VERSION ""

NS_ :

BS_:

BU_: CCU NIDU ITS EOP BMC BCB EVCC DCDC DCDC2 Tester DCU CCURT2 ZCUF ZCUL ZCUR ZCUT IPS RBM IBCS IDC CCU3 CCU4 AVAS FLLCM FRLCM RLLCMA RRLCMA RLLCMB RRLCMB PADS MFS PCU SRS EPS ECS AMP WHUD IMR FIMR ADC VIU RADARRR RADARRL RADARFR RADARFL RPC IFC PAS RADARFRT RADARR INU SBM WCM ETC TBOX DSM FLPDM FRPDM RLPDM RRPDM HVSMR TFOAR TROAR PLGM CCURT1 VDC RFR Rema1

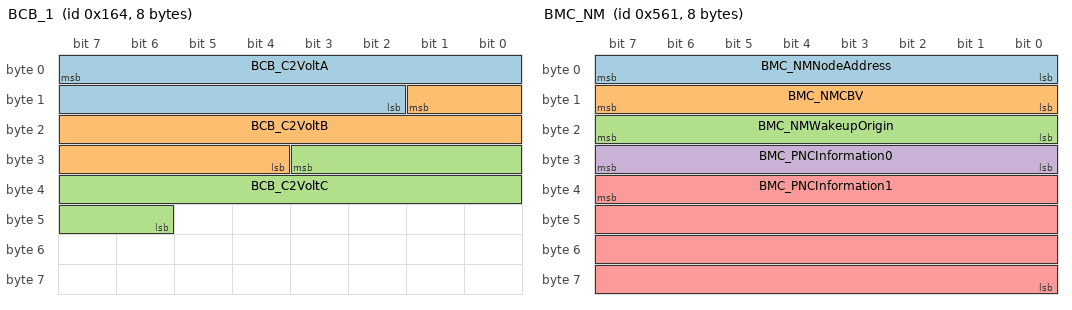
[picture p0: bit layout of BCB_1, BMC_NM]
BO_ 356 BCB_1: 8 BCB
 SG_ BCB_C2VoltA : 7|14@0+ (0.1,0) [0|1000] "V"  CCU,NIDU,BMC,DCU,CCURT1,VDC
 SG_ BCB_C2VoltB : 9|14@0+ (0.1,0) [0|1000] "V"  CCU,NIDU,BMC,DCU,CCURT1,VDC
 SG_ BCB_C2VoltC : 27|14@0+ (0.1,0) [0|1000] "V"  CCU,NIDU,BMC,DCU,CCURT1,VDC

BO_ 1025 BCB_2: 16 BCB
 SG_ BCB_2_CRC : 7|16@0+ (1,0) [0|65535] ""  CCU,NIDU,BMC,DCU,CCURT1,VDC
 SG_ BCB_2_Counter : 23|8@0+ (1,0) [0|255] ""  CCU,NIDU,BMC,DCU,CCURT1,VDC
 SG_ BCB_BoostRlyStK3 : 28|3@0+ (1,0) [0|7] ""  CCU,NIDU,BMC,DCU,CCURT1,VDC
 SG_ BCB_BoostRlyStK2 : 31|3@0+ (1,0) [0|7] ""  CCU,NIDU,BMC,DCU,CCURT1,VDC
 SG_ BCB_C2Temp1 : 25|9@0+ (1,-40) [-40|256] "degC"  NIDU,DCU
 SG_ BCB_C2Temp2 : 32|9@0+ (1,-40) [-40|256] "degC"  NIDU,DCU
 SG_ BCB_C2Temp3 : 55|9@0+ (1,-40) [-40|256] "degC"  NIDU,DCU
 SG_ BCB_Fault : 67|4@0+ (1,0) [0|15] ""  CCU,NIDU,BMC,DCU,CCURT1,VDC
 SG_ BCB_C2Temp4 : 62|9@0+ (1,-40) [-40|256] "degC"  NIDU,DCU

BO_ 408 BMC_1: 64 BMC
 SG_ BMC_1_CRC : 7|16@0+ (1,0) [0|65535] ""  CCU,NIDU,EVCC,DCDC,DCDC2,DCU,IPS,CCURT1,VDC
 SG_ BMC_1_Counter : 23|8@0+ (1,0) [0|255] ""  CCU,NIDU,EVCC,DCDC,DCDC2,DCU,IPS,CCURT1,VDC
 SG_ BMC_BattCurr : 24|16@0+ (0.1,-1000) [-1000|1000] "A"  CCU,NIDU,DCU,CCURT2,IDC,CCURT1,VDC
 SG_ BMC_DCUBattSt : 56|1@0+ (1,0) [0|1] ""  CCU,NIDU,DCDC,DCDC2,DCU,CCURT2,IPS,CCURT1,VDC
 SG_ BMC_BattVolt : 54|10@0+ (1,0) [0|1000] "V"  CCU,NIDU,EVCC,DCU,CCURT2,IDC,CCURT1,VDC
 SG_ BMC_BoostChgModeReq : 68|2@0+ (1,0) [0|3] ""  CCU,NIDU,DCU,CCURT2,CCURT1,VDC
 SG_ BMC_PwrDwnReq : 71|1@0+ (1,0) [0|1] ""  CCU,NIDU,DCDC,DCDC2,DCU,IPS,CCURT1,VDC
 SG_ BMC_BoostRlyK3St : 76|3@0+ (1,0) [0|7] ""  CCU,NIDU,DCU,CCURT2,CCURT1,VDC
 SG_ BMC_BoostRlyK2St : 97|3@0+ (1,0) [0|7] ""  CCU,NIDU,DCU,CCURT2,CCURT1,VDC
 SG_ BMC_DCVolt : 110|10@0+ (1,0) [0|1000] "V"  CCU,NIDU,DCU,CCURT2,CCURT1,VDC
 SG_ BMC_DriveBoostRlyK3Sts : 298|2@0+ (1,0) [0|3] ""  CCU,NIDU,DCU,CCURT1,VDC
 SG_ BMC_BoostRlyK3Sts : 301|3@0+ (1,0) [0|7] ""  CCU,NIDU,DCU,CCURT1,VDC
 SG_ BMC_C2VoltA : 391|10@0+ (1,0) [0|1000] "V"  CCU,NIDU,DCU,CCURT1,VDC
 SG_ BMC_C2VoltB : 397|10@0+ (1,0) [0|1000] "V"  CCU,NIDU,DCU,CCURT1,VDC
 SG_ BMC_DriveBoostRlyK2Sts : 409|2@0+ (1,0) [0|3] ""  CCU,NIDU,DCU,CCURT1,VDC
 SG_ BMC_C2VoltC : 403|10@0+ (1,0) [0|1000] "V"  CCU,NIDU,DCU,CCURT1,VDC
 SG_ BMC_BoostRlyK2Sts : 434|3@0+ (1,0) [0|7] ""  CCU,NIDU,DCU,CCURT1,VDC

BO_ 888 BMC_2: 64 BMC
 SG_ BMC_SepaHeatSt : 133|2@0+ (1,0) [0|3] ""  CCU,NIDU,IPS,CCURT1,VDC

BO_ 1095 BMC_20: 64 BMC
 SG_ BMC_RlyK3Req : 497|2@0+ (1,0) [0|3] ""  CCU,NIDU,BCB,DCU,CCURT1,VDC
 SG_ BMC_MainloopDischgReq : 505|2@0+ (1,0) [0|3] ""  CCU,NIDU,DCU,CCURT1,VDC
 SG_ BMC_C2DisChgSt : 507|2@0+ (1,0) [0|3] ""  CCU,NIDU,DCU,CCURT1,VDC
 SG_ BMC_BoostChgSt : 509|2@0+ (1,0) [0|3] ""  CCU,NIDU,DCU,CCURT1,VDC
 SG_ BMC_RlyK2Req : 511|2@0+ (1,0) [0|3] ""  CCU,NIDU,BCB,DCU,CCURT1,VDC

BO_ 1098 BMC_23: 64 BMC
 SG_ BMC_C2Temp1 : 471|9@0+ (1,-40) [-40|256] "degC"  CCU,NIDU,DCU,CCURT1,VDC
 SG_ BMC_C2Temp2 : 478|9@0+ (1,-40) [-40|256] "degC"  CCU,NIDU,DCU,CCURT1,VDC
 SG_ BMC_C2Temp3 : 485|9@0+ (1,-40) [-40|256] "degC"  CCU,NIDU,DCU,CCURT1,VDC
 SG_ BMC_BCBFault : 499|4@0+ (1,0) [0|15] ""  CCU,NIDU,DCU,CCURT1,VDC
 SG_ BMC_C2Temp4 : 492|9@0+ (1,-40) [-40|256] "degC"  CCU,NIDU,DCU,CCURT1,VDC

BO_ 812 BMC_BMS_3: 64 BMC
 SG_ BMS_DCCurrRx : 31|16@0+ (0.1,-1000) [-1000|1000] "A"  CCU,NIDU,BMC,DCU,CCURT2,CCURT1,VDC
 SG_ BMS_DCVoltRx : 47|16@0+ (0.1,0) [0|1000] "V"  CCU,NIDU,BMC,DCU,CCURT2,CCURT1,VDC
 SG_ BMS_AcChgVoltMax : 79|16@0+ (0.1,0) [0|6553.5] "V"  CCU,NIDU,BMC,DCU,CCURT1,VDC
 SG_ BMS_BoostChgModeReq : 149|2@0+ (1,0) [0|3] ""  CCU,NIDU,BMC,DCU,CCURT1,VDC
 SG_ BMS_CoolantTargTemp : 159|8@0+ (0.5,-40) [-40|87] "degC"  CCU,NIDU,BMC,DCU,CCURT2,CCURT1,VDC

BO_ 1377 BMC_NM: 8 BMC
 SG_ BMC_NMNodeAddress : 7|8@0+ (1,0) [0|255] ""  CCU,NIDU,ITS,EVCC,DCDC,DCDC2,DCU,IPS,CCURT1
 SG_ BMC_NMCBV : 15|8@0+ (1,0) [0|0] ""  CCU,NIDU,ITS,EVCC,DCDC,DCDC2,DCU,IPS,CCURT1
 SG_ BMC_NMWakeupOrigin : 23|8@0+ (1,0) [0|255] ""  CCU,NIDU,ITS,EVCC,DCDC,DCDC2,DCU,IPS,CCURT1
 SG_ BMC_PNCInformation0 : 31|8@0+ (1,0) [0|255] ""  CCU,NIDU,ITS,EVCC,DCDC,DCDC2,DCU,IPS,CCURT1
 SG_ BMC_PNCInformation1 : 39|32@0+ (1,0) [0|0] ""  CCU,NIDU,ITS,EVCC,DCDC,DCDC2,DCU,IPS,CCURT1

BO_ 616 CCU_1: 64 CCU
 SG_ CCU_1_CRC : 7|16@0+ (1,0) [0|65535] ""  NIDU,DCU,CCURT2,ZCUF,ZCUL,ZCUR,ZCUT,IPS,RBM,IBCS,IDC
 SG_ CCU_1_Counter : 23|8@0+ (1,0) [0|255] ""  NIDU,DCU,CCURT2,ZCUF,ZCUL,ZCUR,ZCUT,IPS,RBM,IBCS,IDC
 SG_ UMM_UsageModeSt : 26|3@0+ (1,0) [0|7] ""  NIDU,ITS,EOP,BMC,BCB,DCDC,DCDC2,DCU,CCURT2,ZCUF,ZCUL,ZCUR,ZCUT,IPS,RBM,IBCS,IDC,CCU3,CCU4,AVAS,FLLCM,FRLCM,RLLCMA,RRLCMA,RLLCMB,RRLCMB,PADS,MFS,PCU,SRS,EPS,ECS,AMP,WHUD,IMR,FIMR,ADC,VIU,RADARRR,RADARRL,RADARFR,RADARFL,RPC,IFC,PAS,RADARFRT,RADARR,INU,SBM,WCM,ETC,TBOX,DSM,FLPDM,FRPDM,RLPDM,RRPDM,HVSMR,TFOAR,TROAR,PLGM
 SG_ VMM_LastVehModeSt : 155|4@0+ (1,0) [0|15] ""  NIDU,ITS,EOP,BMC,DCDC,DCU,ZCUF,ZCUL,ZCUR,ZCUT,IPS,RBM,IBCS,IDC,AVAS,FLLCM,FRLCM,RLLCMA,RRLCMA,RLLCMB,RRLCMB,PADS,MFS,PCU,SRS,EPS,AMP,WHUD,ADC,VIU,RADARRR,RADARRL,RADARFR,RADARFL,RPC,IFC,RADARFRT,RADARR,INU,SBM,WCM,ETC,TBOX,DSM,FLPDM,FRPDM,RLPDM,RRPDM,HVSMR,TFOAR,TROAR
 SG_ VMM_VehModeSt : 159|4@0+ (1,0) [0|15] ""  NIDU,ITS,EOP,BMC,BCB,DCDC,DCDC2,DCU,CCURT2,ZCUF,ZCUL,ZCUR,ZCUT,IPS,RBM,IBCS,IDC,AVAS,FLLCM,FRLCM,RLLCMA,RRLCMA,RLLCMB,RRLCMB,PADS,MFS,PCU,SRS,EPS,ECS,AMP,WHUD,IMR,FIMR,ADC,VIU,RADARRR,RADARRL,RADARFR,RADARFL,RPC,IFC,RADARFRT,RADARR,INU,SBM,WCM,ETC,TBOX,DSM,FLPDM,FRPDM,RLPDM,RRPDM,HVSMR,TFOAR,TROAR,PLGM
 SG_ VMM_OTAModeSt : 167|2@0+ (1,0) [0|3] ""  NIDU,ITS,EOP,BMC,BCB,DCDC,DCDC2,DCU,CCURT2,ZCUF,ZCUL,ZCUR,ZCUT,IPS,RBM,IBCS,IDC,AVAS,FLLCM,FRLCM,RLLCMA,RRLCMA,RLLCMB,RRLCMB,PADS,MFS,PCU,SRS,EPS,ECS,AMP,WHUD,ADC,VIU,RADARRR,RADARRL,RADARFR,RADARFL,RPC,IFC,RADARFRT,RADARR,INU,SBM,WCM,ETC,TBOX,DSM,FLPDM,FRPDM,RLPDM,RRPDM,HVSMR,TFOAR,TROAR
 SG_ Time_Year : 343|8@0+ (1,2000) [2000|2255] "y"  NIDU,ITS,EOP,BMC,DCU,CCURT2,ZCUF,ZCUL,ZCUR,ZCUT,IPS,RBM,IBCS,FLLCM,FRLCM,RLLCMA,RRLCMA,RLLCMB,RRLCMB,MFS,PCU,SRS,EPS,ECS,AMP,IMR,FIMR,ADC,VIU,RPC,IFC,PAS,INU,DSM,FLPDM,FRPDM,RLPDM,RRPDM,HVSMR,TFOAR,TROAR,CCURT1
 SG_ Time_Month : 351|4@0+ (1,0) [0|12] "m"  NIDU,ITS,EOP,BMC,DCU,CCURT2,ZCUF,ZCUL,ZCUR,ZCUT,IPS,RBM,IBCS,FLLCM,FRLCM,RLLCMA,RRLCMA,RLLCMB,RRLCMB,MFS,PCU,SRS,EPS,ECS,AMP,IMR,FIMR,ADC,VIU,RPC,IFC,PAS,INU,DSM,FLPDM,FRPDM,RLPDM,RRPDM,HVSMR,TFOAR,TROAR,CCURT1
 SG_ Time_Hour : 358|5@0+ (1,0) [0|23] "h"  NIDU,ITS,EOP,BMC,DCU,CCURT2,ZCUF,ZCUL,ZCUR,ZCUT,IPS,RBM,IBCS,FLLCM,FRLCM,RLLCMA,RRLCMA,RLLCMB,RRLCMB,MFS,PCU,SRS,EPS,ECS,AMP,IMR,FIMR,ADC,VIU,RPC,IFC,PAS,INU,DSM,FLPDM,FRPDM,RLPDM,RRPDM,HVSMR,TFOAR,TROAR,CCURT1
 SG_ Time_Day : 347|5@0+ (1,0) [1|31] "d"  NIDU,ITS,EOP,BMC,DCU,CCURT2,ZCUF,ZCUL,ZCUR,ZCUT,IPS,RBM,IBCS,FLLCM,FRLCM,RLLCMA,RRLCMA,RLLCMB,RRLCMB,MFS,PCU,SRS,EPS,ECS,AMP,IMR,FIMR,ADC,VIU,RPC,IFC,PAS,INU,DSM,FLPDM,FRPDM,RLPDM,RRPDM,HVSMR,TFOAR,TROAR,CCURT1
 SG_ Time_Min : 353|6@0+ (1,0) [0|59] "min"  NIDU,ITS,EOP,BMC,DCU,CCURT2,ZCUF,ZCUL,ZCUR,ZCUT,IPS,RBM,IBCS,FLLCM,FRLCM,RLLCMA,RRLCMA,RLLCMB,RRLCMB,MFS,PCU,SRS,EPS,ECS,AMP,IMR,FIMR,ADC,VIU,RPC,IFC,PAS,INU,DSM,FLPDM,FRPDM,RLPDM,RRPDM,HVSMR,TFOAR,TROAR,CCURT1
 SG_ Time_Sec : 363|6@0+ (1,0) [0|59] "s"  NIDU,ITS,EOP,BMC,DCU,CCURT2,ZCUF,ZCUL,ZCUR,ZCUT,IPS,RBM,IBCS,FLLCM,FRLCM,RLLCMA,RRLCMA,RLLCMB,RRLCMB,MFS,PCU,SRS,EPS,ECS,AMP,IMR,FIMR,ADC,VIU,RPC,IFC,PAS,INU,DSM,FLPDM,FRPDM,RLPDM,RRPDM,HVSMR,TFOAR,TROAR,CCURT1

BO_ 816 CCU_2: 64 CCU
 SG_ HVAC_PTCPwrConsmp : 65|10@0+ (10,0) [0|10200] "W"  NIDU,CCURT2,ZCUR,IPS,IDC,CCURT1
 SG_ HVAC_CorrectedExterTemp : 135|8@0+ (0.5,-40) [-40|87.5] "degC"  NIDU,ITS,BMC,DCU,CCURT2,ZCUL,ZCUR,ZCUT,IBCS,IDC,ECS,ADC,VIU,PAS,TBOX,DSM,FLPDM,FRPDM,RLPDM,RRPDM,TFOAR,TROAR,CCURT1
 SG_ HVAC_PTCHeatingReq : 142|7@0+ (1,0) [0|100] "%"  NIDU,DCU,ZCUF,ZCUL,CCURT1
 SG_ HVAC_CorrectedExterTempVD : 143|1@0+ (1,0) [0|1] ""  NIDU,ITS,BMC,DCU,CCURT2,ZCUL,ZCUR,ZCUT,IBCS,IDC,ADC,VIU,PAS,DSM,FLPDM,FRPDM,RLPDM,RRPDM,TFOAR,TROAR,CCURT1
 SG_ HVAC_PTCSt : 168|1@0+ (1,0) [0|1] ""  NIDU,DCU,CCURT2,CCURT1
 SG_ HVAC_ECPPwrConsump : 367|11@0+ (10,0) [0|20320] "W"  NIDU,DCU,CCURT2,IPS,IDC,CCURT1
 SG_ HVAC_PTCOnReq : 427|2@0+ (1,0) [0|3] ""  NIDU,DCU,ZCUF,ZCUL,IPS

BO_ 615 CCU_BCS_1_C: 64 CCU
 SG_ BCS_1_CRC : 7|16@0+ (1,0) [0|65535] ""  NIDU,DCU,ZCUF,ZCUL,ZCUR,ZCUT,IDC,ADC,VIU,IFC,INU
 SG_ BCS_1_Counter : 23|8@0+ (1,0) [0|255] ""  NIDU,DCU,ZCUF,ZCUL,ZCUR,ZCUT,IDC,ADC,VIU,IFC,INU
 SG_ BCS_FLWheelSpdVD : 34|1@0+ (1,0) [0|1] ""  NIDU,DCU,ZCUF,ZCUL,ZCUR,ZCUT,ADC,VIU,IFC,INU
 SG_ BCS_FLWheelSpd : 31|13@0+ (0.05625,0) [0|240] "km/h"  NIDU,DCU,ZCUF,ZCUL,ZCUR,ZCUT,IDC,ADC,VIU,IFC,INU
 SG_ BCS_FRWheelSpdVD : 50|1@0+ (1,0) [0|1] ""  NIDU,DCU,ZCUF,ZCUL,ZCUR,ZCUT,ADC,VIU,IFC,INU
 SG_ BCS_FRWheelSpd : 47|13@0+ (0.05625,0) [0|240] "km/h"  NIDU,DCU,ZCUF,ZCUL,ZCUR,ZCUT,IDC,ADC,VIU,IFC,INU
 SG_ BCS_RLWheelSpdVD : 66|1@0+ (1,0) [0|1] ""  NIDU,DCU,ZCUF,ZCUL,ZCUR,ZCUT,ADC,VIU,IFC,INU
 SG_ BCS_RLWheelSpd : 63|13@0+ (0.05625,0) [0|240] "km/h"  NIDU,DCU,ZCUF,ZCUL,ZCUR,ZCUT,IDC,ADC,VIU,IFC,INU
 SG_ BCS_RRWheelSpdVD : 82|1@0+ (1,0) [0|1] ""  NIDU,DCU,ZCUF,ZCUL,ZCUR,ZCUT,ADC,VIU,IFC,INU
 SG_ BCS_RRWheelSpd : 79|13@0+ (0.05625,0) [0|240] "km/h"  NIDU,DCU,ZCUF,ZCUL,ZCUR,ZCUT,IDC,ADC,VIU,IFC,INU
 SG_ BCS_HDCCtrlSt : 93|2@0+ (1,0) [0|3] ""  NIDU,DCU,IDC,ADC,VIU,IFC
 SG_ BCS_HHCCtrlSt : 95|1@0+ (1,0) [0|1] ""  NIDU,DCU,IFC
 SG_ BCS_AVHSt : 152|1@0+ (1,0) [0|1] ""  NIDU,DCU,ZCUF,ZCUL,ZCUR,ZCUT,IDC,ADC,VIU,IFC,SBM
 SG_ IPB_InputRodStroke : 363|10@0+ (0.05,-5) [-5|46.15] "mm"  NIDU,DCU,IDC,AMP,ADC,VIU,IFC
 SG_ IPB_PlungerPressureSt : 376|1@0+ (1,0) [0|1] ""  NIDU,DCU,ZCUF,ZCUL,ZCUR,ZCUT,RBM,ADC,VIU,IFC
 SG_ IPB_InputRodStrokeSt : 379|1@0+ (1,0) [0|1] ""  NIDU,DCU,IDC,AMP,ADC,VIU,IFC
 SG_ IPB_PlungerPressure : 391|12@0+ (0.3,-5) [-5|301.9] "bar"  NIDU,DCU,ZCUF,ZCUL,ZCUR,ZCUT,RBM,ADC,VIU,IFC

BO_ 352 CCU_BCS_2_C: 64 CCU
 SG_ BCS_2_CRC : 7|16@0+ (1,0) [0|65535] ""  NIDU,DCU,ZCUF,ZCUL,ZCUR,ZCUT,IDC,FLLCM,FRLCM,RLLCMA,RRLCMA,RLLCMB,RRLCMB,ADC,VIU,IFC,INU,FLPDM,FRPDM,RLPDM,RRPDM,TFOAR,TROAR
 SG_ BCS_2_Counter : 23|8@0+ (1,0) [0|255] ""  NIDU,DCU,ZCUF,ZCUL,ZCUR,ZCUT,IDC,ADC,VIU,IFC,INU
 SG_ BCS_EBDActiveSt : 32|1@0+ (1,0) [0|1] ""  NIDU,DCU,ZCUF,ZCUL,ZCUR,ZCUT,ADC,VIU,IFC
 SG_ BCS_VehSpd : 31|13@0+ (0.05625,0) [0|240] "km/h"  NIDU,ITS,DCU,ZCUF,ZCUL,ZCUR,ZCUT,IDC,FLLCM,FRLCM,RLLCMA,RRLCMA,RLLCMB,RRLCMB,MFS,PCU,AMP,IMR,FIMR,ADC,VIU,IFC,PAS,INU,FLPDM,FRPDM,RLPDM,RRPDM,TFOAR,TROAR,PLGM
 SG_ BCS_VDCFaultSt : 41|1@0+ (1,0) [0|1] ""  NIDU,DCU,ZCUF,ZCUL,ZCUR,ZCUT,IDC,ADC,VIU,IFC
 SG_ BCS_VDCActiveSt : 42|1@0+ (1,0) [0|1] ""  NIDU,DCU,ZCUF,ZCUL,ZCUR,ZCUT,IDC,ADC,VIU,IFC
 SG_ BCS_TCSFaultSt : 43|1@0+ (1,0) [0|1] ""  NIDU,DCU,ZCUF,ZCUL,ZCUR,ZCUT,IDC,ADC,VIU,IFC
 SG_ BCS_TCSActiveSt : 44|1@0+ (1,0) [0|1] ""  NIDU,DCU,ZCUF,ZCUL,ZCUR,ZCUT,IDC,ADC,VIU,IFC
 SG_ BCS_ABSFaultSt : 45|1@0+ (1,0) [0|1] ""  NIDU,DCU,ZCUF,ZCUL,ZCUR,ZCUT,IDC,ADC,VIU,IFC
 SG_ BCS_ABSActiveSt : 46|1@0+ (1,0) [0|1] ""  NIDU,DCU,ZCUF,ZCUL,ZCUR,ZCUT,ADC,VIU,IFC,TBOX
 SG_ BCS_EBDFaultSt : 47|1@0+ (1,0) [0|1] ""  NIDU,DCU,ZCUF,ZCUL,ZCUR,ZCUT,IDC,ADC,VIU,IFC
 SG_ BCS_EngTorqDecActiveSt : 71|1@0+ (1,0) [0|1] ""  NIDU,DCU,ZCUF,ZCUL,ZCUR,ZCUT,ADC,VIU,IFC
 SG_ BCS_RegenModuleActive : 79|1@0+ (1,0) [0|1] ""  NIDU,DCU,VIU
 SG_ BCS_DMCTarSpdFA : 135|16@0+ (1,-32767) [-32767|32768] "rpm"  NIDU,DCU
 SG_ BCS_DMCCtrModeFA : 151|3@0+ (1,0) [0|7] "NA"  NIDU,DCU
 SG_ BCS_DMCVariant : 148|6@0+ (1,0) [0|63] "NA"  NIDU,DCU
 SG_ BCS_DMCTarSpdRA : 167|16@0+ (1,-32767) [-32767|32768] "rpm"  NIDU,DCU
 SG_ BCS_DMCCtrModeRA : 183|3@0+ (1,0) [0|7] "NA"  NIDU,DCU
 SG_ BCS_EngTorqDecActiveStRA : 233|1@0+ (1,0) [0|1] ""  NIDU,DCU,ADC,VIU,IFC

BO_ 363 CCU_EPS_1_C: 64 CCU
 SG_ EPS_SteeringAngle : 55|16@0+ (0.1,-780) [-780|779.9] "deg"  NIDU,DCU,ZCUR,SBM
 SG_ EPS_SteeringAngleVD : 71|1@0+ (1,0) [0|1] ""  NIDU,DCU,ZCUR,SBM

BO_ 351 CCU_IDC_2: 64 CCU
 SG_ ACU_ACChgCurCfg : 151|5@0+ (1,0) [0|31] ""  NIDU,IPS

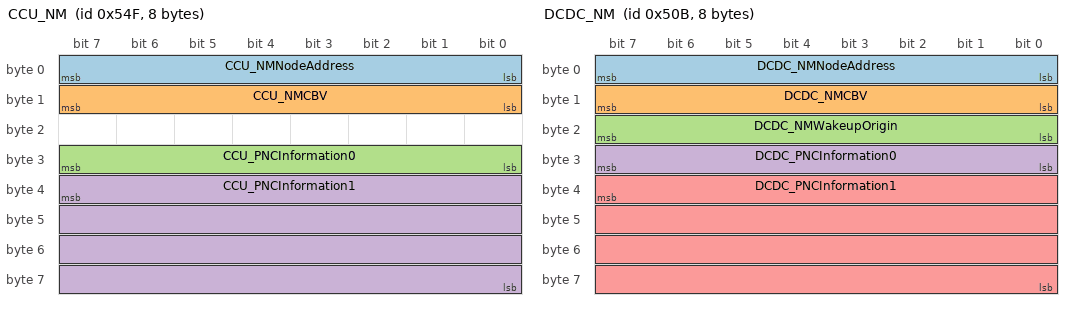
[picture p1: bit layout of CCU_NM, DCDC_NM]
BO_ 1359 CCU_NM: 8 CCU
 SG_ CCU_NMNodeAddress : 7|8@0+ (1,0) [0|255] ""  NIDU,ITS,BMC,EVCC,DCDC,DCDC2,DCU,ZCUL,ZCUR,IPS,RBM,IBCS,IDC,MFS,PCU,ECS,AMP,ADC,VIU,IFC,TBOX,FLPDM,FRPDM,RLPDM,RRPDM,PLGM,CCURT1
 SG_ CCU_NMCBV : 15|8@0+ (1,0) [0|0] ""  NIDU,ITS,BMC,EVCC,DCDC,DCDC2,DCU,ZCUL,ZCUR,IPS,RBM,IBCS,IDC,MFS,PCU,ECS,ADC,VIU,IFC,TBOX,FLPDM,FRPDM,RLPDM,RRPDM,PLGM,CCURT1
 SG_ CCU_PNCInformation0 : 31|8@0+ (1,0) [0|255] ""  NIDU,ITS,BMC,EVCC,DCDC,DCDC2,DCU,ZCUL,ZCUR,IPS,RBM,IBCS,IDC,MFS,PCU,ECS,ADC,VIU,IFC,TBOX,FLPDM,FRPDM,RLPDM,RRPDM,PLGM,CCURT1
 SG_ CCU_PNCInformation1 : 39|32@0+ (1,0) [0|0] ""  NIDU,ITS,BMC,EVCC,DCU,ZCUL,ZCUR,IPS,RBM,IBCS,IDC,MFS,PCU,ECS,ADC,VIU,IFC,TBOX,FLPDM,FRPDM,RLPDM,RRPDM,PLGM,CCURT1

BO_ 290 CCU_PowerOn: 64 CCU
 SG_ IPDS_RearEOPPowerSup : 131|2@0+ (1,0) [0|3] ""  NIDU,DCU,ZCUR,ZCUT
 SG_ IPDS_KL15T1PowerSup : 169|2@0+ (1,0) [0|3] ""  NIDU,DCU,ZCUR,ZCUT,CCURT1,VDC
 SG_ IPDS_BCBPowerSup : 271|2@0+ (1,0) [0|3] ""  NIDU,BMC,BCB,DCU,ZCUR,ZCUT
 SG_ IPDS_FrontEOPPowerSup : 283|2@0+ (1,0) [0|3] ""  NIDU,DCU,ZCUF,ZCUL

BO_ 909 CCU_ZCU_1: 64 CCU
 SG_ EPB_ActuatorSt_L : 275|4@0+ (1,0) [0|15] ""  NIDU,DCU
 SG_ EPB_ActuatorSt_R : 279|4@0+ (1,0) [0|15] ""  NIDU,DCU
 SG_ EPB_SysSt : 287|3@0+ (1,0) [0|7] ""  NIDU,DCU

BO_ 902 CCU_ZCUT_5: 64 CCU
 SG_ IPDS_RearMotorPowerSt : 25|1@0+ (1,0) [0|1] ""  NIDU,EOP,BMC,DCU
 SG_ IPDS_RearEOPPowerSt : 39|1@0+ (1,0) [0|1] ""  NIDU,DCU
 SG_ IPDS_RearMotorPowerFaultSt : 95|3@0+ (1,0) [0|7] ""  NIDU,DCU
 SG_ IPDS_RearEOPPowerFaultSt : 103|3@0+ (1,0) [0|7] ""  NIDU,DCU
 SG_ IPDS_KL15T1PowerSt : 136|1@0+ (1,0) [0|1] ""  NIDU,DCU
 SG_ IPDS_BCBPowerFaultSt : 171|3@0+ (1,0) [0|7] ""  NIDU,BMC,BCB,DCU
 SG_ IPDS_BCBPowerSt : 172|1@0+ (1,0) [0|1] ""  NIDU,BMC,BCB,DCU

BO_ 1291 DCDC_NM: 8 DCDC
 SG_ DCDC_NMNodeAddress : 7|8@0+ (1,0) [0|255] ""  CCU,NIDU,ITS,BMC,EVCC,DCDC2,DCU,IPS,CCURT1
 SG_ DCDC_NMCBV : 15|8@0+ (1,0) [0|0] ""  CCU,NIDU,ITS,BMC,EVCC,DCDC2,DCU,IPS,CCURT1
 SG_ DCDC_NMWakeupOrigin : 23|8@0+ (1,0) [0|255] ""  CCU,NIDU,ITS,BMC,EVCC,DCDC2,DCU,IPS,CCURT1
 SG_ DCDC_PNCInformation0 : 31|8@0+ (1,0) [0|255] ""  CCU,NIDU,ITS,BMC,EVCC,DCDC2,DCU,IPS,CCURT1
 SG_ DCDC_PNCInformation1 : 39|32@0+ (1,0) [0|0] ""  CCU,NIDU,ITS,BMC,EVCC,DCDC2,DCU,IPS,CCURT1

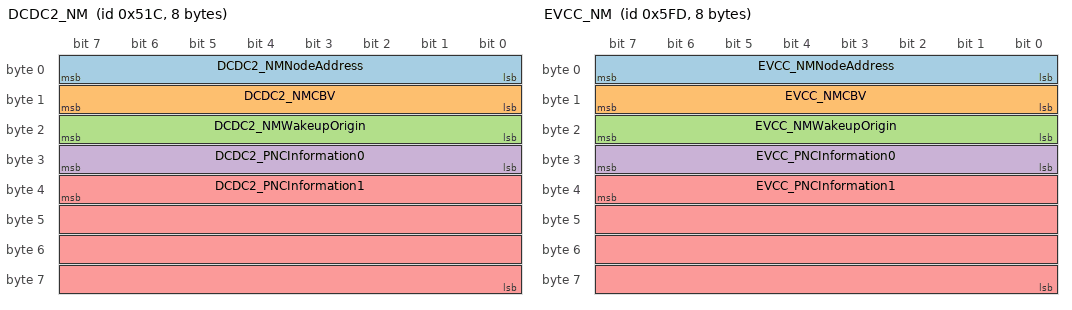
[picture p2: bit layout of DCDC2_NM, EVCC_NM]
BO_ 1308 DCDC2_NM: 8 DCDC2
 SG_ DCDC2_NMNodeAddress : 7|8@0+ (1,0) [0|255] ""  CCU,NIDU,ITS,BMC,EVCC,DCDC,DCU,IPS,CCURT1
 SG_ DCDC2_NMCBV : 15|8@0+ (1,0) [0|0] ""  CCU,NIDU,ITS,BMC,EVCC,DCDC,DCU,IPS,CCURT1
 SG_ DCDC2_NMWakeupOrigin : 23|8@0+ (1,0) [0|255] ""  CCU,NIDU,ITS,BMC,EVCC,DCDC,DCU,IPS,CCURT1
 SG_ DCDC2_PNCInformation0 : 31|8@0+ (1,0) [0|255] ""  CCU,NIDU,ITS,BMC,EVCC,DCDC,DCU,IPS,CCURT1
 SG_ DCDC2_PNCInformation1 : 39|32@0+ (1,0) [0|0] ""  CCU,NIDU,ITS,BMC,EVCC,DCDC,DCU,IPS,CCURT1

BO_ 368 DCU_1: 64 NIDU
 SG_ DCU_1_CRC : 7|16@0+ (1,0) [0|65535] ""  CCU,EOP,BMC,CCURT2,CCURT1,VDC
 SG_ DCU_1_Counter : 23|8@0+ (1,0) [0|255] ""  CCU,EOP,BMC,CCURT2,CCURT1,VDC
 SG_ DCU_RotSpdAct : 31|16@0+ (1,-32767) [-32767|32766] "rpm"  CCU,EOP,CCURT2,PCU,CCURT1,VDC
 SG_ DCU_IdcAct : 47|11@0+ (1,-1023) [-1023|1024] "A"  CCU,BMC,CCURT2,CCURT1,VDC
 SG_ DCU_CCUEOPPowerSup : 57|2@0+ (1,0) [0|3] ""  CCU,EOP,CCURT1,VDC
 SG_ DCU_ErrorLv3St : 58|1@0+ (1,0) [0|1] ""  CCU
 SG_ DCU_UdcAct : 52|10@0+ (1,0) [0|1023] "V"  CCU,BMC,BCB,CCURT2,CCURT1,VDC
 SG_ DCU_FusastSafePathReq : 66|3@0+ (1,0) [0|7] ""  CCU
 SG_ DCU_FusaQDisChargeReq : 67|1@0+ (1,0) [0|1] ""  CCU
 SG_ DCU_FusaModeSt : 71|4@0+ (1,0) [0|15] ""  CCU
 SG_ DCU_ModeSt : 79|4@0+ (1,0) [0|15] ""  CCU,BMC,CCURT2,CCURT1,VDC
 SG_ DCU_HvilSt : 81|2@0+ (1,0) [0|3] ""  CCU,TBOX,CCURT1,VDC
 SG_ DCU_TorqMax : 75|10@0+ (1,0) [0|1023] "Nm"  CCU,CCURT2,RBM,IBCS,CCURT1,VDC
 SG_ DCU_TorqMin : 95|10@0+ (1,-1023) [-1023|0] "Nm"  CCU,CCURT2,RBM,IBCS,CCURT1,VDC
 SG_ DCU_DMCInternalInputQF : 107|1@0+ (1,0) [0|1] ""  CCU
 SG_ DCU_SelfTorqMax : 101|10@0+ (1,0) [0|1023] "Nm"  CCU,CCURT2,CCURT1,VDC
 SG_ DCU_DstActive : 112|1@0+ (1,0) [0|1] ""  CCU,CCURT2,CCURT1,VDC
 SG_ DCU_SelfTorqMin : 106|10@0+ (1,-1023) [-1023|0] "Nm"  CCU,CCURT2,CCURT1,VDC
 SG_ DCU_DiagErrCode : 125|6@0+ (1,0) [0|63] ""  CCU,CCURT1,VDC
 SG_ DCU_GateDrvSt : 127|2@0+ (1,0) [0|3] ""  CCU
 SG_ DCU_DMCInternalInit : 135|1@0+ (1,0) [0|1] ""  CCU
 SG_ DCU_DMCOperationStToBCS : 139|3@0+ (1,0) [0|7] ""  CCU,CCURT2,RBM,IBCS
 SG_ DCU_DMCInternalTorqSet : 134|11@0+ (1,-1023) [-1023|1024] "Nm"  CCU
 SG_ DCU_FusastPWMEna : 152|1@0+ (1,0) [0|1] ""  CCU
 SG_ DCU_DMCoutputTorqToBCS : 136|16@0+ (1,-30000) [-30000|30000] "Nm"  CCU,CCURT2,RBM,IBCS
 SG_ DCU_DMCVersionInfoToBCS : 167|8@0+ (1,0) [0|255] ""  CCU,CCURT2,RBM,IBCS
 SG_ DCU_DMCVariantInfoToBCS : 175|6@0+ (1,0) [0|63] ""  CCU,CCURT2,RBM,IBCS
 SG_ DCU_TorqAct : 169|13@0+ (0.2,-819) [-819|819] "Nm"  CCU,CCURT2,IDC,CCURT1,VDC
 SG_ DCU_EOP_SpdSet : 188|12@0+ (1,0) [0|4000] "rpm"  CCU,EOP
 SG_ DCU_FusaErrCode : 192|6@0+ (1,0) [0|63] ""  CCU
 SG_ DCU_FusaTorqAct : 202|13@0+ (0.2,-819) [-819|819] "Nm"  CCU
 SG_ DCU_FusaRotSpdAct : 231|16@0+ (1,-32767) [-32767|32766] "rpm"  CCU
 SG_ DCU_Fault6 : 247|30@0+ (1,0) [0|1073741823] ""  CCU
 SG_ DCU_Fault3 : 265|30@0+ (1,0) [0|1073741823] ""  CCU
 SG_ DCU_Fault2 : 299|30@0+ (1,0) [0|1073741823] ""  CCU
 SG_ DCU_TrefFinal : 333|11@0+ (1,-1000) [-1000|1047] ""  CCU
 SG_ DCU_Iq : 338|15@0+ (0.1,-1500) [-1500|1776.7] ""  CCU
 SG_ DCU_Id : 355|15@0+ (0.1,-1500) [-1500|1776.7] ""  CCU
 SG_ DCU_iCurqRef : 372|15@0+ (0.1,-1500) [-1500|1776.7] ""  CCU
 SG_ DCU_iCurdRef : 389|15@0+ (0.1,-1500) [-1500|1776.7] ""  CCU
 SG_ DCU_1_FreshnessValue : 455|16@0+ (1,0) [0|255] ""  Tester
 SG_ DCU_1_MAC_Check : 471|48@0+ (1,0) [0|255] ""  Tester

BO_ 864 DCU_2: 64 NIDU
 SG_ DCU_2_CRC : 7|16@0+ (1,0) [0|65535] ""  CCU,CCURT1,VDC
 SG_ DCU_2_Counter : 23|8@0+ (1,0) [0|255] ""  CCU,CCURT1,VDC
 SG_ DCU_BoostChgPwrMax : 31|7@0+ (1,0) [0|120] "kW"  CCU,CCURT1,VDC
 SG_ DCU_AHF_ActPwr : 24|10@0+ (20,0) [0|20460] "W"  CCU,CCURT1,VDC
 SG_ DCU_BoostCurrMax : 55|8@0+ (1,0) [0|255] "A"  CCU,CCURT1,VDC
 SG_ DCU_OffsetCalInd : 64|1@0+ (1,0) [0|1] ""  CCU,CCURT1,VDC
 SG_ DCU_bReadyHV : 65|1@0+ (1,0) [0|1] ""  CCU
 SG_ DCU_bDiagReq : 66|1@0+ (1,0) [0|1] ""  CCU
 SG_ DCU_TypeSt : 70|4@0+ (1,0) [0|15] ""  CCU,CCURT1,VDC
 SG_ DCU_RemoteDiagCode : 56|2@0+ (1,0) [0|3] ""  CCU
 SG_ DCU_DisChgPwrMax : 79|7@0+ (1,0) [0|120] "kW"  CCU,CCURT1,VDC
 SG_ DCU_InvtTemp : 72|8@0+ (1,-40) [-40|215] "degC"  CCU,CCURT1,VDC
 SG_ DCU_SysTempOvrInd : 90|1@0+ (1,0) [0|1] ""  CCU,IDC
 SG_ DCU_VoltageT30 : 80|6@0+ (0.5,0) [0|31.5] "V"  CCU
 SG_ DCU_RotTemp : 89|9@0+ (1,-40) [-40|470] "degC"  CCU,CCURT1,VDC
 SG_ DCU_FaultLampInd : 106|1@0+ (1,0) [0|1] ""  CCU,CCURT2,IDC,CCURT1,VDC
 SG_ DCU_CooltReq : 96|6@0+ (0.25,0) [0|15.5] "L/min"  CCU,CCURT1,VDC
 SG_ DCU_StatTemp : 105|9@0+ (1,-40) [-40|470] "degC"  CCU,CCURT1,VDC
 SG_ DCU_ErrNoticeOperationFlag : 120|1@0+ (1,0) [0|1] ""  CCU,IDC
 SG_ DCU_TempCoolant : 112|8@0+ (1,-40) [-40|215] "degC"  CCU,CCURT2,CCURT1,VDC
 SG_ DCU_Err2NoticeFlag : 132|1@0+ (1,0) [0|1] ""  CCU,IDC
 SG_ DCU_ErrNotice : 135|3@0+ (1,0) [0|7] ""  CCU,IDC
 SG_ DCU_K2RlyAdhmode : 139|1@0+ (1,0) [0|1] ""  CCU,BMC,BCB,CCURT1,VDC
 SG_ DCU_BuckCurrMax : 131|8@0+ (1,0) [0|255] "A"  CCU,CCURT1,VDC
 SG_ DCU_Fault5 : 138|30@0+ (1,0) [0|1073741823] ""  CCU
 SG_ DCU_TEL_UdcAct : 181|14@0+ (0.1,0) [0|1000] "V"  CCU,TBOX
 SG_ DCU_TEL_MotorNumOrder : 194|3@0+ (1,0) [0|7] ""  CCU,TBOX
 SG_ DCU_TEL_ECUTempOvrErr : 195|1@0+ (1,0) [0|1] ""  CCU,TBOX
 SG_ DCU_TEL_MotTempOvrErr : 196|1@0+ (1,0) [0|1] ""  CCU,TBOX
 SG_ DCU_TEL_MotorNumTotal : 199|3@0+ (1,0) [0|7] ""  CCU,TBOX
 SG_ DCU_TEL_InvtTemp : 207|8@0+ (1,-40) [-40|215] "deg"  CCU,TBOX
 SG_ DCU_TEL_RotSpdAct : 215|16@0+ (1,-20000) [-20000|45535] "rpm"  CCU,TBOX
 SG_ DCU_TEL_TorqAct : 231|16@0+ (0.1,-2000) [-2000|4553.5] "Nm"  CCU,TBOX
 SG_ DCU_TEL_StatTemp : 247|8@0+ (1,-40) [-40|215] "deg"  CCU,TBOX
 SG_ DCU_TEL_CurrActAmend : 255|16@0+ (0.1,-1000) [-1000|1000] "A"  CCU,TBOX
 SG_ DCU_TEL_BattCurr : 271|16@0+ (0.1,-1000) [-1000|1000] "A"  CCU,TBOX
 SG_ DCU_TEL_ModeSt : 293|3@0+ (1,0) [0|7] ""  CCU,TBOX
 SG_ DCU_FusaFaultInfo7 : 303|30@0+ (1,0) [0|1073741823] ""  CCU,CCURT1,VDC
 SG_ DCU_FusaFaultInfo8 : 321|30@0+ (1,0) [0|1073741823] ""  CCU,CCURT1,VDC
 SG_ DCU_IgnitionSt : 439|1@0+ (1,0) [0|1] ""  CCU
 SG_ DCU_Fault4 : 455|30@0+ (1,0) [0|1073741823] ""  CCU
 SG_ DCU_Fault1 : 473|30@0+ (1,0) [0|1073741823] ""  CCU

BO_ 875 DCU_3: 64 NIDU
 SG_ DCU_3_CRC : 7|16@0+ (1,0) [0|65535] ""  CCU,CCURT1,VDC
 SG_ DCU_3_Counter : 23|8@0+ (1,0) [0|255] ""  CCU,CCURT1,VDC
 SG_ DCU_PTCDownShiftSt : 29|1@0+ (1,0) [0|1] ""  CCU,CCURT1,VDC
 SG_ DCU_PTCUpShiftSt : 30|1@0+ (1,0) [0|1] ""  CCU,CCURT1,VDC
 SG_ DCU_PTCHeatPower : 28|10@0+ (10,0) [0|10200] "W"  CCU,CCURT1,VDC
 SG_ DCU_PTCHeatCurrent : 34|11@0+ (0.1,-102.3) [-102.3|102.3] "A"  CCU,CCURT1,VDC
 SG_ DCU_PTCFault : 55|16@0+ (1,0) [0|65536] ""  CCU,CCURT1,VDC
 SG_ DCU_AHFDownShiftSt : 69|1@0+ (1,0) [0|1] ""  CCU,CCURT1,VDC
 SG_ DCU_AHFUpShiftSt : 70|1@0+ (1,0) [0|1] ""  CCU,CCURT1,VDC
 SG_ DCU_PTCInterTemp : 68|9@0+ (1,-40) [-40|471] "degC"  CCU,CCURT1,VDC
 SG_ DCU_PTCModeSt : 83|4@0+ (1,0) [0|15] ""  CCU,CCURT1,VDC
 SG_ DCU_PTCMOSTemp : 75|8@0+ (1,-40) [-40|215] "degC"  CCU,CCURT1,VDC
 SG_ DCU_FPWMMultiple : 91|4@0+ (1,0) [0|15] ""  CCU,CCURT1,VDC
 SG_ DCU_AHFModeSt : 95|4@0+ (1,0) [0|15] ""  CCU,CCURT1,VDC
 SG_ DCU_AHFPwrMax : 100|13@0+ (10,0) [0|81910] "W"  CCU,CCURT1,VDC
 SG_ DCU_AHFPwrMin : 116|13@0+ (10,0) [0|81910] "W"  CCU,CCURT1,VDC
 SG_ DCU_AHFCurrentReq : 130|11@0+ (1,0) [0|2047] "A"  CCU,CCURT1,VDC
 SG_ DCU_AHFCurrentAct : 146|11@0+ (1,0) [0|2047] "A"  CCU,CCURT1,VDC
 SG_ DCU_MotorTempEst : 167|8@0+ (1,-40) [-40|215] "degC"  CCU,CCURT1,VDC
 SG_ DCU_RotorPosn : 175|12@0+ (1,0) [0|4095] ""  CCU,CCURT1,VDC
 SG_ DCU_AHFPowerEst : 177|13@0+ (10,0) [0|81910] "W"  CCU,CCURT1,VDC
 SG_ DCU_AHFTorqueReq : 195|12@0+ (0.2,-409) [-409|409] "Nm"  CCU,CCURT1,VDC
 SG_ DCU_AHFTorqueAct : 211|12@0+ (0.2,-409) [-409|409] "Nm"  CCU,CCURT1,VDC

BO_ 2683306021 DCU_DEBUG_1: 64 NIDU
 SG_ DCU_EOP_OilTempAct : 7|8@0+ (1,-40) [-40|180] "degC"  Tester
 SG_ DCU_OffsetAngleCal : 15|16@0+ (1,0) [0|65535] ""  Tester
 SG_ DCU_Hwversion_Debug : 31|16@0+ (1,0) [0|65535] ""  Tester
 SG_ DCU_Swversion_Debug : 47|16@0+ (1,0) [0|65535] ""  Tester
 SG_ DCU_SwVerExt_Debug : 63|32@0+ (1,0) [0|4294967295] ""  Tester
 SG_ DCU_StoreDataSt : 93|2@0+ (1,0) [0|3] ""  Tester
 SG_ DCU_Ignition : 94|1@0+ (1,0) [0|1] ""  Tester
 SG_ DCU_Debug_1Bit_1 : 95|1@0+ (1,0) [0|1] ""  Tester
 SG_ DCU_OffsetAngle_Debug : 91|12@0+ (1,0) [0|4095] ""  Tester
 SG_ DCU_OffsetCalSt : 114|2@0+ (1,0) [0|3] ""  Tester
 SG_ DCU_SendDataSt : 115|1@0+ (1,0) [0|1] ""  Tester
 SG_ DCU_BootSV_Debug : 111|12@0+ (1,0) [0|4095] ""  Tester
 SG_ DCU_BSWVersion_Debug : 112|32@0+ (1,0) [0|4294967295] ""  Tester

BO_ 2683306010 DCU_DEBUG_2: 32 NIDU
 SG_ DCU_IgbtNtcTempMax : 7|8@0+ (1,-40) [-40|215] "degC"  Tester
 SG_ DCU_CtlBoardTemp_Debug : 15|8@0+ (1,-40) [-40|215] "degC"  Tester
 SG_ DCU_CapTemp_Debug : 23|8@0+ (1,-40) [-40|215] "degC"  Tester
 SG_ DCU_Debug_16Bit_2 : 31|16@0+ (1,0) [0|65535] ""  Tester
 SG_ DCU_Debug_16Bit_3 : 47|16@0+ (1,0) [0|65535] ""  Tester
 SG_ DCU_Debug_1Bit_3 : 66|1@0+ (1,0) [0|1] ""  Tester
 SG_ DCU_Debug_1Bit_2 : 67|1@0+ (1,0) [0|1] "-"  Tester
 SG_ DCU_PWMFreq_Debug : 63|12@0+ (10,0) [0|40950] "Hz"  Tester

BO_ 2683305995 DCU_DEBUG_3: 64 NIDU
 SG_ DCU_FusaFaultInfo8_Debug : 461|32@0+ (1,0) [0|4294967295] ""  Tester
 SG_ DCU_FusaFaultInfo7_Debug : 429|32@0+ (1,0) [0|4294967295] ""  Tester
 SG_ DCU_TempCoolant_1 : 421|8@0+ (1,-40) [-40|215] "degC"  Tester
 SG_ DCU_FusaTorqAct_Debug : 402|13@0+ (0.2,-819) [-819|819] ""  Tester
 SG_ DCU_FusaRotSpdAct_Debug : 386|16@0+ (1,-32767) [-32767|32766] ""  Tester
 SG_ DCU_FusaErrCode_Debug : 376|6@0+ (1,0) [0|63] ""  Tester
 SG_ DCU_FusastPWMEna_Debug : 377|1@0+ (1,0) [0|1] ""  Tester
 SG_ DCU_FusaQDisChargeReq_Debug : 378|1@0+ (1,0) [0|0] ""  Tester
 SG_ DCU_FusaModeSt_Debug : 382|4@0+ (1,0) [0|15] ""  Tester
 SG_ DCU_FusastSafePathReq_Debug : 369|3@0+ (1,0) [0|7] ""  Tester
 SG_ DCU_DataFaultHandle : 373|4@0+ (1,0) [0|15] ""  Tester
 SG_ DCU_stTorqLmtTsc : 240|22@0+ (1,0) [0|4194303] "-"  Tester
 SG_ DCU_TrqAntiJerk : 7|8@0+ (1,-127) [-127|128] "Nm"  Tester
 SG_ DCU_TrefFinal_Debug : 266|11@0+ (1,-1000) [-1000|1047] "Nm"  Tester
 SG_ DCU_Iq_Debug : 287|15@0+ (0.1,-1500) [-1500|1776.7] "A"  Tester
 SG_ DCU_Id_Debug : 288|15@0+ (0.1,-1500) [-1500|1776.7] "A"  Tester
 SG_ DCU_Debug_1Bit_4 : 239|1@0+ (1,0) [0|1] ""  Tester
 SG_ DCU_Debug_8Bit_4 : 15|8@0+ (1,0) [0|255] "-"  Tester
 SG_ DCU_Debug_16Bit_4 : 23|16@0+ (1,0) [0|65535] "-"  Tester
 SG_ DCU_Fault6_Debug : 39|32@0+ (1,0) [0|65535] ""  Tester
 SG_ DCU_Fault5_Debug : 71|32@0+ (1,0) [0|65535] "-"  Tester
 SG_ DCU_Fault4_Debug : 103|32@0+ (1,0) [0|65535] "-"  Tester
 SG_ DCU_Fault3_Debug : 135|32@0+ (1,0) [0|1048575] "-"  Tester
 SG_ DCU_Fault2_Debug : 167|32@0+ (1,0) [0|1048575] "-"  Tester
 SG_ DCU_Fault1_Debug : 199|32@0+ (1,0) [0|1048575] "-"  Tester
 SG_ DCU_TjMax : 231|8@0+ (1,-40) [-40|215] "degC"  Tester
 SG_ DCU_VoltUtilRatio : 238|7@0+ (0.01,0) [0|1.27] ""  Tester
 SG_ DCU_TorqueRatio : 247|7@0+ (0.01,0) [0|1.27] ""  Tester
 SG_ DCU_iCurqRef_Debug : 305|15@0+ (0.1,-1500) [-1500|1776.7] "A"  Tester
 SG_ DCU_iCurdRef_Debug : 322|15@0+ (0.1,-1500) [-1500|1776.7] "A"  Tester
 SG_ DCU_uVoltqRef : 339|15@0+ (0.1,-1500) [-1500|1776.7] "V"  Tester
 SG_ DCU_uVoltdRef : 356|15@0+ (0.1,-1500) [-1500|1776.7] "V"  Tester

BO_ 2683305992 DCU_DEBUG_4: 32 NIDU
 SG_ DCU_DMC_BCSDbgSig1 : 7|16@0+ (1,-30000) [-30000|30000] ""  Tester
 SG_ DCU_DMC_BCSDbgSig2 : 23|16@0+ (1,-30000) [-30000|30000] ""  Tester
 SG_ DCU_DMC_BCSDbgSig5 : 39|16@0+ (1,-32767) [-32767|32766] ""  Tester
 SG_ DCU_DMC_BCSDbgSig6 : 55|16@0+ (1,-32767) [-32767|32766] ""  Tester
 SG_ DCU_DMC_BCSDbgSig10 : 71|16@0+ (1,-30000) [-30000|30000] ""  Tester
 SG_ DCU_DMC_BCSDbgSig11 : 87|16@0+ (1,-30000) [-30000|30000] ""  Tester
 SG_ DCU_DMC_BCSDbgSig4 : 100|3@0+ (1,0) [0|7] ""  Tester
 SG_ DCU_DMC_BCSDbgSig3 : 103|3@0+ (1,0) [0|7] ""  Tester
 SG_ DCU_DMC_BCSDbgSig8 : 97|10@0+ (1,0) [0|1023] ""  Tester
 SG_ DCU_DMC_BCSDbgSig12 : 119|6@0+ (1,0) [0|63] ""  Tester
 SG_ DCU_DMC_BCSDbgSig9 : 113|10@0+ (1,-1023) [-1023|0] ""  Tester
 SG_ DCU_DMC_BCSDbgSig7 : 143|11@0+ (1,-1023) [-1023|1024] ""  Tester

BO_ 2683305998 DCU_DEBUG_5: 64 NIDU
 SG_ DCU_OSC_Signal1 : 7|8@0+ (1,0) [0|255] ""  Tester
 SG_ DCU_OSC_Signal2 : 15|8@0+ (1,0) [0|255] ""  Tester
 SG_ DCU_OSC_Signal3 : 23|8@0+ (1,0) [0|255] ""  Tester
 SG_ DCU_OSC_Signal4 : 31|8@0+ (1,0) [0|255] ""  Tester
 SG_ DCU_OSC_Signal5 : 39|8@0+ (1,0) [0|255] ""  Tester
 SG_ DCU_OSC_Signal6 : 47|8@0+ (1,0) [0|255] ""  Tester
 SG_ DCU_OSC_Signal7 : 55|8@0+ (1,0) [0|255] ""  Tester
 SG_ DCU_OSC_Signal8 : 63|8@0+ (1,0) [0|255] ""  Tester
 SG_ DCU_OSC_Signal9 : 71|8@0+ (1,0) [0|255] ""  Tester
 SG_ DCU_OSC_Signal10 : 79|8@0+ (1,0) [0|255] ""  Tester
 SG_ DCU_OSC_Signal11 : 87|8@0+ (1,0) [0|255] ""  Tester
 SG_ DCU_OSC_Signal12 : 95|8@0+ (1,0) [0|255] ""  Tester
 SG_ DCU_OSC_Signal13 : 103|8@0+ (1,0) [0|255] ""  Tester
 SG_ DCU_OSC_Signal14 : 111|8@0+ (1,0) [0|255] ""  Tester
 SG_ DCU_OSC_Signal15 : 119|8@0+ (1,0) [0|255] ""  Tester
 SG_ DCU_OSC_Signal16 : 127|8@0+ (1,0) [0|255] ""  Tester
 SG_ DCU_OSC_Signal17 : 135|8@0+ (1,0) [0|255] ""  Tester
 SG_ DCU_OSC_Signal18 : 143|8@0+ (1,0) [0|255] ""  Tester
 SG_ DCU_OSC_Signal19 : 151|8@0+ (1,0) [0|255] ""  Tester
 SG_ DCU_OSC_Signal20 : 159|8@0+ (1,0) [0|255] ""  Tester
 SG_ DCU_OSC_Signal21 : 167|8@0+ (1,0) [0|255] ""  Tester
 SG_ DCU_OSC_Signal22 : 175|8@0+ (1,0) [0|255] ""  Tester
 SG_ DCU_OSC_Signal23 : 183|8@0+ (1,0) [0|255] ""  Tester
 SG_ DCU_OSC_Signal24 : 191|8@0+ (1,0) [0|255] ""  Tester
 SG_ DCU_OSC_Signal25 : 199|8@0+ (1,0) [0|255] ""  Tester
 SG_ DCU_OSC_Signal26 : 207|8@0+ (1,0) [0|255] ""  Tester
 SG_ DCU_OSC_Signal27 : 215|8@0+ (1,0) [0|255] ""  Tester
 SG_ DCU_OSC_Signal28 : 223|8@0+ (1,0) [0|255] ""  Tester
 SG_ DCU_OSC_Signal29 : 231|8@0+ (1,0) [0|255] ""  Tester
 SG_ DCU_OSC_Signal30 : 239|8@0+ (1,0) [0|255] ""  Tester
 SG_ DCU_OSC_Signal31 : 247|8@0+ (1,0) [0|255] ""  Tester
 SG_ DCU_OSC_Signal32 : 255|8@0+ (1,0) [0|255] ""  Tester
 SG_ DCU_OSC_Signal33 : 263|8@0+ (1,0) [0|255] ""  Tester
 SG_ DCU_OSC_Signal34 : 271|8@0+ (1,0) [0|255] ""  Tester
 SG_ DCU_OSC_Signal35 : 279|8@0+ (1,0) [0|255] ""  Tester
 SG_ DCU_OSC_Signal36 : 287|8@0+ (1,0) [0|255] ""  Tester
 SG_ DCU_OSC_Signal37 : 295|8@0+ (1,0) [0|255] ""  Tester
 SG_ DCU_OSC_Signal38 : 303|8@0+ (1,0) [0|255] ""  Tester
 SG_ DCU_OSC_Signal39 : 311|8@0+ (1,0) [0|255] ""  Tester
 SG_ DCU_OSC_Signal40 : 319|8@0+ (1,0) [0|255] ""  Tester
 SG_ DCU_OSC_Signal41 : 327|8@0+ (1,0) [0|255] ""  Tester
 SG_ DCU_OSC_Signal42 : 335|8@0+ (1,0) [0|255] ""  Tester
 SG_ DCU_OSC_Signal43 : 343|8@0+ (1,0) [0|255] ""  Tester
 SG_ DCU_OSC_Signal44 : 351|8@0+ (1,0) [0|255] ""  Tester
 SG_ DCU_OSC_Signal45 : 359|8@0+ (1,0) [0|255] ""  Tester
 SG_ DCU_OSC_Signal46 : 367|8@0+ (1,0) [0|255] ""  Tester
 SG_ DCU_OSC_Signal47 : 375|8@0+ (1,0) [0|255] ""  Tester
 SG_ DCU_OSC_Signal48 : 383|8@0+ (1,0) [0|255] ""  Tester
 SG_ DCU_OSC_Signal49 : 391|8@0+ (1,0) [0|255] ""  Tester
 SG_ DCU_OSC_Signal50 : 399|8@0+ (1,0) [0|255] ""  Tester
 SG_ DCU_OSC_Signal51 : 407|8@0+ (1,0) [0|255] ""  Tester
 SG_ DCU_OSC_Signal52 : 415|8@0+ (1,0) [0|255] ""  Tester
 SG_ DCU_OSC_Signal53 : 423|8@0+ (1,0) [0|255] ""  Tester
 SG_ DCU_OSC_Signal54 : 431|8@0+ (1,0) [0|255] ""  Tester
 SG_ DCU_OSC_Signal55 : 439|8@0+ (1,0) [0|255] ""  Tester
 SG_ DCU_OSC_Signal56 : 447|8@0+ (1,0) [0|255] ""  Tester
 SG_ DCU_OSC_Signal57 : 455|8@0+ (1,0) [0|255] ""  Tester
 SG_ DCU_OSC_Signal58 : 463|8@0+ (1,0) [0|255] ""  Tester
 SG_ DCU_OSC_Signal59 : 471|8@0+ (1,0) [0|255] ""  Tester
 SG_ DCU_OSC_Signal60 : 479|8@0+ (1,0) [0|255] ""  Tester
 SG_ DCU_OSC_Signal61 : 487|8@0+ (1,0) [0|255] ""  Tester
 SG_ DCU_OSC_Signal62 : 495|8@0+ (1,0) [0|255] ""  Tester
 SG_ DCU_OSC_Signal63 : 503|8@0+ (1,0) [0|255] ""  Tester
 SG_ DCU_OSC_Signal64 : 511|8@0+ (1,0) [0|255] ""  Tester

BO_ 2683305999 DCU_DEBUG_6: 32 NIDU
 SG_ DCU_Debug_Id : 7|15@0+ (0.1,-1500) [-1500|1776.7] "A"  Tester
 SG_ DCU_Debug_Iq : 8|15@0+ (0.1,-1500) [-1500|1776.7] "A"  Tester
 SG_ DCU_Debug_TorqEstByTable : 25|15@0+ (0.1,-1500) [-1500|1776.7] "Nm"  Tester
 SG_ DCU_Debug_TorqEstByPower : 42|15@0+ (0.1,-1500) [-1500|1776.7] "Nm"  Tester
 SG_ DCU_Debug_IdcEst : 59|15@0+ (0.1,-1500) [-1500|1776.7] "A"  Tester

BO_ 1178 DCU_DigEvent: 64 NIDU
 SG_ DCU_DTCCode9 : 295|32@0+ (1,0) [0|4294967295] "" Vector__XXX
 SG_ DCU_DTCCode8 : 263|32@0+ (1,0) [0|4294967295] "" Vector__XXX
 SG_ DCU_DTCCode7 : 231|32@0+ (1,0) [0|4294967295] "" Vector__XXX
 SG_ DCU_DTCCode6 : 199|32@0+ (1,0) [0|4294967295] "" Vector__XXX
 SG_ DCU_DTCCode5 : 167|32@0+ (1,0) [0|4294967295] "" Vector__XXX
 SG_ DCU_DTCCode4 : 135|32@0+ (1,0) [0|4294967295] "" Vector__XXX
 SG_ DCU_DTCCode3 : 103|32@0+ (1,0) [0|4294967295] "" Vector__XXX
 SG_ DCU_DTCCode2 : 71|32@0+ (1,0) [0|4294967295] "" Vector__XXX
 SG_ DCU_DTCCode15 : 487|32@0+ (1,0) [0|4294967295] "" Vector__XXX
 SG_ DCU_DTCCode14 : 455|32@0+ (1,0) [0|4294967295] "" Vector__XXX
 SG_ DCU_DTCCode13 : 423|32@0+ (1,0) [0|4294967295] "" Vector__XXX
 SG_ DCU_DTCCode12 : 391|32@0+ (1,0) [0|4294967295] "" Vector__XXX
 SG_ DCU_DTCCode11 : 359|32@0+ (1,0) [0|4294967295] "" Vector__XXX
 SG_ DCU_DTCCode10 : 327|32@0+ (1,0) [0|4294967295] "" Vector__XXX
 SG_ DCU_DTCCode1 : 39|32@0+ (1,0) [0|4294967295] "" Vector__XXX
 SG_ DCU_DTCCode0 : 7|32@0+ (1,0) [0|4294967295] ""  CCU

BO_ 384 EOP_1: 64 EOP
 SG_ EOP_1_CRC : 7|16@0+ (1,0) [0|65535] ""  CCU,NIDU,DCU,CCURT1,VDC
 SG_ EOP_1_Counter : 23|8@0+ (1,0) [0|255] ""  CCU,NIDU,DCU,CCURT1,VDC
 SG_ EOP_SpdAct : 29|12@0+ (1,0) [0|4000] "rpm"  CCU,NIDU,DCU,CCURT1
 SG_ EOP_IphAct : 33|10@0+ (0.1,0) [0|50] "A"  CCU,NIDU,DCU,CCURT1
 SG_ EOP_IdcAct : 55|8@0+ (0.1,0) [0|25] "A"  CCU,NIDU,DCU,CCURT1
 SG_ EOP_UdcAct : 63|8@0+ (0.1,0) [0|25] "V"  CCU,NIDU,DCU,CCURT1
 SG_ EOP_ErrLevel : 68|3@0+ (1,0) [0|7] ""  CCU,NIDU,DCU,CCURT1
 SG_ EOP_Status : 71|3@0+ (1,0) [0|4] ""  CCU,NIDU,DCU,CCURT1
 SG_ EOP_duty : 79|7@0+ (1,0) [0|100] "%"  CCU,NIDU,DCU,CCURT1

BO_ 2683306160 Err_OSCManage: 8 Tester
 SG_ Err_Clear : 6|1@0+ (1,0) [0|1] ""  NIDU,DCU
 SG_ Err_Read : 7|1@0+ (1,0) [0|1] ""  NIDU,DCU

BO_ 599 EVCC_1: 64 EVCC
 SG_ EVCC_1_CRC : 7|16@0+ (1,0) [0|65535] ""  CCU,NIDU,IPS
 SG_ EVCC_1_Counter : 23|8@0+ (1,0) [0|255] ""  CCU,NIDU,IPS
 SG_ EVCC_OBC_CPVoltage : 87|8@0+ (0.1,0) [0|25.5] "V"  CCU,NIDU,IPS
 SG_ EVCC_OBC_CPDutycycle : 95|10@0+ (0.1,0) [0|102.3] ""  CCU,NIDU,IPS
 SG_ EVCC_S2_Drive : 113|1@0+ (1,0) [0|1] ""  CCU,NIDU,IPS
 SG_ EVCC_OBC_CpFreqSt : 114|1@0+ (1,0) [0|1] ""  CCU,NIDU,IPS
 SG_ EVCC_CCOUT_Drive : 115|1@0+ (1,0) [0|1] ""  CCU,NIDU,IPS
 SG_ EVCC_lostECAN : 116|1@0+ (1,0) [0|1] ""  CCU,NIDU,IPS

BO_ 1533 EVCC_NM: 8 EVCC
 SG_ EVCC_NMNodeAddress : 7|8@0+ (1,0) [0|255] ""  CCU,NIDU,ITS,BMC,DCDC,DCDC2,DCU,IPS,CCURT1
 SG_ EVCC_NMCBV : 15|8@0+ (1,0) [0|0] ""  CCU,NIDU,ITS,BMC,DCDC,DCDC2,DCU,IPS,CCURT1
 SG_ EVCC_NMWakeupOrigin : 23|8@0+ (1,0) [0|255] ""  CCU,NIDU,ITS,BMC,DCDC,DCDC2,DCU,IPS,CCURT1
 SG_ EVCC_PNCInformation0 : 31|8@0+ (1,0) [0|255] ""  CCU,NIDU,ITS,BMC,DCDC,DCDC2,DCU,IPS,CCURT1
 SG_ EVCC_PNCInformation1 : 39|32@0+ (1,0) [0|0] ""  CCU,NIDU,ITS,BMC,DCDC,DCDC2,DCU,IPS,CCURT1

BO_ 2015 Fun_Diag_Rx: 64 EVCC
 SG_ Fun_Diag_Request : 7|512@0+ (1,0) [0|0] ""  NIDU,ITS,EOP,BMC,EVCC,DCDC,DCDC2,Tester,DCU,ZCUF,ZCUL,ZCUR,ZCUT,IPS,RBM,IBCS,IDC,CCU3,CCU4,AVAS,FLLCM,FRLCM,RLLCMA,RRLCMA,RLLCMB,RRLCMB,PADS,MFS,PCU,SRS,EPS,AMP,WHUD,IMR,FIMR,ADC,VIU,RADARRR,RADARRL,RADARFR,RADARFL,RPC,IFC,PAS,RADARFRT,RADARR,SBM,WCM,ETC,TBOX,DSM,FLPDM,FRPDM,RLPDM,RRPDM,TFOAR,TROAR,VDC,RFR

BO_ 704 IPS_1: 64 NIDU
 SG_ IPS_1_CRC : 7|16@0+ (1,0) [0|65535] ""  CCU,BMC,EVCC,CCURT1,VDC
 SG_ IPS_1_Counter : 23|8@0+ (1,0) [0|255] ""  CCU,BMC,EVCC,CCURT1,VDC
 SG_ IPS_DCDCDiagErrCode : 31|8@0+ (1,0) [0|255] ""  CCU,CCURT1,VDC
 SG_ IPS_KL15State : 36|1@0+ (1,0) [0|1] ""  CCU,CCURT1
 SG_ IPS_DCDCModeSt : 39|3@0+ (1,0) [0|7] ""  CCU,TBOX,CCURT1,VDC
 SG_ IPS_DCDCVoltLvAct : 35|10@0+ (0.1,0) [0|102.3] "V"  CCU,CCURT1,VDC
 SG_ IPS_DCDCCurrHvAct : 41|9@0+ (0.1,0) [0|51.1] "A"  CCU,DCU,CCURT2,CCURT1,VDC
 SG_ IPS_DCDCCurrLvAct : 63|9@0+ (1,0) [0|511] "A"  CCU,CCURT2,CCURT1,VDC
 SG_ IPS_DCDCVoltHvAct : 70|10@0+ (1,0) [0|1023] "V"  CCU,DCU,CCURT1,VDC
 SG_ IPS_OBCDiagErrCode : 151|8@0+ (1,0) [0|255] ""  CCU,CCURT1,VDC
 SG_ IPS_OBCCC_St : 159|3@0+ (1,0) [0|7] ""  CCU,BMC,EVCC,DCU,CCURT2,CCURT1,VDC
 SG_ IPS_OBCCpFreqSt : 160|1@0+ (1,0) [0|1] ""  CCU,CCURT1,VDC
 SG_ IPS_DchgOverload : 161|1@0+ (1,0) [0|1] ""  CCU,CCURT1,VDC
 SG_ IPS_OBCDschDisable : 162|1@0+ (1,0) [0|1] ""  CCU,CCURT1,VDC
 SG_ IPS_OBCCC_Res : 156|10@0+ (10,0) [0|10230] "Ohm"  CCU,EVCC,CCURT1,VDC
 SG_ IPS_OBCModeSt : 175|4@0+ (1,0) [0|15] ""  CCU,CCURT2,CCURT1,VDC
 SG_ IPS_OBCHvDcCurrAct : 171|11@0+ (0.1,-102.4) [-102.4|102.3] "A"  CCU,BMC,CCURT1,VDC
 SG_ IPS_OBCCPSt : 195|1@0+ (1,0) [0|1] ""  CCU,CCURT1,VDC
 SG_ IPS_OBCCC_Cap : 198|3@0+ (1,0) [0|7] ""  CCU,BMC,CCURT2,CCURT1,VDC
 SG_ IPS_OBCHvDcVoltAct : 176|10@0+ (1,0) [0|1023] "V"  CCU,BMC,CCURT1,VDC
 SG_ IPS_OBCCpS2St : 200|1@0+ (1,0) [0|1] ""  CCU,CCURT1,VDC
 SG_ IPS_OBCCp_DutyCycle : 194|10@0+ (0.1,0) [0|100] ""  CCU,CCURT1,VDC
 SG_ IPS_OBCCPVolt : 215|8@0+ (0.1,0) [0|12.7] "V"  CCU,CCURT1,VDC
 SG_ IPS_OBCUacActL1 : 223|9@0+ (1,0) [0|511] "V"  CCU,CCURT1,VDC
 SG_ IPS_OBCUacActL3 : 238|9@0+ (1,0) [0|511] "V"  CCU,CCURT1,VDC
 SG_ IPS_OBCCurrActL1 : 254|9@0+ (0.1,0) [0|51.1] "A"  CCU,CCURT1,VDC
 SG_ IPS_OBCCurrActL2 : 261|9@0+ (0.1,0) [0|51.1] "A"  CCU,CCURT1,VDC
 SG_ IPS_OBCCurrActL3 : 268|9@0+ (0.1,0) [0|51.1] "A"  CCU,CCURT1,VDC
 SG_ IPS_smo_ObcModeSt : 275|7@0+ (1,0) [0|127] ""  CCU,CCURT1
 SG_ IPS_OBCUacActL2 : 295|9@0+ (1,0) [0|511] "V"  CCU,CCURT1,VDC
 SG_ IPS_smd_DcdcModeSt : 309|6@0+ (1,0) [0|63] ""  CCU,CCURT1
 SG_ IPS_WakeOriginSignal2 : 423|16@0+ (1,0) [0|65535] ""  CCU,CCURT1
 SG_ IPS_WakeOriginSignal1 : 439|16@0+ (1,0) [0|65535] ""  CCU,CCURT1
 SG_ IPS_1_FreshnessValue : 455|16@0+ (1,0) [0|255] ""  Tester
 SG_ IPS_1_MAC_Check : 471|48@0+ (1,0) [0|255] ""  Tester

BO_ 872 IPS_2: 64 NIDU
 SG_ IPS_2_CRC : 7|16@0+ (1,0) [0|65535] ""  CCU,DCU,CCURT1,VDC
 SG_ IPS_2_Counter : 23|8@0+ (1,0) [0|255] ""  CCU,DCU,CCURT1,VDC
 SG_ IPS_SwVersion : 31|16@0+ (1,0) [0|65535] ""  CCU,CCURT1
 SG_ IPS_TEL_DCDCTempOvrErr : 40|1@0+ (1,0) [0|1] ""  CCU,TBOX
 SG_ IPS_TEL_DCDCFaultLampInd : 41|1@0+ (1,0) [0|1] ""  CCU,TBOX
 SG_ IPS_RemoteDiagCode : 43|2@0+ (1,0) [0|3] ""  CCU,CCURT2,TBOX,CCURT1,VDC
 SG_ IPS_HwSt : 47|4@0+ (1,0) [0|15] ""  CCU,CCURT1,VDC
 SG_ IPS_DCDCFlowReq : 52|4@0+ (1,0) [0|15] "L/min"  CCU,CCURT1,VDC
 SG_ IPS_DCDCFaultLampInd : 53|1@0+ (1,0) [0|1] ""  CCU,CCURT2,IDC,CCURT1,VDC
 SG_ IPS_TEL_DCDCModeSt : 55|2@0+ (1,0) [0|3] ""  CCU,TBOX
 SG_ IPS_TempAct : 63|8@0+ (1,-40) [-40|215] "degC"  CCU,DCU,CCURT1,VDC
 SG_ IPS_HVDCHVilSt : 71|2@0+ (1,0) [0|3] ""  CCU,CCURT1,VDC
 SG_ IPS_DCDCKL30Volt : 68|9@0+ (0.1,0) [0|51.1] ""  CCU,CCURT1
 SG_ IPS_DCDCState1 : 87|8@0+ (1,0) [0|255] ""  CCU,CCURT1
 SG_ IPS_DCDCState2 : 95|8@0+ (1,0) [0|255] ""  CCU,CCURT1
 SG_ IPS_DCDCState3 : 103|8@0+ (1,0) [0|255] ""  CCU,CCURT1
 SG_ IPS_DCDCState4 : 111|8@0+ (1,0) [0|255] ""  CCU,CCURT1
 SG_ IPS_DCDCState5 : 119|8@0+ (1,0) [0|255] ""  CCU,CCURT1
 SG_ IPS_DCDCState6 : 127|8@0+ (1,0) [0|255] ""  CCU
 SG_ IPS_OBCFaultLampInd : 137|1@0+ (1,0) [0|1] ""  CCU,CCURT2,IDC,CCURT1,VDC
 SG_ IPS_OBCFlowReq : 141|4@0+ (1,0) [0|15] "L/min"  CCU,CCURT1,VDC
 SG_ IPS_OBCChgPwrMax : 135|10@0+ (0.05,0) [0|51.15] "kW"  CCU,BMC,CCURT2,CCURT1,VDC
 SG_ IPS_ChgCurRespAvail : 144|1@0+ (1,0) [0|1] ""  CCU
 SG_ IPS_ChgCurResp : 149|5@0+ (1,0) [0|31] ""  CCU,BMC
 SG_ IPS_ACHvilSt : 151|2@0+ (1,0) [0|3] ""  CCU,CCURT1,VDC
 SG_ IPS_OBCState1 : 159|8@0+ (1,0) [0|255] ""  CCU,CCURT1
 SG_ IPS_OBCState2 : 167|8@0+ (1,0) [0|255] ""  CCU,CCURT1
 SG_ IPS_OBCState3 : 175|8@0+ (1,0) [0|255] ""  CCU,CCURT1
 SG_ IPS_OBCState4 : 183|8@0+ (1,0) [0|255] ""  CCU,CCURT1
 SG_ IPS_OBCState5 : 191|8@0+ (1,0) [0|255] ""  CCU,CCURT1
 SG_ IPS_OBCFaultLampIndOperationFlag : 197|1@0+ (1,0) [0|1] ""  CCU,IDC,CCURT1
 SG_ IPS_DCDCFaultLampIndFlag : 198|1@0+ (1,0) [0|1] ""  CCU,IDC,CCURT1
 SG_ IPS_DCDCFaultLampIndOperationFla : 199|1@0+ (1,0) [0|1] ""  CCU,IDC,CCURT1
 SG_ IPS_OBCState7 : 207|8@0+ (1,0) [0|255] ""  CCU
 SG_ IPS_OBCState8 : 215|8@0+ (1,0) [0|255] ""  CCU
 SG_ IPS_OBCState9 : 223|8@0+ (1,0) [0|255] ""  CCU
 SG_ IPS_OBCState10 : 231|8@0+ (1,0) [0|255] ""  CCU
 SG_ IPS_OBCState11 : 239|8@0+ (1,0) [0|255] ""  CCU
 SG_ IPS_DCDCState7 : 247|8@0+ (1,0) [0|255] ""  CCU
 SG_ IPS_DCDCState8 : 255|8@0+ (1,0) [0|255] ""  CCU
 SG_ IPS_DCDCState9 : 263|8@0+ (1,0) [0|255] ""  CCU
 SG_ IPS_DCDCState10 : 271|8@0+ (1,0) [0|255] ""  CCU
 SG_ IPS_OBCState6 : 279|8@0+ (1,0) [0|255] ""  CCU
 SG_ IPS_OBCAcIso_Res : 285|6@0+ (20,0) [0|1260] "K¦¸"  CCU,CCURT1
 SG_ IPS_2_FreshnessValue : 455|16@0+ (1,0) [0|255] ""  Tester
 SG_ IPS_2_MAC_Check : 471|48@0+ (1,0) [0|255] ""  Tester

BO_ 2683306000 IPS_Debug_1: 64 Tester
 SG_ IPS_Password : 7|8@0+ (1,0) [0|255] ""  NIDU,IPS
 SG_ IPS_TEL_DCDCFaultLampInd2 : 8|1@0+ (1,0) [0|1] ""  NIDU,IPS
 SG_ IPS_TEL_DCDCTempOvrErr2 : 9|1@0+ (1,0) [0|1] ""  NIDU,IPS
 SG_ IPS_Disable_CC : 12|3@0+ (1,0) [0|7] ""  NIDU,IPS
 SG_ IPS_Disable_CP : 15|3@0+ (1,0) [0|7] ""  NIDU,IPS
 SG_ IPS_Disable_RCChecksum : 16|1@0+ (1,0) [0|1] ""  NIDU,IPS
 SG_ IPS_DCDCSet : 17|1@0+ (1,0) [0|1] ""  NIDU,IPS
 SG_ IPS_OBCSet : 18|1@0+ (1,0) [0|1] ""  NIDU,IPS
 SG_ IPS_OBCHvVoltLimSet : 19|1@0+ (1,0) [0|1] ""  NIDU,IPS
 SG_ IPS_Disable_DCDCSelfChck : 20|1@0+ (1,0) [0|1] ""  NIDU,IPS
 SG_ IPS_DCDCLvVoltSet : 31|10@0+ (0.1,0) [0|102.3] "V"  NIDU,IPS
 SG_ IPS_OBCChgVoltReqManCal : 37|10@0+ (1,0) [0|1023] "V"  NIDU,IPS
 SG_ IPS_OBCChgCurrReqManCal : 43|10@0+ (0.1,0) [0|102.3] "A"  NIDU,IPS
 SG_ IPS_OBCDchgDcCurrLim : 49|10@0+ (0.1,0) [0|102.3] "A"  NIDU,IPS

BO_ 2683306012 IPS_Debug_2: 64 NIDU
 SG_ IPS_DiagDtcSetSt : 8|1@0+ (1,0) [0|1] ""  CCU,ZCUT
 SG_ IPS_DiagClrErr : 9|1@0+ (1,0) [0|1] ""  CCU,ZCUT
 SG_ IPS_pwrObcChgCap : 7|14@0+ (0.01,0) [0|163.83] "KW"  CCU,ZCUT
 SG_ IPS_PfcPwrModeSt : 27|4@0+ (1,0) [0|15] ""  CCU,ZCUT
 SG_ IPS_tPfcTemp : 23|12@0+ (0.1,-50) [-50|359.5] "degC"  CCU,ZCUT
 SG_ IPS_LLcPwrModeSt : 43|4@0+ (1,0) [0|15] ""  CCU,ZCUT
 SG_ IPS_fCpFrq : 39|12@0+ (1,0) [0|4095] "Hz"  CCU,ZCUT
 SG_ IPS_DcdcPwrModeSt : 61|4@0+ (1,0) [0|15] ""  CCU,ZCUT
 SG_ IPS_reAcIsoRes : 55|10@0+ (1,0) [0|1023] "KOhm"  CCU,ZCUT
 SG_ IPS_smd_uDcdcLvVoltSet : 71|10@0+ (0.1,0) [0|102.3] "V"  CCU,ZCUT
 SG_ IPS_spd_NmReq : 91|4@0+ (1,0) [0|15] ""  CCU,ZCUT
 SG_ IPS_fmd_DcdcFaultStopEn : 92|1@0+ (1,0) [0|1] ""  CCU,ZCUT
 SG_ IPS_fmo_ObcFaultStopEn : 93|1@0+ (1,0) [0|1] ""  CCU,ZCUT
 SG_ IPS_smo_dDchgCpDucyc : 87|10@0+ (0.1,0) [0|100] "%"  CCU,ZCUT
 SG_ IPS_smo_IsoTestEn : 101|3@0+ (1,0) [0|7] ""  CCU,ZCUT
 SG_ IPS_fmd_FsDcdcPwrOffEn : 102|1@0+ (1,0) [0|1] ""  CCU,ZCUT
 SG_ IPS_smd_FsDcdcOvpSelfChckSt : 103|1@0+ (1,0) [0|1] ""  CCU,ZCUT
 SG_ IPS_smo_iObcDcCurrLim : 117|4@0+ (1,0) [0|15] ""  CCU,ZCUT
 SG_ IPS_smo_ObcModeSet : 111|10@0+ (0.1,0) [0|102.3] "A"  CCU,ZCUT
 SG_ IPS_smo_uObcDcVoltSet : 113|10@0+ (1,0) [0|1023] "V"  CCU,ZCUT
 SG_ IPS_RelaySts : 139|4@0+ (1,0) [0|15] ""  CCU,ZCUT
 SG_ IPS_DcdcRadTemp : 135|12@0+ (0.1,-50) [-50|359.5] "degC"  CCU,ZCUT
 SG_ IPS_PfcVbulk : 151|14@0+ (0.1,0) [0|1638.3] "V"  CCU,ZCUT
 SG_ IPS_iObcHvCurr : 153|10@0+ (0.1,0) [0|102.3] "A"  CCU,ZCUT
 SG_ IPS_fmo_ObcFaultReset : 171|1@0+ (1,0) [0|1] ""  CCU,ZCUT
 SG_ IPS_fmd_DcdcFaultReset : 172|1@0+ (1,0) [0|1] ""  CCU,ZCUT
 SG_ IPS_smo_Cp9vTiOut : 173|1@0+ (1,0) [0|1] ""  CCU,ZCUT
 SG_ IPS_smo_Cp12vTiOut : 174|1@0+ (1,0) [0|1] ""  CCU,ZCUT
 SG_ IPS_smd_iDcdcLvCurrLim : 170|9@0+ (1,0) [0|511] "A"  CCU,ZCUT
 SG_ IPS_spo_iObcCcCpAcCurrLim : 177|10@0+ (0.1,0) [0|102.3] "A"  CCU,ZCUT
 SG_ IPS_DcdcSRSts : 215|4@0+ (1,0) [0|15] ""  CCU,ZCUT
 SG_ IPS_LlcWorkFreq : 211|12@0+ (0.1,0) [0|409.5] ""  CCU,ZCUT
 SG_ IPS_DcdcBuckDuty : 231|10@0+ (0.1,0) [0|100] "%"  CCU,ZCUT
 SG_ IPS_uFsDcdcLvVolt : 237|10@0+ (0.1,0) [0|102.3] "V"  CCU,ZCUT
 SG_ IPS_ocm_AswVersion : 255|8@0+ (1,0) [0|255] ""  CCU,Tester
 SG_ IPS_PfcVersion : 263|8@0+ (1,0) [0|255] ""  CCU,Tester
 SG_ IPS_LlcVersion : 271|8@0+ (1,0) [0|255] ""  CCU,Tester
 SG_ IPS_DcdcVersion : 279|8@0+ (1,0) [0|255] ""  CCU,Tester

BO_ 880 ITS_1: 64 ITS
 SG_ ITS_1_CRC : 7|16@0+ (1,0) [0|65535] ""  CCU,NIDU,BMC,DCU,IPS,CCURT1,VDC
 SG_ ITS_1_Counter : 23|8@0+ (1,0) [0|255] ""  CCU,NIDU,BMC,DCU,IPS,CCURT1,VDC
 SG_ ITS_MotorPumpSt : 31|2@0+ (1,0) [0|3] ""  CCU,NIDU,DCU,CCURT2,IDC,CCURT1,VDC
 SG_ ITS_EMVSt : 35|2@0+ (1,0) [0|3] ""  CCU,NIDU,DCU,CCURT2,IDC,CCURT1,VDC
 SG_ ITS_ValvePositionAct : 39|4@0+ (1,0) [0|15] ""  CCU,NIDU,DCU,CCURT2,CCURT1,VDC
 SG_ ITS_BatteryPumpSt : 46|2@0+ (1,0) [0|3] ""  CCU,NIDU,DCU,CCURT2,IDC,CCURT1,VDC
 SG_ ITS_MotorInletTempErr : 102|1@0+ (1,0) [0|1] ""  CCU,NIDU,DCU,CCURT2,IDC,CCURT1,VDC
 SG_ ITS_MotorInletTemp : 111|16@0+ (0.1,-50) [-50|150] "degC"  CCU,NIDU,DCU,CCURT2,CCURT1,VDC
 SG_ ITS_BatteryInletTemp : 127|16@0+ (0.1,-50) [-50|150] "degC"  CCU,NIDU,BMC,DCU,CCURT2,CCURT1,VDC
 SG_ ITS_ChillerInletTemp : 143|16@0+ (0.1,-50) [-50|150] "degC"  CCU,NIDU,BMC,DCU,CCURT2,CCURT1,VDC
 SG_ ITS_BattOutletTsnsrErrCode : 247|2@0+ (1,0) [0|3] ""  CCU,NIDU,DCU,CCURT2,IPS
 SG_ ITS_MotorPumpSpdAct : 262|7@0+ (1,0) [0|100] "%"  CCU,NIDU,DCU,CCURT1,VDC
 SG_ ITS_ChlrExvErrCode : 255|9@0+ (1,0) [0|511] ""  CCU,NIDU,DCU,CCURT2,IPS
 SG_ ITS_BatteryPumpSpdAct : 270|7@0+ (1,0) [0|100] "%"  CCU,NIDU,DCU,CCURT1,VDC

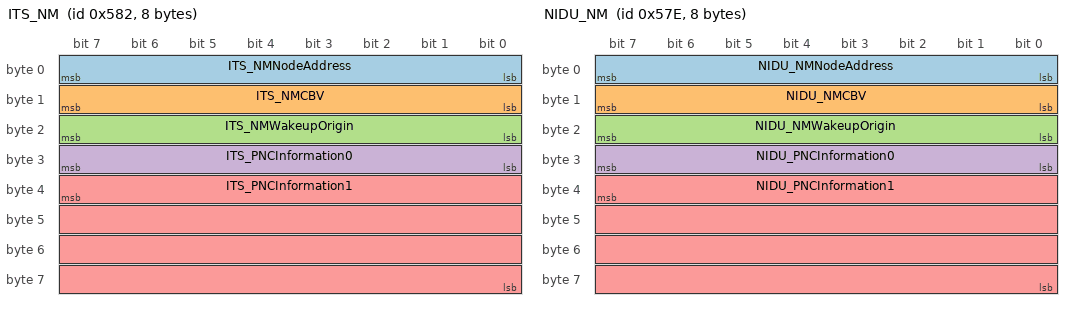
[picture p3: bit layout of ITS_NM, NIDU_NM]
BO_ 1410 ITS_NM: 8 ITS
 SG_ ITS_NMNodeAddress : 7|8@0+ (1,0) [0|255] ""  CCU,NIDU,BMC,EVCC,DCDC,DCDC2,DCU,IPS,PCU,CCURT1
 SG_ ITS_NMCBV : 15|8@0+ (1,0) [0|0] ""  CCU,NIDU,BMC,EVCC,DCDC,DCDC2,DCU,IPS,PCU,CCURT1
 SG_ ITS_NMWakeupOrigin : 23|8@0+ (1,0) [0|255] ""  CCU,NIDU,BMC,EVCC,DCU,IPS,PCU,CCURT1
 SG_ ITS_PNCInformation0 : 31|8@0+ (1,0) [0|255] ""  CCU,NIDU,BMC,EVCC,DCDC,DCDC2,DCU,IPS,PCU,CCURT1
 SG_ ITS_PNCInformation1 : 39|32@0+ (1,0) [0|0] ""  CCU,NIDU,BMC,EVCC,DCU,IPS,PCU,CCURT1

BO_ 1790 NIDU_Diag_Tx: 64 NIDU
 SG_ NIDU_Diag_Response : 7|512@0+ (1,0) [0|0] ""  Tester

BO_ 1406 NIDU_NM: 8 NIDU
 SG_ NIDU_NMNodeAddress : 7|8@0+ (1,0) [0|255] ""  CCU,ITS,BMC,EVCC,DCDC,DCDC2,PCU,CCURT1
 SG_ NIDU_NMCBV : 15|8@0+ (1,0) [0|0] ""  CCU,ITS,BMC,EVCC,DCDC,DCDC2,PCU,CCURT1
 SG_ NIDU_NMWakeupOrigin : 23|8@0+ (1,0) [0|255] ""  CCU,ITS,BMC,EVCC,DCDC,DCDC2,PCU,CCURT1
 SG_ NIDU_PNCInformation0 : 31|8@0+ (1,0) [0|255] ""  CCU,ITS,BMC,EVCC,DCDC,DCDC2,PCU,CCURT1
 SG_ NIDU_PNCInformation1 : 39|32@0+ (1,0) [0|0] ""  CCU,ITS,BMC,EVCC,DCDC,DCDC2,PCU,CCURT1

BO_ 1662 NIDU_Phys_Diag_Rx: 64 Tester
 SG_ NIDU_Diag_Request : 7|512@0+ (1,0) [0|0] ""  NIDU

BO_ 818 TMS_1: 64 CCU
 SG_ TMS_1_CRC : 7|16@0+ (1,0) [0|65535] ""  NIDU,ITS,DCU
 SG_ TMS_1_Counter : 23|8@0+ (1,0) [0|255] ""  NIDU,ITS,DCU
 SG_ TMS_MotorLoopEstimatedFlow : 119|8@0+ (0.1,0) [0|20] "L/min"  NIDU,DCU,IPS
 SG_ TMS_CtrlPwmDucycLT : 126|7@0+ (1,0) [0|100] "%"  NIDU,DCU,CCURT2
 SG_ TMS_MotorLoopEstimatedFlowVD : 128|1@0+ (1,0) [0|1] ""  NIDU,DCU,IPS
 SG_ TMS_CtrlPwmDucycMT : 135|7@0+ (1,0) [0|100] "%"  NIDU,DCU,CCURT2
 SG_ TMS_DiagMTPump : 140|3@0+ (1,0) [0|7] ""  NIDU,DCU,CCURT2
 SG_ TMS_DiagLTPump : 143|3@0+ (1,0) [0|7] ""  NIDU,DCU,CCURT2
 SG_ TMS_AHFOnReq : 387|2@0+ (1,0) [0|3] ""  NIDU,DCU,CCURT1
 SG_ TMS_AHFPwrReq : 381|10@0+ (10,0) [0|10200] "W"  NIDU,DCU,CCURT1
 SG_ TMS_AHFSt : 392|1@0+ (1,0) [0|1] ""  NIDU,DCU,CCURT1
 SG_ TMS_AHFHeatingReq : 399|7@0+ (1,0) [0|100] "%"  NIDU,DCU,CCURT1

BO_ 1152 TMS_3: 64 CCU
 SG_ HVAC_TargetWaterTempMaxFC : 103|8@0+ (0.5,-40) [-40|87.5] "ï¿½ï¿½"  NIDU,ITS,DCU
 SG_ HVAC_TargetWaterTempMinFC : 111|8@0+ (0.5,-40) [-40|87.5] "ï¿½ï¿½"  NIDU,ITS,DCU

BO_ 392 VCU_1: 64 CCU
 SG_ VCU_1_CRC : 7|16@0+ (1,0) [0|65535] ""  NIDU,BMC,DCDC,DCDC2,DCU,IPS
 SG_ VCU_1_Counter : 23|8@0+ (1,0) [0|255] ""  NIDU,BMC,DCDC,DCDC2,DCU,IPS
 SG_ VCU_DCU_TorqSet : 25|13@0+ (0.2,-819) [-819|819] "Nm"  NIDU,DCU
 SG_ VCU_DCU_MinTorqDampgCtl : 71|8@0+ (1,-255) [-255|0] "Nm"  NIDU,DCU
 SG_ VCU_DCU_IdcMax : 94|10@0+ (1,0) [0|1023] "A"  NIDU,DCU
 SG_ VCU_DCU_IdcMin : 100|10@0+ (1,-1023) [-1023|0] "A"  NIDU,DCU
 SG_ EMS_GasPedalActPstforMRRVD_E : 145|1@0+ (1,0) [0|1] ""  NIDU,DCU
 SG_ VCU_DCU_TorqMin : 139|10@0+ (1,-1023) [-1023|0] "Nm"  NIDU,DCU
 SG_ VCU_DCU_MaxTorqGradient : 144|14@0+ (32,0) [0|524256] "Nm/s"  NIDU,DCU
 SG_ VCU_DCU_TorqMax : 162|10@0+ (1,0) [0|1023] "Nm"  NIDU,DCU
 SG_ VCU_DCU_MaxTorqDampgCtl : 168|8@0+ (1,0) [0|253] "Nm"  NIDU,DCU
 SG_ VCU_DCU_CoolantTemp : 176|8@0+ (1,-40) [-40|215] "degC"  NIDU,DCU
 SG_ VCU_DCU_SpdLmt : 184|16@0+ (1,-32767) [-32767|32768] "rpm"  NIDU,DCU
 SG_ EMS_GasPedalActPstforMRR_E : 215|8@0+ (0.392,0) [0|99.96] "%"  NIDU,DCU
 SG_ VCU_DCU_SpdSet : 248|16@0+ (1,-32767) [-32767|32768] "rpm"  NIDU,DCU
 SG_ VCU_DCU_SurgeDamperStReq : 277|2@0+ (1,0) [0|3] ""  NIDU,DCU
 SG_ VCU_CrntGearLvl : 264|3@0+ (1,0) [0|7] ""  NIDU,DCU
 SG_ VCU_DCU_SurgeDamperFactor : 280|6@0+ (0.125,0) [0|7.875] ""  NIDU,DCU
 SG_ VCU_HvilSt : 308|2@0+ (1,0) [0|3] ""  NIDU,BMC,DCU
 SG_ VCU_DCU_ModeReq : 296|4@0+ (1,0) [0|15] ""  NIDU,BMC,DCU
 SG_ VCU_IPS_OBCModeReq : 314|3@0+ (1,0) [0|7] ""  NIDU,IPS
 SG_ VCU_BrkPedPstVD_E : 315|1@0+ (1,0) [0|1] ""  NIDU,DCU
 SG_ VCU_BMS_SepaHeatEn : 317|1@0+ (1,0) [0|1] ""  NIDU,BMC,IPS
 SG_ VCU_IPS_DCDCModeReq : 322|3@0+ (1,0) [0|7] ""  NIDU,DCDC,DCDC2,IPS
 SG_ VCU_IPS_OBCDsChDCCurrLim : 335|10@0+ (0.1,0) [0|102.3] "A"  NIDU,IPS
 SG_ VCU_IPS_DCDCLvCurrLim : 341|10@0+ (0.5,0) [0|511.5] "A"  NIDU,DCDC,DCDC2,IPS
 SG_ VCU_IPS_DCDCVoltLvSet : 347|10@0+ (0.1,0) [0|102.3] "V"  NIDU,DCDC,DCDC2,IPS
 SG_ VCU_IPS_OBCChgCurrReq : 353|10@0+ (0.1,0) [0|102.3] "A"  NIDU,IPS
 SG_ VCU_IPS_OBCChgVoltReq : 375|16@0+ (0.1,0) [0|6553.5] "V"  NIDU,IPS
 SG_ VCU_BrkPedPst_E : 391|8@0+ (0.392,0) [0|99.96] "%"  NIDU,DCU

BO_ 824 VCU_2: 64 CCU
 SG_ VCU_2_CRC : 7|16@0+ (1,0) [0|65535] ""  NIDU,BMC,DCU,CCURT2,ZCUF,ZCUL,ZCUR,ZCUT,IDC,ADC,VIU,IFC
 SG_ VCU_2_Counter : 23|8@0+ (1,0) [0|255] ""  NIDU,BMC,DCU,CCURT2,ZCUF,ZCUL,ZCUR,ZCUT,IDC,ADC,VIU,IFC
 SG_ VCU_DCU_ChgDisChgCapVoltReq : 61|10@0+ (1,0) [0|900] "V"  NIDU,DCU
 SG_ VCU_PlgConnSt : 256|1@0+ (1,0) [0|1] ""  NIDU,DCU,CCURT2,ZCUR,IDC,ADC,VIU
 SG_ VCU_DCU_BoostChgTargCurr : 288|12@0+ (0.1,0) [0|300] "A"  NIDU,DCU,CCURT2
 SG_ VCU_SwapHvBattModeStVD : 353|1@0+ (1,0) [0|1] ""  NIDU,ITS,EOP,BMC,DCDC,DCDC2,DCU,ZCUF,ZCUL,ZCUR,ZCUT,IPS,IDC,AMP,ADC,VIU,SBM,TBOX
 SG_ VCU_SwapHvBattModeSt : 356|2@0+ (1,0) [0|3] ""  NIDU,ITS,EOP,BMC,DCDC,DCDC2,DCU,ZCUF,ZCUL,ZCUR,ZCUT,IPS,IDC,AMP,ADC,VIU,SBM,TBOX
 SG_ VCU_DCU_DisChgTargCurr : 417|12@0+ (0.1,0) [0|300] "A"  NIDU,DCU,CCURT2
 SG_ VCU_AHF_TarPwr : 437|10@0+ (20,0) [0|20460] "W"  NIDU,DCU,CCURT2

BO_ 952 VCU_3: 64 CCU
 SG_ VCU_3_CRC : 7|16@0+ (1,0) [0|65535] ""  NIDU,ITS,BMC,DCU,CCURT2,IDC
 SG_ VCU_3_Counter : 23|8@0+ (1,0) [0|255] ""  NIDU,ITS,BMC,DCU,CCURT2,IDC
 SG_ VCU_MotorLoopEstimatedFlow : 31|8@0+ (0.1,0) [0|20] "L/min"  NIDU,DCU
 SG_ VCU_MotorLoopEstimatedFlowVD : 39|2@0+ (1,0) [0|3] ""  NIDU,DCU
 SG_ VCU_EM3To2ValveEn : 188|1@0+ (1,0) [0|1] ""  NIDU,DCU,CCURT2
 SG_ VCU_CtrlPwmDucycLT : 179|7@0+ (1,0) [0|100] "%"  NIDU,DCU,CCURT2
 SG_ VCU_DiagLTPump : 195|3@0+ (1,0) [0|7] ""  NIDU,DCU,CCURT2
 SG_ VCU_CtrlPwmDucycMT : 187|7@0+ (1,0) [0|100] "%"  NIDU,DCU,CCURT2
 SG_ VCU_DiagMTPump : 192|3@0+ (1,0) [0|7] ""  NIDU,DCU,CCURT2

BO_ 930 VCU_8: 64 CCU
 SG_ VCU_8_CRC : 7|16@0+ (1,0) [0|65535] ""  NIDU,BMC,DCU,CCURT2,ZCUF,ZCUL,ZCUR,ZCUT
 SG_ VCU_8_Counter : 23|8@0+ (1,0) [0|255] ""  NIDU,BMC,DCU,CCURT2,ZCUF,ZCUL,ZCUR,ZCUT
 SG_ VCU_BoostChgTargCurr : 31|12@0+ (0.1,0) [0|300] "A"  NIDU,BMC,DCU
 SG_ VCU_DisChgTargCurr : 35|12@0+ (0.1,0) [0|300] "A"  NIDU,BMC,DCU
 SG_ VCU_BoostChgMode : 53|1@0+ (1,0) [0|1] ""  NIDU,BMC,DCU
 SG_ VCU_K2RlyAdhDetn : 54|1@0+ (1,0) [0|1] ""  NIDU,BMC,BCB,DCU
 SG_ VCU_CCUBCBPowerSup : 55|1@0+ (1,0) [0|1] ""  NIDU,BMC,BCB,DCU
 SG_ VCU_TargetPosReq_1 : 71|8@0+ (1,0) [0|255] "%"  NIDU,ZCUF,ZCUL
 SG_ VCU_DcChgVoltOutReq : 143|16@0+ (0.1,0) [0|6553.5] "V"  NIDU,BMC,DCU,CCURT2
 SG_ VCU_PreChgTargVolt : 201|14@0+ (0.1,0) [0|1000] "V"  NIDU,BMC,DCU
 SG_ VCU_BoostChgTargVolt : 219|14@0+ (0.1,0) [0|1000] "V"  NIDU,BMC,DCU
 SG_ VCU_AHFActivatePwr : 237|14@0+ (10,0) [0|163830] "W"  NIDU,DCU,CCURT1
 SG_ VCU_TMS_AHFDelayEn : 256|1@0+ (1,0) [0|1] ""  NIDU,DCU,CCURT1
 SG_ VCU_TMS_AHFShutImme : 257|1@0+ (1,0) [0|1] ""  NIDU,DCU,CCURT1
 SG_ VCU_DCU_IdcMeasure : 255|14@0+ (0.1,-819.2) [-819.2|819.1] "A"  NIDU,DCU,CCURT1
 SG_ VCU_TMS_AHFActivationSt : 271|3@0+ (1,0) [0|7] ""  NIDU,DCU,CCURT1

BO_ 2634022912 XCP_Frame_Rx: 8 Tester
 SG_ XCP_Data_Rx : 7|64@0+ (1,0) [0|0] ""  NIDU,DCU

BO_ 2634022913 XCP_Frame_Tx: 8 NIDU
 SG_ XCP_Data_Tx : 7|64@0+ (1,0) [0|0] ""  Tester

BO_ 1279 DCU_BigData: 64 NIDU
 SG_ DCU_Data1No M : 7|8@0+ (1,0) [0|205] ""  CCU
 SG_ DCU_Hwversion m1 : 15|16@0+ (1,0) [0|65535] ""  CCU
 SG_ DCU_Swversion m1 : 31|16@0+ (1,0) [0|65535] ""  CCU
 SG_ DCU_SwVerExt m1 : 47|32@0+ (1,0) [0|4294967295] ""  CCU
 SG_ DCU_OffsetAngle m1 : 79|12@0+ (1,0) [0|4095] ""  CCU
 SG_ DCU_BootSV m1 : 83|12@0+ (1,0) [0|4095] ""  CCU
 SG_ DCU_BSWVersion m1 : 103|32@0+ (1,0) [0|4294967295] ""  CCU
 SG_ DCU_HWConfig m1 : 135|32@0+ (1,0) [0|4294967295] ""  CCU
 SG_ DCU_SWConfig m1 : 167|32@0+ (1,0) [0|4294967295] ""  CCU
 SG_ DCU_MCAConfig m1 : 199|32@0+ (1,0) [0|4294967295] ""  CCU
 SG_ DCU_FHConfig m1 : 231|32@0+ (1,0) [0|4294967295] ""  CCU
 SG_ DCU_InvtPhaUTemp m1 : 263|8@0+ (1,-40) [-40|214] "degC"  CCU
 SG_ DCU_InvtPhaVTemp m1 : 271|8@0+ (1,-40) [-40|214] "degC"  CCU
 SG_ DCU_InvtPhaWTemp m1 : 279|8@0+ (1,-40) [-40|214] "degC"  CCU
 SG_ DCU_Stat1Temp m1 : 287|8@0+ (1,-40) [-40|214] "degC"  CCU
 SG_ DCU_Stat2Temp m1 : 295|8@0+ (1,-40) [-40|214] "degC"  CCU
 SG_ DCU_CtrlBoardTemp m1 : 303|8@0+ (1,-40) [-40|214] "degC"  CCU
 SG_ DCU_DrvBoardTemp m1 : 311|8@0+ (1,-40) [-40|214] "degC"  CCU
 SG_ DCU_CapTemp m1 : 319|8@0+ (1,-40) [-40|214] "degC"  CCU
 SG_ DCU_FaultData_RC m2 : 15|8@0+ (1,0) [0|255] ""  CCU
 SG_ DCU_stMode m2 : 21|4@0+ (1,0) [0|15] ""  CCU
 SG_ DCU_stPWMEna m2 : 22|1@0+ (1,0) [0|1] ""  CCU
 SG_ DCU_stHandleOff m2 : 23|1@0+ (1,0) [0|1] ""  CCU
 SG_ DCU_FailCode m2 : 17|10@0+ (1,0) [0|1023] ""  CCU
 SG_ DCU_stASCProt m2 : 39|16@0+ (1,0) [0|65535] ""  CCU
 SG_ DCU_agRotorPosn m2 : 55|12@0+ (1,0) [0|4095] ""  CCU
 SG_ DCU_iCurdFinalRef m2 : 59|12@0+ (1,-2048) [-2048|2047] "A"  CCU
 SG_ DCU_iCurqFinalRef m2 : 79|12@0+ (1,-2048) [-2048|2047] "A"  CCU
 SG_ DCU_iCurdFb m2 : 83|12@0+ (1,-2048) [-2048|2047] "A"  CCU
 SG_ DCU_iCurqFb m2 : 103|12@0+ (1,-2048) [-2048|2047] "A"  CCU
 SG_ DCU_iPhaCurU m2 : 107|12@0+ (1,-2048) [-2048|2047] "A"  CCU
 SG_ DCU_iPhaCurV m2 : 127|12@0+ (1,-2048) [-2048|2047] "A"  CCU
 SG_ DCU_iPhaCurW m2 : 131|12@0+ (1,-2048) [-2048|2047] "A"  CCU
 SG_ DCU_uVoltdFinalRef m2 : 151|12@0+ (1,-2048) [-2048|2047] "V"  CCU
 SG_ DCU_uVoltqFinalRef m2 : 155|12@0+ (1,-2048) [-2048|2047] "V"  CCU
 SG_ DCU_iDcCur m2 : 175|12@0+ (1,-2048) [-2048|2047] "A"  CCU
 SG_ DCU_OperatingCycle m2 : 179|18@0+ (1,0) [0|262143] ""  CCU
 SG_ DCU_RelativeTime m2 : 193|18@0+ (1,0) [0|262143] "s"  CCU
 SG_ DCU_stFaultFlag100us m2 : 223|16@0+ (1,0) [0|65535] ""  CCU
 SG_ DCU_PWMFreq m2 : 239|16@0+ (1,0) [0|65535] "Hz"  CCU
 SG_ DCU_uDcVolt m2 : 255|10@0+ (1,0) [0|1023] "V"  CCU
 SG_ DCU_uLowVolt m2 : 261|8@0+ (0.1,0) [0|25.5] "V"  CCU
 SG_ DCU_ResFaultFlag m2 : 269|16@0+ (1,0) [0|65535] ""  CCU
 SG_ DCU_stTsc m2 : 285|16@0+ (1,0) [0|65535] ""  CCU
 SG_ DCU_stIGBTFault m2 : 301|16@0+ (1,0) [0|65535] ""  CCU
 SG_ DCU_Month m2 : 325|4@0+ (1,0) [1|12] "M"  CCU
 SG_ DCU_Year m2 : 317|8@0+ (1,2000) [2000|2255] "Y"  CCU
 SG_ DCU_Hour m2 : 332|5@0+ (1,0) [0|23] "h"  CCU
 SG_ DCU_Day m2 : 321|5@0+ (1,0) [1|31] "D"  CCU
 SG_ DCU_Minute m2 : 343|6@0+ (1,0) [0|59] "m"  CCU
 SG_ DCU_Second m2 : 337|6@0+ (1,0) [0|59] "s"  CCU
 SG_ DCU_stSBCFault m2 : 367|16@0+ (1,0) [0|65535] ""  CCU,Rema1
 SG_ DCU_stBigDataTrigger m2 : 347|4@0+ (1,0) [0|15] ""  CCU,Rema1
 SG_ DCU_FaultData_8Bit_2 m2 : 391|8@0+ (1,0) [0|255] ""  CCU,Rema1
 SG_ DCU_FaultData_8Bit_1 m2 : 383|8@0+ (1,0) [0|255] ""  CCU,Rema1
 SG_ DCU_FaultData_4Bit_3 m2 : 355|4@0+ (1,0) [0|15] ""  CCU,Rema1
 SG_ DCU_FaultData_4Bit_2 m2 : 359|4@0+ (1,0) [0|15] ""  CCU,Rema1
 SG_ DCU_FaultData_8Bit_3 m2 : 399|8@0+ (1,0) [0|255] ""  CCU,Rema1
 SG_ DCU_FaultData_8Bit_4 m2 : 407|8@0+ (1,0) [0|255] ""  CCU,Rema1
 SG_ DCU_FaultData_12Bit_2 m2 : 415|12@0+ (1,0) [0|4095] ""  CCU,Rema1
 SG_ DCU_FaultData_12Bit_3 m2 : 419|12@0+ (1,0) [0|4095] ""  CCU,Rema1
 SG_ DCU_FaultData_16Bit_2 m2 : 439|16@0+ (1,0) [0|65535] ""  CCU,Rema1
 SG_ DCU_FaultData_20Bit_1 m2 : 455|20@0+ (1,0) [0|1048575] ""  CCU,Rema1
 SG_ DCU_FaultData_1Bit_1 m2 : 467|1@0+ (1,0) [0|1] ""  CCU,Rema1
 SG_ DCU_FaultData_1Bit_2 m2 : 466|1@0+ (1,0) [0|1] ""  CCU,Rema1
 SG_ DCU_FaultData_1Bit_3 m2 : 465|1@0+ (1,0) [0|1] ""  CCU,Rema1
 SG_ DCU_FaultData_1Bit_4 m2 : 464|1@0+ (1,0) [0|1] ""  CCU,Rema1
 SG_ DCU_FaultData_4Bit_1 m2 : 479|4@0+ (1,0) [0|15] ""  CCU,Rema1
 SG_ DCU_FaultData_12Bit_1 m2 : 475|12@0+ (1,-2048) [-2048|2047] ""  CCU,Rema1
 SG_ DCU_FaultData_16Bit_1 m2 : 495|16@0+ (1,0) [0|65535] ""  CCU,Rema1
 SG_ DCU_FusaFaultInfo8_1 m1 : 395|32@0+ (1,0) [0|4294967295] ""  CCU,Rema1
 SG_ DCU_FusaFaultInfo7_1 m1 : 363|32@0+ (1,0) [0|4294967295] ""  CCU,Rema1
 SG_ DCU_FusaTorqAct_1 m1 : 344|13@0+ (0.2,-819) [-819|819] ""  CCU,Rema1
 SG_ DCU_FusastSafePathReq_1 m1 : 327|3@0+ (1,0) [0|7] ""  CCU,Rema1
 SG_ DCU_FusastPWMEna_1 m1 : 335|1@0+ (1,0) [0|1] ""  CCU,Rema1
 SG_ DCU_FusaRotSpdAct_1 m1 : 328|16@0+ (1,-32767) [-32767|32766] ""  CCU,Rema1
 SG_ DCU_FusaQDisChargeReq_1 m1 : 320|1@0+ (1,0) [0|0] ""  CCU,Rema1
 SG_ DCU_FusaModeSt_1 m1 : 324|4@0+ (1,0) [0|15] ""  CCU,Rema1
 SG_ DCU_FusaErrCode_1 m1 : 334|6@0+ (1,0) [0|63] ""  CCU,Rema1

CM_ SG_ 356 BCB_C2VoltA "Capacitance C2 voltage A";
CM_ SG_ 356 BCB_C2VoltB "Capacitance C2 voltage B";
CM_ SG_ 356 BCB_C2VoltC "Capacitance C2 voltage C";
CM_ SG_ 1025 BCB_2_CRC "E2E Profile 5 CRC";
CM_ SG_ 1025 BCB_2_Counter "E2E Profile 5 Counter";
CM_ SG_ 1025 BCB_BoostRlyStK3 "State of  the Boost Relay K3";
CM_ SG_ 1025 BCB_BoostRlyStK2 "State of  the Boost Relay K2";
CM_ SG_ 1025 BCB_C2Temp1 "Capacitance C2 temperature 1";
CM_ SG_ 1025 BCB_C2Temp2 "Capacitance C2 temperature 2";
CM_ SG_ 1025 BCB_C2Temp3 "Capacitance C2 temperature 3";
CM_ SG_ 1025 BCB_Fault "Fault information of BCB";
CM_ SG_ 1025 BCB_C2Temp4 "Capacitance C2 temperature 4";
CM_ SG_ 408 BMC_1_CRC "E2E Profile 5 CRC";
CM_ SG_ 408 BMC_1_Counter "E2E Profile 5 Counter";
CM_ SG_ 408 BMC_BattCurr "actual current of battery";
CM_ SG_ 408 BMC_DCUBattSt "working state of battery system for DCU";
CM_ SG_ 408 BMC_BattVolt "actual voltage of battery pack (inside of main relay)";
CM_ SG_ 408 BMC_BoostChgModeReq "Mode request of the boost Charge";
CM_ SG_ 408 BMC_PwrDwnReq "Emergency power-off warning. when the HV battery needs an emergency power-off, this signal is used to notify each HV node. The received node should reduce their power? to 0? as soon as possible.";
CM_ SG_ 408 BMC_BoostRlyK3St "State of? the Boost Relay K3";
CM_ SG_ 408 BMC_BoostRlyK2St "State of? the Boost Relay K2";
CM_ SG_ 408 BMC_DCVolt "Voltage outside DC charging contactor";
CM_ SG_ 408 BMC_DriveBoostRlyK3Sts "Drive command for Boost K3 contactor";
CM_ SG_ 408 BMC_BoostRlyK3Sts "State of  the Boost Relay K3";
CM_ SG_ 408 BMC_C2VoltA "Capacitance C2 voltage A";
CM_ SG_ 408 BMC_C2VoltB "Capacitance C2 voltage B";
CM_ SG_ 408 BMC_DriveBoostRlyK2Sts "Drive command for Boost K2 contactor";
CM_ SG_ 408 BMC_C2VoltC "Capacitance C2 voltage C";
CM_ SG_ 408 BMC_BoostRlyK2Sts "State of  the Boost Relay K2";
CM_ SG_ 888 BMC_SepaHeatSt "BMS separate heat heat state";
CM_ SG_ 1095 BMC_RlyK3Req "Request of  the Boost Relay K3";
CM_ SG_ 1095 BMC_MainloopDischgReq "Main Loop Discharge request";
CM_ SG_ 1095 BMC_C2DisChgSt "Capacitance C2 Discharge state";
CM_ SG_ 1095 BMC_BoostChgSt "Boost charge state";
CM_ SG_ 1095 BMC_RlyK2Req "Request of  the Boost Relay K2";
CM_ SG_ 1098 BMC_C2Temp1 "Capacitance C2 temperature 1";
CM_ SG_ 1098 BMC_C2Temp2 "Capacitance C2 temperature 2";
CM_ SG_ 1098 BMC_C2Temp3 "Capacitance C2 temperature 3";
CM_ SG_ 1098 BMC_BCBFault "Fault information of BMC BCB";
CM_ SG_ 1098 BMC_C2Temp4 "Capacitance C2 temperature 4";
CM_ SG_ 812 BMS_DCCurrRx "current received from DC charger";
CM_ SG_ 812 BMS_DCVoltRx "voltage received from DC charger";
CM_ SG_ 812 BMS_AcChgVoltMax "Maximum permissive AC charge valtage of HV battery";
CM_ SG_ 812 BMS_BoostChgModeReq "Mode request of the boost Charge";
CM_ SG_ 812 BMS_CoolantTargTemp "Target temperature of coolant from BMS";
CM_ SG_ 1377 BMC_NMNodeAddress "BMC node address";
CM_ SG_ 1377 BMC_NMCBV "BMC Network management  control bit vector";
CM_ SG_ 1377 BMC_NMWakeupOrigin "Origin of the wake up";
CM_ SG_ 1377 BMC_PNCInformation0 "PNC Information";
CM_ SG_ 1377 BMC_PNCInformation1 "PNC Information";
CM_ SG_ 616 CCU_1_CRC "E2E Profile 5 CRC";
CM_ SG_ 616 CCU_1_Counter "E2E Profile 5 Counter";
CM_ SG_ 616 UMM_UsageModeSt "Usage mode state";
CM_ SG_ 616 VMM_LastVehModeSt "Last time vehicle mode";
CM_ SG_ 616 VMM_VehModeSt "Vehicle mode state";
CM_ SG_ 616 VMM_OTAModeSt "OTA Mode state";
CM_ SG_ 616 Time_Year "Year number";
CM_ SG_ 616 Time_Month "Month number";
CM_ SG_ 616 Time_Hour "Hour number";
CM_ SG_ 616 Time_Day "Day number";
CM_ SG_ 616 Time_Min "Minute number";
CM_ SG_ 616 Time_Sec "Second number";
CM_ SG_ 816 HVAC_PTCPwrConsmp "PTC power consumption";
CM_ SG_ 816 HVAC_CorrectedExterTemp "Corrected External temperature";
CM_ SG_ 816 HVAC_PTCHeatingReq "PTC Heating Duty request";
CM_ SG_ 816 HVAC_CorrectedExterTempVD "External temperature valid data";
CM_ SG_ 816 HVAC_PTCSt "HVAC's PTC OFF or dowmshift status";
CM_ SG_ 816 HVAC_ECPPwrConsump "ECP power consumption";
CM_ SG_ 816 HVAC_PTCOnReq "Enables operation of HV-PTC";
CM_ SG_ 615 BCS_1_CRC "E2E Profile 5 CRC";
CM_ SG_ 615 BCS_1_Counter "E2E Profile 5 Counter";
CM_ SG_ 615 BCS_FLWheelSpdVD "Quality/fault information to current wheel speed of front left wheel";
CM_ SG_ 615 BCS_FLWheelSpd "Current wheel speed information of front left wheel";
CM_ SG_ 615 BCS_FRWheelSpdVD "Quality/fault information to current wheel speed of front left wheel";
CM_ SG_ 615 BCS_FRWheelSpd "Current wheel speed information of front left wheel";
CM_ SG_ 615 BCS_RLWheelSpdVD "Quality/fault information to current wheel speed of front left wheel";
CM_ SG_ 615 BCS_RLWheelSpd "Current wheel speed information of front left wheel";
CM_ SG_ 615 BCS_RRWheelSpdVD "Quality/fault information to current wheel speed of RRont left wheel";
CM_ SG_ 615 BCS_RRWheelSpd "Current wheel speed information of RRont left wheel";
CM_ SG_ 615 BCS_HDCCtrlSt "HDC(Hill Descent Control) control status";
CM_ SG_ 615 BCS_HHCCtrlSt "HHC(Hill Hold Control) control status";
CM_ SG_ 615 BCS_AVHSt "Indicates AVH(Auto Vehicle Hold)in active or not ";
CM_ SG_ 615 IPB_InputRodStroke "Indicate inputRod stroke value";
CM_ SG_ 615 IPB_PlungerPressureSt "Indicate plunger pressure status";
CM_ SG_ 615 IPB_InputRodStrokeSt "Indicate inputRod stroke status";
CM_ SG_ 615 IPB_PlungerPressure "Indicate plunger pressure value";
CM_ SG_ 352 BCS_2_CRC "E2E Profile 5 CRC";
CM_ SG_ 352 BCS_2_Counter "E2E Profile 5 Counter";
CM_ SG_ 352 BCS_EBDActiveSt "Indication that EBD system currently performs a brake/engine intervention";
CM_ SG_ 352 BCS_VehSpd "Vehicle speed";
CM_ SG_ 352 BCS_VDCFaultSt "VDC is switched off due to detected failure";
CM_ SG_ 352 BCS_VDCActiveSt "Indication that VDC system currently performs a brake/engine intervention when ESP adjust the posture of vehicle ";
CM_ SG_ 352 BCS_TCSFaultSt "TCS is switched off due to detected failure";
CM_ SG_ 352 BCS_TCSActiveSt "Indication that TCS system currently performs a brake/engine intervention";
CM_ SG_ 352 BCS_ABSFaultSt "ABS system has detected a failure which does no allow a reliable ABS regulation and is therefore switched off";
CM_ SG_ 352 BCS_ABSActiveSt "Indication that ABS system currently performs a brake intervention";
CM_ SG_ 352 BCS_EBDFaultSt "ABS system has detected a heavy fault, which does not even allow a reliable electronic brake distribution and is therefore completely shut down";
CM_ SG_ 352 BCS_EngTorqDecActiveSt "Decrease enginetorque  active status (fast and low)";
CM_ SG_ 352 BCS_RegenModuleActive "Reduce repcuperation torque requested by oppotize TCS control active status";
CM_ SG_ 352 BCS_DMCTarSpdFA "Engine rotational target speed for TCS-DMCIt is calculated continuously, but used only in the case of an vehicle acceleXAtion request. The signal is modified by ESPdepending on the driving situation and the opeXAtion mode. The signal is sent as an absolute value irrespective offorward or reverse driving direction. For reverse driving, necessary transformations must be done in PE.";
CM_ SG_ 352 BCS_DMCCtrModeFA "Control mode for TCS-DMCSignal contains the release state of the TCS function for the vehicle, e.g. initialization/release/degeradation.";
CM_ SG_ 352 BCS_DMCVariant "ESP variant info, mainly used for handshake check";
CM_ SG_ 352 BCS_DMCTarSpdRA "Engine rotational target speed for TCS-DMCIt is calculated continuously, but used only in the case of an vehicle acceleXAtion request. The signal is modified by ESPdepending on the driving situation and the opeXAtion mode. The signal is sent as an absolute value irrespective offorward or reverse driving direction. For reverse driving, necessary transformations must be done in PE.";
CM_ SG_ 352 BCS_DMCCtrModeRA "Control mode for TCS-DMCSignal contains the release state of the TCS function for the vehicle, e.g. initialization/release/degeradation.";
CM_ SG_ 352 BCS_EngTorqDecActiveStRA "Decrease enginetorque  active status (fast and low) for Rear Axle";
CM_ SG_ 363 EPS_SteeringAngle "steering wheel angle";
CM_ SG_ 363 EPS_SteeringAngleVD "indicate that Angle VD";
CM_ SG_ 351 ACU_ACChgCurCfg "ACCharge current setting  to IPS";
CM_ SG_ 1359 CCU_NMNodeAddress "CCU node address";
CM_ SG_ 1359 CCU_NMCBV "CCU Network management  control bit vector";
CM_ SG_ 1359 CCU_PNCInformation0 "PNC Information";
CM_ SG_ 1359 CCU_PNCInformation1 "PNC Information";
CM_ SG_ 290 IPDS_RearEOPPowerSup "Rear EOP power supply";
CM_ SG_ 290 IPDS_KL15T1PowerSup "KL15 T1 power supply";
CM_ SG_ 290 IPDS_BCBPowerSup "BCB power supply";
CM_ SG_ 290 IPDS_FrontEOPPowerSup "Front EOP power supply";
CM_ SG_ 909 EPB_ActuatorSt_L "EPB left  actuator status";
CM_ SG_ 909 EPB_ActuatorSt_R "EPB right  actuator status";
CM_ SG_ 909 EPB_SysSt "EPB system status";
CM_ SG_ 902 IPDS_RearMotorPowerSt "Rear motor power state";
CM_ SG_ 902 IPDS_RearEOPPowerSt "Rear EOP power state";
CM_ SG_ 902 IPDS_RearMotorPowerFaultSt "Rear motor power Fault state";
CM_ SG_ 902 IPDS_RearEOPPowerFaultSt "Rear EOP power Fault state";
CM_ SG_ 902 IPDS_KL15T1PowerSt "KL15 T1 power state";
CM_ SG_ 902 IPDS_BCBPowerFaultSt "BCB power Fault state";
CM_ SG_ 902 IPDS_BCBPowerSt "BCB power state";
CM_ SG_ 1291 DCDC_NMNodeAddress "DCDC node address";
CM_ SG_ 1291 DCDC_NMCBV "DCDC Network management  control bit vector";
CM_ SG_ 1291 DCDC_NMWakeupOrigin "Origin of the wake up";
CM_ SG_ 1291 DCDC_PNCInformation0 "PNC Information";
CM_ SG_ 1291 DCDC_PNCInformation1 "PNC Information";
CM_ SG_ 1308 DCDC2_NMNodeAddress "DCDC2 node address";
CM_ SG_ 1308 DCDC2_NMCBV "DCDC2 Network management  control bit vector";
CM_ SG_ 1308 DCDC2_NMWakeupOrigin "Origin of the wake up";
CM_ SG_ 1308 DCDC2_PNCInformation0 "PNC Information";
CM_ SG_ 1308 DCDC2_PNCInformation1 "PNC Information";
CM_ SG_ 368 DCU_1_CRC "E2E Profile 5 CRC";
CM_ SG_ 368 DCU_1_Counter "E2E Profile 5 Counter";
CM_ SG_ 368 DCU_RotSpdAct "actual rotation speed of drvie motor";
CM_ SG_ 368 DCU_IdcAct "actual current at HV of DCU";
CM_ SG_ 368 DCU_CCUEOPPowerSup "DCU request CCU give EOP power supply";
CM_ SG_ 368 DCU_UdcAct "actual voltage at HV of DCU";
CM_ SG_ 368 DCU_ModeSt "mode status of drive motor";
CM_ SG_ 368 DCU_HvilSt "DCU send HVIL status by itself";
CM_ SG_ 368 DCU_TorqMax "maximum positive Torque allowed (motor)";
CM_ SG_ 368 DCU_TorqMin "maximum negative torque allowed (generator)";
CM_ SG_ 368 DCU_DMCInternalInputQF "Qualify for all input signals form MCU to DMCIf any input signal invalid during calculation phase (Including all possilbility like signals invalid value  message error MCU status) once InputQF=false  If valid then InputQF=true";
CM_ SG_ 368 DCU_SelfTorqMax "Actual value of maximum positive Torque without Idc max limit";
CM_ SG_ 368 DCU_DstActive "Surge Damping state active";
CM_ SG_ 368 DCU_SelfTorqMin "Actual value maximum negative torque? without Idc mini limit";
CM_ SG_ 368 DCU_DiagErrCode "DCU diagnostics error code";
CM_ SG_ 368 DCU_GateDrvSt "state of gate driver";
CM_ SG_ 368 DCU_DMCInternalInit "Init check for DMC SW part during DMC initialize phase set to 1 once DMC init successfully then set to 0";
CM_ SG_ 368 DCU_DMCOperationStToBCS "Indicates the status of the DMC.";
CM_ SG_ 368 DCU_DMCInternalTorqSet "DMC torque targetControl output of DMC used as torque target for further processing in the power electronicsThis signal must be implemented in 4Quadrant coordinates";
CM_ SG_ 368 DCU_DMCoutputTorqToBCS "DMC torque target.Control output of DMC used as torque target for further processing in the ESP/IPB for lamp usage and target torqueadjustment during dynamic mode.This signal must be implemented in 1Quadrant coordinates";
CM_ SG_ 368 DCU_DMCVersionInfoToBCS "DMC VersionInfo including variant info, mainly used for handshake check";
CM_ SG_ 368 DCU_DMCVariantInfoToBCS "DMC VariantInfo including variant info, mainly used for handshake check";
CM_ SG_ 368 DCU_TorqAct "actual torque of drive motor";
CM_ SG_ 368 DCU_EOP_SpdSet "requestable oil pump speed";
CM_ SG_ 864 DCU_2_CRC "E2E Profile 5 CRC";
CM_ SG_ 864 DCU_2_Counter "E2E Profile 5 Counter";
CM_ SG_ 864 DCU_BoostChgPwrMax "Available Boost charging power about DCU";
CM_ SG_ 864 DCU_AHF_ActPwr "DCU send calculated AHF powerto VCU";
CM_ SG_ 864 DCU_BoostCurrMax "Available Boost max current  about DCU";
CM_ SG_ 864 DCU_OffsetCalInd "indication of ï¿½ï¿½ffset calibration successfull flag";
CM_ SG_ 864 DCU_bReadyHV "HV voltage operational";
CM_ SG_ 864 DCU_bDiagReq "Diag request for e-machine Inverter Calibration";
CM_ SG_ 864 DCU_TypeSt "DCU type state for configuration";
CM_ SG_ 864 DCU_RemoteDiagCode "The flag that ECU need to be remote diagnosed";
CM_ SG_ 864 DCU_DisChgPwrMax "Available discharging power about DCU";
CM_ SG_ 864 DCU_InvtTemp "Current temperature of inverter";
CM_ SG_ 864 DCU_SysTempOvrInd "Indicator of overheat warning lamp, which is lighten if temperature of drive motor system is too high.";
CM_ SG_ 864 DCU_VoltageT30 "Current UT30 Voltage at inverter";
CM_ SG_ 864 DCU_RotTemp "Current temperature of rotor";
CM_ SG_ 864 DCU_FaultLampInd "Warning indicator to lighten fault lamp (Malfunction Indication Lamp,MIL)";
CM_ SG_ 864 DCU_CooltReq "Requested DCU coolant massflow";
CM_ SG_ 864 DCU_StatTemp "Current temperature of stator";
CM_ SG_ 864 DCU_ErrNoticeOperationFlag "Operation flag for DCU error notice";
CM_ SG_ 864 DCU_TempCoolant "temperature of inverter cooling water";
CM_ SG_ 864 DCU_Err2NoticeFlag "Lever2 Error for DCU Popup?flag";
CM_ SG_ 864 DCU_ErrNotice "DCU error notice";
CM_ SG_ 864 DCU_K2RlyAdhmode "K2 Relay adhesion detection mode";
CM_ SG_ 864 DCU_BuckCurrMax "Available Buck max current  about DCU";
CM_ SG_ 864 DCU_TEL_UdcAct "actual voltage at HV of DCU";
CM_ SG_ 864 DCU_TEL_MotorNumOrder "The order number of motors in the vehicle (this value cannot be larger than the total number)";
CM_ SG_ 864 DCU_TEL_ECUTempOvrErr "The  temperature  of ECU is too high";
CM_ SG_ 864 DCU_TEL_MotTempOvrErr "The  temperature  of Motor is too high";
CM_ SG_ 864 DCU_TEL_MotorNumTotal "The total number of motors in the vehicle";
CM_ SG_ 864 DCU_TEL_InvtTemp "Current temperature of inverter";
CM_ SG_ 864 DCU_TEL_RotSpdAct "actual rotation speed of drvie motor";
CM_ SG_ 864 DCU_TEL_TorqAct "actual torque of drive motor";
CM_ SG_ 864 DCU_TEL_StatTemp "Current temperature of stator";
CM_ SG_ 864 DCU_TEL_CurrActAmend "actual current at HV of DCUï¿½ï¿½by amendï¿½ï¿½";
CM_ SG_ 864 DCU_TEL_BattCurr "actual current of battery(BMS_BattCurr)";
CM_ SG_ 864 DCU_TEL_ModeSt "Mode state for TEL ONLY";
CM_ SG_ 864 DCU_IgnitionSt "State of DCU Ignition";
CM_ SG_ 875 DCU_3_CRC "E2E Profile 5 CRC";
CM_ SG_ 875 DCU_3_Counter "E2E Profile 5 Counter";
CM_ SG_ 875 DCU_PTCDownShiftSt "PTC Heat DownShift State";
CM_ SG_ 875 DCU_PTCUpShiftSt "PTC Heat UpShift State";
CM_ SG_ 875 DCU_PTCHeatPower "Power of DCU PTC";
CM_ SG_ 875 DCU_PTCHeatCurrent "DC Current of DCU PTC";
CM_ SG_ 875 DCU_PTCFault "PTC fault information";
CM_ SG_ 875 DCU_AHFDownShiftSt "PTC Heat DownShift State";
CM_ SG_ 875 DCU_AHFUpShiftSt "PTC Heat UpShift State";
CM_ SG_ 875 DCU_PTCInterTemp "PTC's media temperture internal signal in PTC";
CM_ SG_ 875 DCU_PTCModeSt "PTC Mode ";
CM_ SG_ 875 DCU_PTCMOSTemp "PTC MOSFET temperture ";
CM_ SG_ 875 DCU_FPWMMultiple "DCU PWM Multiple";
CM_ SG_ 875 DCU_AHFModeSt "AHF Mode State";
CM_ SG_ 875 DCU_AHFPwrMax "Max Power of AHF";
CM_ SG_ 875 DCU_AHFPwrMin "Min Power of AHF";
CM_ SG_ 875 DCU_AHFCurrentReq "Requset AHF Current";
CM_ SG_ 875 DCU_AHFCurrentAct "Act AHF Current";
CM_ SG_ 875 DCU_MotorTempEst "Estimated Motor Stator Temp";
CM_ SG_ 875 DCU_RotorPosn "Rotor Position";
CM_ SG_ 875 DCU_AHFPowerEst "Estimated Power of DCU AHF";
CM_ SG_ 875 DCU_AHFTorqueReq "AHF torque of drive motor";
CM_ SG_ 875 DCU_AHFTorqueAct "AHF torque of drive motor";
CM_ SG_ 1178 DCU_DTCCode9 "DCU  DTC Sent To CCU";
CM_ SG_ 1178 DCU_DTCCode8 "DCU  DTC Sent To CCU";
CM_ SG_ 1178 DCU_DTCCode7 "DCU  DTC Sent To CCU";
CM_ SG_ 1178 DCU_DTCCode6 "DCU  DTC Sent To CCU";
CM_ SG_ 1178 DCU_DTCCode5 "DCU  DTC Sent To CCU";
CM_ SG_ 1178 DCU_DTCCode4 "DCU  DTC Sent To CCU";
CM_ SG_ 1178 DCU_DTCCode3 "DCU  DTC Sent To CCU";
CM_ SG_ 1178 DCU_DTCCode2 "DCU  DTC Sent To CCU";
CM_ SG_ 1178 DCU_DTCCode15 "DCU  DTC Sent To CCU";
CM_ SG_ 1178 DCU_DTCCode14 "DCU  DTC Sent To CCU";
CM_ SG_ 1178 DCU_DTCCode13 "DCU  DTC Sent To CCU";
CM_ SG_ 1178 DCU_DTCCode12 "DCU  DTC Sent To CCU";
CM_ SG_ 1178 DCU_DTCCode11 "DCU  DTC Sent To CCU";
CM_ SG_ 1178 DCU_DTCCode10 "DCU  DTC Sent To CCU";
CM_ SG_ 1178 DCU_DTCCode1 "DCU  DTC Sent To CCU";
CM_ SG_ 1178 DCU_DTCCode0 "DCU  DTC Sent To CCU";
CM_ SG_ 384 EOP_1_CRC "E2E Profile 5 CRC";
CM_ SG_ 384 EOP_1_Counter "E2E Profile 5 Counter";
CM_ SG_ 384 EOP_SpdAct "Actual speed of oil pump";
CM_ SG_ 384 EOP_IphAct "oil pump phase current";
CM_ SG_ 384 EOP_IdcAct "oil pump DC current";
CM_ SG_ 384 EOP_UdcAct "actual voltage of oil pump";
CM_ SG_ 384 EOP_ErrLevel "to inform DCU that the error level of the EOP";
CM_ SG_ 384 EOP_Status "EOP Status";
CM_ SG_ 384 EOP_duty "duty cycle of oil pump";
CM_ SG_ 599 EVCC_1_CRC "E2E Profile 5 CRC";
CM_ SG_ 599 EVCC_1_Counter "E2E Profile 5 Counter";
CM_ SG_ 1533 EVCC_NMNodeAddress "EVCC node address";
CM_ SG_ 1533 EVCC_NMCBV "EVCC Network management  control bit vector";
CM_ SG_ 1533 EVCC_NMWakeupOrigin "Origin of the wake up";
CM_ SG_ 1533 EVCC_PNCInformation0 "PNC Information";
CM_ SG_ 1533 EVCC_PNCInformation1 "PNC Information";
CM_ SG_ 2015 Fun_Diag_Request "Diagnostic function request";
CM_ SG_ 704 IPS_1_CRC "E2E Profile 5 CRC";
CM_ SG_ 704 IPS_1_Counter "E2E Profile 5 Counter";
CM_ SG_ 704 IPS_DCDCDiagErrCode "DCDC diagnostics error code";
CM_ SG_ 704 IPS_KL15State "IPS or DCDC Enable state";
CM_ SG_ 704 IPS_DCDCModeSt "mode status of DCDC";
CM_ SG_ 704 IPS_DCDCVoltLvAct "actual LV voltage at DCDC";
CM_ SG_ 704 IPS_DCDCCurrHvAct "HV Current? of DCDC";
CM_ SG_ 704 IPS_DCDCCurrLvAct "LV Current? of DCDC";
CM_ SG_ 704 IPS_DCDCVoltHvAct "actual HV voltage at DCDC";
CM_ SG_ 704 IPS_OBCDiagErrCode "OBC diagnostics error code";
CM_ SG_ 704 IPS_OBCCC_St "Status of slow charging cable connection (CC) including type of connected cable (charging/V2V, or V2L)";
CM_ SG_ 704 IPS_OBCCpFreqSt "CP frequency is in the GB range";
CM_ SG_ 704 IPS_DchgOverload "Discharge Overload";
CM_ SG_ 704 IPS_OBCDschDisable "Status of control pilot signal (CP) for discharging";
CM_ SG_ 704 IPS_OBCCC_Res "CC Resistance value in Ohm";
CM_ SG_ 704 IPS_OBCModeSt "OBC mode state";
CM_ SG_ 704 IPS_OBCHvDcCurrAct "OBC HVDC actual current (Positive current+ï¿½ï¿½Charging mode output current from IPS to HVBAT, Negative current-: DisCharging mode input current from HVBAT)";
CM_ SG_ 704 IPS_OBCCPSt "Status of control pilot signal (CP) for charging";
CM_ SG_ 704 IPS_OBCCC_Cap "AC charging capability of the charging cable detected by OBC";
CM_ SG_ 704 IPS_OBCHvDcVoltAct "OBC HVDC voltage";
CM_ SG_ 704 IPS_OBCCpS2St "S2 swtich state";
CM_ SG_ 704 IPS_OBCCp_DutyCycle "CP Duty";
CM_ SG_ 704 IPS_OBCCPVolt "CP high level";
CM_ SG_ 704 IPS_OBCUacActL1 "L1 phase voltage";
CM_ SG_ 704 IPS_OBCUacActL3 "L3 phase voltage";
CM_ SG_ 704 IPS_OBCCurrActL1 "L1 phase current";
CM_ SG_ 704 IPS_OBCCurrActL2 "L2 phase current";
CM_ SG_ 704 IPS_OBCCurrActL3 "L3 phase current";
CM_ SG_ 704 IPS_smo_ObcModeSt "OBC basic StateMation";
CM_ SG_ 704 IPS_OBCUacActL2 "L2 phase voltage";
CM_ SG_ 704 IPS_smd_DcdcModeSt "DCDC basic StateMation";
CM_ SG_ 704 IPS_WakeOriginSignal2 "Wake up OriginSignal2";
CM_ SG_ 704 IPS_WakeOriginSignal1 "Wake up OriginSignal1";
CM_ SG_ 872 IPS_2_CRC "E2E Profile 5 CRC";
CM_ SG_ 872 IPS_2_Counter "E2E Profile 5 Counter";
CM_ SG_ 872 IPS_SwVersion "software version of IPS OR DCDC, according to GAC Definition (see Diagnostic Tables)";
CM_ SG_ 872 IPS_TEL_DCDCTempOvrErr "over temperature, DCDC not able to work, FOR TEL";
CM_ SG_ 872 IPS_TEL_DCDCFaultLampInd "Warning indicator to lighten fault lamp (Malfunction Indication Lamp, MIL), FOR TEL";
CM_ SG_ 872 IPS_RemoteDiagCode "The flag that ECU need to be remote diagnosed";
CM_ SG_ 872 IPS_HwSt "tell it is that IPS or DCDC(because they are same ID)";
CM_ SG_ 872 IPS_DCDCFlowReq "The DCDC required coolant flow speed? (L/min)";
CM_ SG_ 872 IPS_TEL_DCDCModeSt "mode status of DCDC for TEL";
CM_ SG_ 872 IPS_TempAct " internal temperature of IPS or DCDC( if it's DCDC)";
CM_ SG_ 872 IPS_HVDCHVilSt "IPS send DC side HVIL status measued by itself";
CM_ SG_ 872 IPS_DCDCKL30Volt "IPS or DCDC LV power supply voltage";
CM_ SG_ 872 IPS_DCDCState1 "DCDC state information 1";
CM_ SG_ 872 IPS_DCDCState2 "DCDC state information 2";
CM_ SG_ 872 IPS_DCDCState3 "DCDC state information 3";
CM_ SG_ 872 IPS_DCDCState4 "DCDC state information 4";
CM_ SG_ 872 IPS_DCDCState5 "DCDC state information 5";
CM_ SG_ 872 IPS_DCDCState6 "DCDC state information 6";
CM_ SG_ 872 IPS_OBCFlowReq "The OBC required coolant flow speed? (L/min)";
CM_ SG_ 872 IPS_OBCChgPwrMax "Available OBC charging power depending on provided current and voltage from charging station, limitations from cable OBC efficiency and OBC derating.";
CM_ SG_ 872 IPS_ChgCurRespAvail "To indicate if Charge current of HV IPS is available";
CM_ SG_ 872 IPS_ChgCurResp "Charge current response of IPS for display";
CM_ SG_ 872 IPS_ACHvilSt "IPS send AC side HVIL status measued by itself";
CM_ SG_ 872 IPS_OBCState1 "OBC state information 1";
CM_ SG_ 872 IPS_OBCState2 "OBC state information 2";
CM_ SG_ 872 IPS_OBCState3 "OBC state information 3";
CM_ SG_ 872 IPS_OBCState4 "OBC state information 4";
CM_ SG_ 872 IPS_OBCState5 "OBC state information 5";
CM_ SG_ 872 IPS_OBCFaultLampIndOperationFlag "Operation flag for  IPS_OBCFaultLampInd";
CM_ SG_ 872 IPS_DCDCFaultLampIndFlag "Popup?flag?for??DCDC?error?notice";
CM_ SG_ 872 IPS_DCDCFaultLampIndOperationFla "Operation flag for IPS_DCDCFaultLampInd";
CM_ SG_ 872 IPS_OBCState7 "OBC state information 7";
CM_ SG_ 872 IPS_OBCState8 "OBC state information 8";
CM_ SG_ 872 IPS_OBCState9 "OBC state information 9";
CM_ SG_ 872 IPS_OBCState10 "OBC state information 10";
CM_ SG_ 872 IPS_OBCState11 "OBC state information 11";
CM_ SG_ 872 IPS_DCDCState7 "DCDC state information 7";
CM_ SG_ 872 IPS_DCDCState8 "DCDC state information 8";
CM_ SG_ 872 IPS_DCDCState9 "DCDC state information 9";
CM_ SG_ 872 IPS_DCDCState10 "DCDC state information 10";
CM_ SG_ 872 IPS_OBCState6 "OBC state information 6";
CM_ SG_ 872 IPS_OBCAcIso_Res "AC Line Iso Res";
CM_ SG_ 2683306000 IPS_OBCHvVoltLimSet "Enable:OBCHvVoltLim up to 950v";
CM_ SG_ 2683306000 IPS_Disable_DCDCSelfChck "Enable: No DCDCFs";
CM_ SG_ 880 ITS_1_CRC "E2E Profile 5 CRC";
CM_ SG_ 880 ITS_1_Counter "E2E Profile 5 Counter";
CM_ SG_ 880 ITS_MotorPumpSt "Indicate The motor pump State";
CM_ SG_ 880 ITS_EMVSt "Indicate the state of EMV";
CM_ SG_ 880 ITS_ValvePositionAct "Indicate the actual position state of combined valve";
CM_ SG_ 880 ITS_BatteryPumpSt "Indicate The battery pump State";
CM_ SG_ 880 ITS_MotorInletTempErr "Motor Loop Temperature sensor error";
CM_ SG_ 880 ITS_MotorInletTemp "Motor Loop Temperature";
CM_ SG_ 880 ITS_BatteryInletTemp "Battery Loop In Temperature";
CM_ SG_ 880 ITS_ChillerInletTemp "Temperature of chiller inlet";
CM_ SG_ 880 ITS_BattOutletTsnsrErrCode "Battery outlet temperature sensor error code";
CM_ SG_ 880 ITS_MotorPumpSpdAct "Actual speed rate of the motor pump";
CM_ SG_ 880 ITS_ChlrExvErrCode "Chiller EXV error code";
CM_ SG_ 880 ITS_BatteryPumpSpdAct "Actual speed rate of the battery pump";
CM_ SG_ 1410 ITS_NMNodeAddress "ITS node address";
CM_ SG_ 1410 ITS_NMCBV "ITS Network management  control bit vector";
CM_ SG_ 1410 ITS_NMWakeupOrigin "Origin of the wake up";
CM_ SG_ 1410 ITS_PNCInformation0 "PNC Information";
CM_ SG_ 1410 ITS_PNCInformation1 "PNC Information";
CM_ SG_ 1790 NIDU_Diag_Response "DCU diagnostic response";
CM_ SG_ 1406 NIDU_NMNodeAddress "NIDU node address";
CM_ SG_ 1406 NIDU_NMCBV "NIDU Network management control bit vector";
CM_ SG_ 1406 NIDU_NMWakeupOrigin "Origin of the wake up";
CM_ SG_ 1406 NIDU_PNCInformation0 "PNC Information";
CM_ SG_ 1406 NIDU_PNCInformation1 "PNC Information";
CM_ SG_ 1662 NIDU_Diag_Request "Diagnostic physical request";
CM_ SG_ 818 TMS_1_CRC "E2E Profile 5 CRC";
CM_ SG_ 818 TMS_1_Counter "E2E Profile 5 Counter";
CM_ SG_ 818 TMS_MotorLoopEstimatedFlow "Estimated flow of the motor loop";
CM_ SG_ 818 TMS_CtrlPwmDucycLT "Duty Cycle(Ducyc) to control LT Pump";
CM_ SG_ 818 TMS_MotorLoopEstimatedFlowVD "whether the estimated flow of the motor loop is valid";
CM_ SG_ 818 TMS_CtrlPwmDucycMT "Duty Cycle(Ducyc) to control MT Pump";
CM_ SG_ 818 TMS_DiagMTPump "Diagnostic information of MT Pump";
CM_ SG_ 818 TMS_DiagLTPump "Diagnostic information of? LT Pump";
CM_ SG_ 818 TMS_AHFOnReq "Enable AHF";
CM_ SG_ 818 TMS_AHFPwrReq "AHF Heating power request";
CM_ SG_ 818 TMS_AHFSt "AHF Heat DownShift State";
CM_ SG_ 818 TMS_AHFHeatingReq "AHF Heating Duty request";
CM_ SG_ 1152 HVAC_TargetWaterTempMaxFC "Maximum target water temperature required for Front cabins";
CM_ SG_ 1152 HVAC_TargetWaterTempMinFC "Minimum target water temperature required for Front cabins";
CM_ SG_ 392 VCU_1_CRC "E2E Profile 5 CRC";
CM_ SG_ 392 VCU_1_Counter "E2E Profile 5 Counter";
CM_ SG_ 392 VCU_DCU_TorqSet "target torque for drive motor";
CM_ SG_ 392 VCU_DCU_MinTorqDampgCtl "Minimum limit for damping torque that shall be applied(in Nm)";
CM_ SG_ 392 VCU_DCU_IdcMax "max current for drive torque";
CM_ SG_ 392 VCU_DCU_IdcMin "max current for regenerative torque";
CM_ SG_ 392 EMS_GasPedalActPstforMRRVD_E "EMS_GasPedalActPstforMRR Valid Data";
CM_ SG_ 392 VCU_DCU_TorqMin "max limit of negative torque for drive motor";
CM_ SG_ 392 VCU_DCU_MaxTorqGradient "Maximum change rate of the torque demand";
CM_ SG_ 392 VCU_DCU_TorqMax "max limit of positive torque for drive motor";
CM_ SG_ 392 VCU_DCU_MaxTorqDampgCtl "Maximum limit for damping torque that shall be applied (in Nm).";
CM_ SG_ 392 VCU_DCU_CoolantTemp "Estimated IDU inlet coolant temperature";
CM_ SG_ 392 VCU_DCU_SpdLmt "Speed limit for drive motor";
CM_ SG_ 392 EMS_GasPedalActPstforMRR_E "EMS_GasPedalActPstforMRR";
CM_ SG_ 392 VCU_DCU_SpdSet "target speed for drive motor, only with openclutch";
CM_ SG_ 392 VCU_DCU_SurgeDamperStReq "Desired state for damping control feature";
CM_ SG_ 392 VCU_CrntGearLvl "VCU current carry out gear level";
CM_ SG_ 392 VCU_DCU_SurgeDamperFactor "Dynamic factor used to convert vibrations due to speed into equivalent damping";
CM_ SG_ 392 VCU_HvilSt "HVIL status";
CM_ SG_ 392 VCU_DCU_ModeReq "requestable state/mode of drive motor";
CM_ SG_ 392 VCU_IPS_OBCModeReq "OBC mode request (0: no request, sleep indication allowed)";
CM_ SG_ 392 VCU_BrkPedPstVD_E "Current brake pedal position valid data";
CM_ SG_ 392 VCU_BMS_SepaHeatEn "enable or disable separate heat request from BMS";
CM_ SG_ 392 VCU_IPS_DCDCModeReq "requestable target mode for DCDC";
CM_ SG_ 392 VCU_IPS_OBCDsChDCCurrLim "max allowed (limit) discharging current on DC side of OBC";
CM_ SG_ 392 VCU_IPS_DCDCLvCurrLim "Limitation of DCDC LV output current. Current is positive, if energy flow is from IPS into the LV system.";
CM_ SG_ 392 VCU_IPS_DCDCVoltLvSet "requestable target output DC voltage at LV of DCDC";
CM_ SG_ 392 VCU_IPS_OBCChgCurrReq "Required AC charge current from IPS_OBC";
CM_ SG_ 392 VCU_IPS_OBCChgVoltReq "Required AC charge valtage from IPS_OBC";
CM_ SG_ 392 VCU_BrkPedPst_E "Current brake pedal position";
CM_ SG_ 824 VCU_2_CRC "E2E Profile 5 CRC";
CM_ SG_ 824 VCU_2_Counter "E2E Profile 5 Counter";
CM_ SG_ 824 VCU_DCU_ChgDisChgCapVoltReq "Cap Voltage(C2) Request of? Charge&? Discharge from VCU to DCU";
CM_ SG_ 824 VCU_PlgConnSt "Charge connector? connected Status";
CM_ SG_ 824 VCU_DCU_BoostChgTargCurr "Target Current of boost Charge from VCU to DCU";
CM_ SG_ 824 VCU_SwapHvBattModeStVD "VCU swap Hvbattery mode statue VD";
CM_ SG_ 824 VCU_SwapHvBattModeSt "VCU swap Hvbattery mode status";
CM_ SG_ 824 VCU_DCU_DisChgTargCurr "Target Current of DisCharge from VCU to DCU";
CM_ SG_ 824 VCU_AHF_TarPwr "VCU send target power for AHF";
CM_ SG_ 952 VCU_3_CRC "E2E Profile 5 CRC";
CM_ SG_ 952 VCU_3_Counter "E2E Profile 5 Counter";
CM_ SG_ 952 VCU_MotorLoopEstimatedFlow "Estimated flow of the motor loop";
CM_ SG_ 952 VCU_MotorLoopEstimatedFlowVD "whether the estimated flow of the motor loop is valid";
CM_ SG_ 952 VCU_EM3To2ValveEn "EM 3/2 way valve control state. (Disable = not pass the EM; Enable = pass the EM)";
CM_ SG_ 952 VCU_CtrlPwmDucycLT "Duty Cycle(Ducyc) to control LT Pump";
CM_ SG_ 952 VCU_DiagLTPump "Diagnostic information of? LT Pump";
CM_ SG_ 952 VCU_CtrlPwmDucycMT "Duty Cycle(Ducyc) to control MT Pump";
CM_ SG_ 952 VCU_DiagMTPump "Diagnostic information of MT Pump";
CM_ SG_ 930 VCU_8_CRC "E2E Profile 5 CRC";
CM_ SG_ 930 VCU_8_Counter "E2E Profile 5 Counter";
CM_ SG_ 930 VCU_BoostChgTargCurr "Target Current of boost Charge from VCU to DCU";
CM_ SG_ 930 VCU_DisChgTargCurr "Target Current of DisCharge from VCU to DCU";
CM_ SG_ 930 VCU_BoostChgMode "Boost Charge mode from VCU to BMC";
CM_ SG_ 930 VCU_K2RlyAdhDetn "K2 Relay adhesion detection request";
CM_ SG_ 930 VCU_CCUBCBPowerSup "VCU request CCU give BCB power supply";
CM_ SG_ 930 VCU_TargetPosReq_1 "target position for AGS1";
CM_ SG_ 930 VCU_DcChgVoltOutReq "Required DC charger output valtage";
CM_ SG_ 930 VCU_PreChgTargVolt "Target voltage of PreCharge from VCU to DCU";
CM_ SG_ 930 VCU_BoostChgTargVolt "Target voltage of boost Charge from VCU to DCU";
CM_ SG_ 930 VCU_AHFActivatePwr "AHF activated judgment condition";
CM_ SG_ 930 VCU_TMS_AHFDelayEn "AHF OFF or downshift should be delayed if enable this signal, othewise not";
CM_ SG_ 930 VCU_TMS_AHFShutImme "AHF immediate shutdown request";
CM_ SG_ 930 VCU_DCU_IdcMeasure "DCU dc current mesured value";
CM_ SG_ 930 VCU_TMS_AHFActivationSt "Indicate AHF activated or not";
CM_ SG_ 1279 DCU_Data1No "DCU Data 1 Number 1";
CM_ SG_ 1279 DCU_InvtPhaUTemp "Current temperature of inverter Phase U";
CM_ SG_ 1279 DCU_InvtPhaVTemp "Current temperature of inverter Phase V";
CM_ SG_ 1279 DCU_InvtPhaWTemp "Current temperature of inverter Phase W";
CM_ SG_ 1279 DCU_Stat1Temp "Current temperature of Stator 1";
CM_ SG_ 1279 DCU_Stat2Temp "Current temperature of Stator 2";
CM_ SG_ 1279 DCU_CtrlBoardTemp "Current temperature of Control Board";
CM_ SG_ 1279 DCU_DrvBoardTemp "Current temperature of Drive Board";
CM_ SG_ 1279 DCU_CapTemp "Current temperature of Capacitor";
BA_DEF_ BO_  "GenMsgCycleTimeFast" INT 0 0;
BA_DEF_ BO_  "GenMsgCycleTime" INT 0 0;
BA_DEF_ BO_  "GenMsgSendType" ENUM  "Cyclic","NotUsed","NotUsed","NotUsed","NotUsed","NotUsed","NotUsed","IfActive","NoMsgSendType","NotUsed";
BA_DEF_ BO_  "VFrameFormat" ENUM  "StandardCAN","ExtendedCAN","reserved","reserved","reserved","reserved","reserved","reserved","reserved","reserved","reserved","reserved","reserved","reserved","StandardCAN_FD","ExtendedCAN_FD";
BA_DEF_ SG_  "GenSigStartValue" INT 0 0;
BA_DEF_ SG_  "GenSigInactiveValue" INT 0 0;
BA_DEF_ SG_  "GenSigSendType" ENUM  "Cyclic","OnWrite","OnWriteWithRepetition","OnChange","OnChangeWithRepetition","IfActive","IfActiveWithRepetition","NoSigSendType","NotUsed","NotUsed","NotUsed","NotUsed","NotUsed";
BA_DEF_ SG_  "EventCommandSignal" ENUM  "No","Yes";
BA_DEF_ SG_  "GatewayedSignals" ENUM  "No","Yes";
BA_DEF_ SG_  "GenSigInvalidValue" HEX 0 0;
BA_DEF_ SG_  "Remark" STRING ;
BA_DEF_  "Baudrate" INT 0 1000000;
BA_DEF_  "BusType" STRING ;
BA_DEF_  "NmType" STRING ;
BA_DEF_  "Manufacturer" STRING ;
BA_DEF_ BU_  "NodeLayerModules" STRING ;
BA_DEF_  "NmAsrWaitBusSleepTime" INT 0 65535;
BA_DEF_  "NmAsrTimeoutTime" INT 1 65535;
BA_DEF_  "NmAsrRepeatMessageTime" INT 0 65535;
BA_DEF_ BU_  "NmAsrNodeIdentifier" HEX 0 255;
BA_DEF_  "NmAsrMessageCount" INT 1 256;
BA_DEF_ BU_  "NmAsrCanMsgReducedTime" INT 1 65535;
BA_DEF_  "NmAsrCanMsgCycleTime" INT 1 65535;
BA_DEF_  "NmAsrBaseAddress" HEX 0 2047;
BA_DEF_ SG_  "GenSigTimeoutValue" INT 0 65535;
BA_DEF_ BO_  "GenMsgILSupport" ENUM  "no","yes";
BA_DEF_  "DBName" STRING ;
BA_DEF_DEF_  "GenMsgCycleTimeFast" 0;
BA_DEF_DEF_  "GenMsgCycleTime" 0;
BA_DEF_DEF_  "GenMsgSendType" "Cyclic";
BA_DEF_DEF_  "VFrameFormat" "";
BA_DEF_DEF_  "GenSigStartValue" 0;
BA_DEF_DEF_  "GenSigInactiveValue" 0;
BA_DEF_DEF_  "GenSigSendType" "Cyclic";
BA_DEF_DEF_  "EventCommandSignal" "";
BA_DEF_DEF_  "GatewayedSignals" "";
BA_DEF_DEF_  "GenSigInvalidValue" 0;
BA_DEF_DEF_  "Remark" "";
BA_DEF_DEF_  "Baudrate" 500000;
BA_DEF_DEF_  "BusType" "";
BA_DEF_DEF_  "NmType" "";
BA_DEF_DEF_  "Manufacturer" "Vector";
BA_DEF_DEF_  "NodeLayerModules" " ";
BA_DEF_DEF_  "NmAsrWaitBusSleepTime" 1500;
BA_DEF_DEF_  "NmAsrTimeoutTime" 2000;
BA_DEF_DEF_  "NmAsrRepeatMessageTime" 3200;
BA_DEF_DEF_  "NmAsrNodeIdentifier" 50;
BA_DEF_DEF_  "NmAsrMessageCount" 128;
BA_DEF_DEF_  "NmAsrCanMsgReducedTime" 320;
BA_DEF_DEF_  "NmAsrCanMsgCycleTime" 640;
BA_DEF_DEF_  "NmAsrBaseAddress" 1280;
BA_DEF_DEF_  "GenSigTimeoutValue" 0;
BA_DEF_DEF_  "GenMsgILSupport" "no";
BA_DEF_DEF_  "DBName" "ECAN";
BA_ "Manufacturer" "GACRND";
BA_ "NmType" "NmAsr";
BA_ "BusType" "CAN FD";
BA_ "NmAsrWaitBusSleepTime" 2000;
BA_ "DBName" "NIDUCCU_CANFD2_V31_Debug1_202412";
BA_ "GenMsgILSupport" BO_ 356 1;
BA_ "GenMsgCycleTime" BO_ 356 10;
BA_ "VFrameFormat" BO_ 356 14;
BA_ "GenMsgILSupport" BO_ 1025 1;
BA_ "GenMsgCycleTime" BO_ 1025 100;
BA_ "VFrameFormat" BO_ 1025 14;
BA_ "GenMsgILSupport" BO_ 408 1;
BA_ "GenMsgCycleTime" BO_ 408 10;
BA_ "VFrameFormat" BO_ 408 14;
BA_ "GenMsgILSupport" BO_ 888 1;
BA_ "GenMsgCycleTime" BO_ 888 100;
BA_ "VFrameFormat" BO_ 888 14;
BA_ "GenMsgILSupport" BO_ 1095 1;
BA_ "GenMsgCycleTime" BO_ 1095 100;
BA_ "VFrameFormat" BO_ 1095 14;
BA_ "GenMsgILSupport" BO_ 1098 1;
BA_ "GenMsgCycleTime" BO_ 1098 100;
BA_ "VFrameFormat" BO_ 1098 14;
BA_ "GenMsgILSupport" BO_ 812 1;
BA_ "GenMsgCycleTime" BO_ 812 100;
BA_ "VFrameFormat" BO_ 812 14;
BA_ "VFrameFormat" BO_ 1377 0;
BA_ "GenMsgILSupport" BO_ 1377 1;
BA_ "GenMsgCycleTime" BO_ 1377 200;
BA_ "GenMsgILSupport" BO_ 616 1;
BA_ "GenMsgCycleTime" BO_ 616 20;
BA_ "VFrameFormat" BO_ 616 14;
BA_ "GenMsgILSupport" BO_ 816 1;
BA_ "GenMsgCycleTime" BO_ 816 100;
BA_ "VFrameFormat" BO_ 816 14;
BA_ "GenMsgILSupport" BO_ 615 1;
BA_ "GenMsgCycleTime" BO_ 615 20;
BA_ "VFrameFormat" BO_ 615 14;
BA_ "GenMsgILSupport" BO_ 352 1;
BA_ "GenMsgCycleTime" BO_ 352 10;
BA_ "VFrameFormat" BO_ 352 14;
BA_ "GenMsgILSupport" BO_ 363 1;
BA_ "GenMsgCycleTime" BO_ 363 100;
BA_ "VFrameFormat" BO_ 363 14;
BA_ "GenMsgILSupport" BO_ 351 1;
BA_ "GenMsgCycleTime" BO_ 351 200;
BA_ "VFrameFormat" BO_ 351 14;
BA_ "VFrameFormat" BO_ 1359 0;
BA_ "GenMsgILSupport" BO_ 1359 1;
BA_ "GenMsgCycleTime" BO_ 1359 200;
BA_ "GenMsgILSupport" BO_ 290 1;
BA_ "GenMsgCycleTime" BO_ 290 500;
BA_ "VFrameFormat" BO_ 290 14;
BA_ "GenMsgILSupport" BO_ 909 1;
BA_ "GenMsgCycleTime" BO_ 909 100;
BA_ "VFrameFormat" BO_ 909 14;
BA_ "GenMsgILSupport" BO_ 902 1;
BA_ "GenMsgCycleTime" BO_ 902 100;
BA_ "VFrameFormat" BO_ 902 14;
BA_ "VFrameFormat" BO_ 1291 0;
BA_ "GenMsgILSupport" BO_ 1291 1;
BA_ "GenMsgCycleTime" BO_ 1291 200;
BA_ "VFrameFormat" BO_ 1308 0;
BA_ "GenMsgILSupport" BO_ 1308 1;
BA_ "GenMsgCycleTime" BO_ 1308 200;
BA_ "GenMsgILSupport" BO_ 368 1;
BA_ "GenMsgCycleTime" BO_ 368 10;
BA_ "VFrameFormat" BO_ 368 14;
BA_ "GenMsgILSupport" BO_ 864 1;
BA_ "GenMsgCycleTime" BO_ 864 100;
BA_ "VFrameFormat" BO_ 864 14;
BA_ "GenMsgILSupport" BO_ 875 1;
BA_ "GenMsgCycleTime" BO_ 875 100;
BA_ "VFrameFormat" BO_ 875 14;
BA_ "GenMsgILSupport" BO_ 2683306021 1;
BA_ "GenMsgCycleTime" BO_ 2683306021 100;
BA_ "VFrameFormat" BO_ 2683306021 15;
BA_ "GenMsgILSupport" BO_ 2683306010 1;
BA_ "GenMsgCycleTime" BO_ 2683306010 100;
BA_ "VFrameFormat" BO_ 2683306010 15;
BA_ "GenMsgILSupport" BO_ 2683305995 1;
BA_ "GenMsgCycleTime" BO_ 2683305995 10;
BA_ "VFrameFormat" BO_ 2683305995 15;
BA_ "GenMsgILSupport" BO_ 2683305992 1;
BA_ "GenMsgCycleTime" BO_ 2683305992 10;
BA_ "VFrameFormat" BO_ 2683305992 15;
BA_ "GenMsgILSupport" BO_ 2683305998 1;
BA_ "GenMsgCycleTime" BO_ 2683305998 10;
BA_ "VFrameFormat" BO_ 2683305998 15;
BA_ "GenMsgILSupport" BO_ 2683305999 1;
BA_ "GenMsgCycleTime" BO_ 2683305999 10;
BA_ "VFrameFormat" BO_ 2683305999 15;
BA_ "GenMsgILSupport" BO_ 1178 1;
BA_ "VFrameFormat" BO_ 1178 14;
BA_ "GenMsgILSupport" BO_ 384 1;
BA_ "GenMsgCycleTime" BO_ 384 100;
BA_ "VFrameFormat" BO_ 384 14;
BA_ "GenMsgILSupport" BO_ 2683306160 1;
BA_ "GenMsgCycleTime" BO_ 2683306160 100;
BA_ "VFrameFormat" BO_ 2683306160 15;
BA_ "GenMsgILSupport" BO_ 599 1;
BA_ "GenMsgCycleTime" BO_ 599 20;
BA_ "VFrameFormat" BO_ 599 14;
BA_ "VFrameFormat" BO_ 1533 0;
BA_ "GenMsgILSupport" BO_ 1533 1;
BA_ "GenMsgCycleTime" BO_ 1533 200;
BA_ "GenMsgILSupport" BO_ 2015 1;
BA_ "VFrameFormat" BO_ 2015 14;
BA_ "GenMsgILSupport" BO_ 704 1;
BA_ "GenMsgCycleTime" BO_ 704 20;
BA_ "VFrameFormat" BO_ 704 14;
BA_ "GenMsgILSupport" BO_ 872 1;
BA_ "GenMsgCycleTime" BO_ 872 100;
BA_ "VFrameFormat" BO_ 872 14;
BA_ "GenMsgILSupport" BO_ 2683306000 1;
BA_ "GenMsgCycleTime" BO_ 2683306000 200;
BA_ "VFrameFormat" BO_ 2683306000 15;
BA_ "GenMsgILSupport" BO_ 2683306012 1;
BA_ "GenMsgCycleTime" BO_ 2683306012 200;
BA_ "VFrameFormat" BO_ 2683306012 15;
BA_ "GenMsgILSupport" BO_ 880 1;
BA_ "GenMsgCycleTime" BO_ 880 200;
BA_ "VFrameFormat" BO_ 880 14;
BA_ "VFrameFormat" BO_ 1410 0;
BA_ "GenMsgILSupport" BO_ 1410 1;
BA_ "GenMsgCycleTime" BO_ 1410 200;
BA_ "GenMsgILSupport" BO_ 1790 1;
BA_ "VFrameFormat" BO_ 1790 14;
BA_ "VFrameFormat" BO_ 1406 0;
BA_ "GenMsgILSupport" BO_ 1406 1;
BA_ "GenMsgCycleTime" BO_ 1406 200;
BA_ "GenMsgILSupport" BO_ 1662 1;
BA_ "VFrameFormat" BO_ 1662 14;
BA_ "GenMsgILSupport" BO_ 818 1;
BA_ "GenMsgCycleTime" BO_ 818 100;
BA_ "VFrameFormat" BO_ 818 14;
BA_ "GenMsgILSupport" BO_ 1152 1;
BA_ "GenMsgCycleTime" BO_ 1152 1000;
BA_ "VFrameFormat" BO_ 1152 14;
BA_ "GenMsgILSupport" BO_ 392 1;
BA_ "GenMsgCycleTime" BO_ 392 10;
BA_ "VFrameFormat" BO_ 392 14;
BA_ "GenMsgILSupport" BO_ 824 1;
BA_ "GenMsgCycleTime" BO_ 824 100;
BA_ "VFrameFormat" BO_ 824 14;
BA_ "GenMsgILSupport" BO_ 952 1;
BA_ "GenMsgCycleTime" BO_ 952 200;
BA_ "VFrameFormat" BO_ 952 14;
BA_ "GenMsgILSupport" BO_ 930 1;
BA_ "GenMsgCycleTime" BO_ 930 100;
BA_ "VFrameFormat" BO_ 930 14;
BA_ "VFrameFormat" BO_ 2634022912 1;
BA_ "GenMsgILSupport" BO_ 2634022912 1;
BA_ "VFrameFormat" BO_ 2634022913 1;
BA_ "GenMsgILSupport" BO_ 2634022913 1;
BA_ "GenMsgCycleTime" BO_ 1279 1000;
BA_ "GenMsgCycleTimeFast" BO_ 1279 40;
BA_ "GenMsgSendType" BO_ 1279 4;
BA_ "VFrameFormat" BO_ 1279 14;
BA_ "GenSigStartValue" SG_ 408 BMC_BattCurr 10000;
BA_ "GenSigStartValue" SG_ 812 BMS_DCCurrRx 10000;
BA_ "GenSigStartValue" SG_ 812 BMS_CoolantTargTemp 80;
BA_ "GenSigStartValue" SG_ 1377 BMC_NMNodeAddress 97;
BA_ "GenSigStartValue" SG_ 616 UMM_UsageModeSt 7;
BA_ "GenSigStartValue" SG_ 616 VMM_LastVehModeSt 15;
BA_ "GenSigStartValue" SG_ 616 VMM_VehModeSt 15;
BA_ "GenSigStartValue" SG_ 616 Time_Month 1;
BA_ "GenSigStartValue" SG_ 616 Time_Hour 1;
BA_ "GenSigStartValue" SG_ 616 Time_Day 1;
BA_ "GenSigStartValue" SG_ 616 Time_Min 1;
BA_ "GenSigStartValue" SG_ 616 Time_Sec 1;
BA_ "GenSigStartValue" SG_ 816 HVAC_CorrectedExterTemp 120;
BA_ "GenSigStartValue" SG_ 816 HVAC_PTCOnReq 3;
BA_ "GenSigStartValue" SG_ 615 IPB_InputRodStroke 100;
BA_ "GenSigStartValue" SG_ 615 IPB_PlungerPressure 17;
BA_ "GenSigStartValue" SG_ 352 BCS_VDCFaultSt 1;
BA_ "GenSigStartValue" SG_ 352 BCS_TCSFaultSt 1;
BA_ "GenSigStartValue" SG_ 352 BCS_ABSFaultSt 1;
BA_ "GenSigStartValue" SG_ 352 BCS_EBDFaultSt 1;
BA_ "GenSigStartValue" SG_ 352 BCS_DMCTarSpdFA 65534;
BA_ "GenSigStartValue" SG_ 352 BCS_DMCTarSpdRA 65534;
BA_ "GenSigStartValue" SG_ 363 EPS_SteeringAngle 7800;
BA_ "GenSigStartValue" SG_ 1359 CCU_NMNodeAddress 79;
BA_ "GenSigStartValue" SG_ 290 IPDS_RearEOPPowerSup 3;
BA_ "GenSigStartValue" SG_ 290 IPDS_KL15T1PowerSup 3;
BA_ "GenSigStartValue" SG_ 290 IPDS_BCBPowerSup 3;
BA_ "GenSigStartValue" SG_ 290 IPDS_FrontEOPPowerSup 3;
BA_ "GenSigStartValue" SG_ 1291 DCDC_NMNodeAddress 11;
BA_ "GenSigStartValue" SG_ 1308 DCDC2_NMNodeAddress 28;
BA_ "GenSigStartValue" SG_ 368 DCU_RotSpdAct 32767;
BA_ "GenSigStartValue" SG_ 368 DCU_IdcAct 1023;
BA_ "GenSigStartValue" SG_ 368 DCU_CCUEOPPowerSup 1;
BA_ "GenSigStartValue" SG_ 368 DCU_ModeSt 1;
BA_ "GenSigStartValue" SG_ 368 DCU_TorqMin 1023;
BA_ "GenSigStartValue" SG_ 368 DCU_SelfTorqMin 1023;
BA_ "GenSigStartValue" SG_ 368 DCU_DMCInternalInit 1;
BA_ "GenSigStartValue" SG_ 368 DCU_DMCOperationStToBCS 2;
BA_ "GenSigStartValue" SG_ 368 DCU_DMCInternalTorqSet 1023;
BA_ "GenSigStartValue" SG_ 368 DCU_DMCoutputTorqToBCS 50000;
BA_ "GenSigStartValue" SG_ 368 DCU_TorqAct 4095;
BA_ "GenSigStartValue" SG_ 368 DCU_FusaTorqAct 4095;
BA_ "GenSigStartValue" SG_ 368 DCU_FusaRotSpdAct 32767;
BA_ "GenSigStartValue" SG_ 368 DCU_TrefFinal 2000;
BA_ "GenSigStartValue" SG_ 864 DCU_InvtTemp 40;
BA_ "GenSigStartValue" SG_ 864 DCU_RotTemp 40;
BA_ "GenSigStartValue" SG_ 864 DCU_StatTemp 40;
BA_ "GenSigStartValue" SG_ 864 DCU_TempCoolant 40;
BA_ "GenSigStartValue" SG_ 864 DCU_TEL_InvtTemp 40;
BA_ "GenSigStartValue" SG_ 864 DCU_TEL_StatTemp 40;
BA_ "GenSigStartValue" SG_ 875 DCU_PTCInterTemp 511;
BA_ "GenSigStartValue" SG_ 875 DCU_PTCMOSTemp 255;
BA_ "GenSigStartValue" SG_ 875 DCU_AHFPwrMax 8191;
BA_ "GenSigStartValue" SG_ 875 DCU_AHFPwrMin 8191;
BA_ "GenSigStartValue" SG_ 875 DCU_AHFCurrentReq 1023;
BA_ "GenSigStartValue" SG_ 875 DCU_AHFCurrentAct 1023;
BA_ "GenSigStartValue" SG_ 875 DCU_MotorTempEst 255;
BA_ "GenSigStartValue" SG_ 2683306021 DCU_EOP_OilTempAct 40;
BA_ "GenSigStartValue" SG_ 2683306010 DCU_IgbtNtcTempMax 40;
BA_ "GenSigStartValue" SG_ 2683306010 DCU_CtlBoardTemp_Debug 40;
BA_ "GenSigStartValue" SG_ 2683306010 DCU_CapTemp_Debug 40;
BA_ "GenSigStartValue" SG_ 2683305995 DCU_TempCoolant_1 40;
BA_ "GenSigStartValue" SG_ 2683305995 DCU_FusaTorqAct_Debug 4095;
BA_ "GenSigStartValue" SG_ 2683305995 DCU_FusaRotSpdAct_Debug 32767;
BA_ "GatewayedSignals" SG_ 2683305995 DCU_DataFaultHandle 0;
BA_ "EventCommandSignal" SG_ 2683305995 DCU_DataFaultHandle 0;
BA_ "GenSigStartValue" SG_ 2683305995 DCU_TrqAntiJerk 127;
BA_ "GenSigStartValue" SG_ 2683305995 DCU_TrefFinal_Debug 1000;
BA_ "GenSigStartValue" SG_ 2683305995 DCU_Iq_Debug 15000;
BA_ "GenSigStartValue" SG_ 2683305995 DCU_Id_Debug 15000;
BA_ "GenSigStartValue" SG_ 2683305995 DCU_TjMax 40;
BA_ "GenSigStartValue" SG_ 2683305995 DCU_iCurqRef_Debug 15000;
BA_ "GenSigStartValue" SG_ 2683305995 DCU_iCurdRef_Debug 15000;
BA_ "GenSigStartValue" SG_ 2683305995 DCU_uVoltqRef 15000;
BA_ "GenSigStartValue" SG_ 2683305995 DCU_uVoltdRef 15000;
BA_ "GenSigStartValue" SG_ 2683305992 DCU_DMC_BCSDbgSig1 30000;
BA_ "GenSigStartValue" SG_ 2683305992 DCU_DMC_BCSDbgSig2 30000;
BA_ "GenSigStartValue" SG_ 2683305992 DCU_DMC_BCSDbgSig5 32767;
BA_ "GenSigStartValue" SG_ 2683305992 DCU_DMC_BCSDbgSig6 32767;
BA_ "GenSigStartValue" SG_ 2683305992 DCU_DMC_BCSDbgSig10 30000;
BA_ "GenSigStartValue" SG_ 2683305992 DCU_DMC_BCSDbgSig11 30000;
BA_ "GenSigStartValue" SG_ 2683305992 DCU_DMC_BCSDbgSig9 1023;
BA_ "GenSigStartValue" SG_ 2683305992 DCU_DMC_BCSDbgSig7 1023;
BA_ "GenSigStartValue" SG_ 2683305999 DCU_Debug_Id 15000;
BA_ "GenSigStartValue" SG_ 2683305999 DCU_Debug_Iq 15000;
BA_ "GenSigStartValue" SG_ 2683305999 DCU_Debug_TorqEstByTable 15000;
BA_ "GenSigStartValue" SG_ 2683305999 DCU_Debug_TorqEstByPower 15000;
BA_ "GenSigStartValue" SG_ 2683305999 DCU_Debug_IdcEst 15000;
BA_ "GenSigStartValue" SG_ 1533 EVCC_NMNodeAddress 125;
BA_ "GenSigStartValue" SG_ 704 IPS_OBCHvDcCurrAct 1024;
BA_ "GenSigStartValue" SG_ 872 IPS_OBCAcIso_Res 63;
BA_ "GenSigStartValue" SG_ 2683306012 IPS_tPfcTemp 500;
BA_ "GenSigStartValue" SG_ 2683306012 IPS_DcdcRadTemp 500;
BA_ "GenSigStartValue" SG_ 1410 ITS_NMNodeAddress 130;
BA_ "GenSigStartValue" SG_ 1406 NIDU_NMNodeAddress 98;
BA_ "GenSigStartValue" SG_ 818 TMS_AHFOnReq 1;
BA_ "GenSigStartValue" SG_ 392 VCU_DCU_TorqSet 4095;
BA_ "GenSigStartValue" SG_ 392 VCU_DCU_MinTorqDampgCtl 255;
BA_ "GenSigStartValue" SG_ 392 VCU_DCU_IdcMax 1022;
BA_ "GenSigStartValue" SG_ 392 VCU_DCU_IdcMin 1;
BA_ "GenSigStartValue" SG_ 392 VCU_DCU_TorqMin 1;
BA_ "GenSigStartValue" SG_ 392 VCU_DCU_MaxTorqGradient 16382;
BA_ "GenSigStartValue" SG_ 392 VCU_DCU_TorqMax 1022;
BA_ "GenSigStartValue" SG_ 392 VCU_DCU_CoolantTemp 68;
BA_ "GenSigStartValue" SG_ 392 VCU_DCU_SpdLmt 65534;
BA_ "GenSigStartValue" SG_ 392 VCU_DCU_SpdSet 65534;
BA_ "GenSigStartValue" SG_ 392 VCU_DCU_SurgeDamperFactor 62;
BA_ "GenSigStartValue" SG_ 392 VCU_DCU_ModeReq 2;
BA_ "GenSigStartValue" SG_ 392 VCU_IPS_DCDCModeReq 1;
BA_ "GenSigStartValue" SG_ 392 VCU_IPS_DCDCVoltLvSet 55;
BA_ "EventCommandSignal" SG_ 1279 DCU_Data1No 0;
BA_ "GatewayedSignals" SG_ 1279 DCU_Data1No 0;
BA_ "GenSigSendType" SG_ 1279 DCU_Data1No 1;
BA_ "GenSigStartValue" SG_ 1279 DCU_Data1No 1;
BA_ "EventCommandSignal" SG_ 1279 DCU_Hwversion 0;
BA_ "GatewayedSignals" SG_ 1279 DCU_Hwversion 0;
BA_ "GenSigSendType" SG_ 1279 DCU_Hwversion 1;
BA_ "EventCommandSignal" SG_ 1279 DCU_Swversion 0;
BA_ "GatewayedSignals" SG_ 1279 DCU_Swversion 0;
BA_ "GenSigSendType" SG_ 1279 DCU_Swversion 1;
BA_ "EventCommandSignal" SG_ 1279 DCU_SwVerExt 0;
BA_ "GatewayedSignals" SG_ 1279 DCU_SwVerExt 0;
BA_ "GenSigSendType" SG_ 1279 DCU_SwVerExt 1;
BA_ "EventCommandSignal" SG_ 1279 DCU_OffsetAngle 0;
BA_ "GatewayedSignals" SG_ 1279 DCU_OffsetAngle 0;
BA_ "GenSigSendType" SG_ 1279 DCU_OffsetAngle 1;
BA_ "EventCommandSignal" SG_ 1279 DCU_BootSV 0;
BA_ "GatewayedSignals" SG_ 1279 DCU_BootSV 0;
BA_ "GenSigSendType" SG_ 1279 DCU_BootSV 1;
BA_ "EventCommandSignal" SG_ 1279 DCU_BSWVersion 0;
BA_ "GatewayedSignals" SG_ 1279 DCU_BSWVersion 0;
BA_ "GenSigSendType" SG_ 1279 DCU_BSWVersion 1;
BA_ "EventCommandSignal" SG_ 1279 DCU_HWConfig 0;
BA_ "GatewayedSignals" SG_ 1279 DCU_HWConfig 0;
BA_ "GenSigSendType" SG_ 1279 DCU_HWConfig 1;
BA_ "EventCommandSignal" SG_ 1279 DCU_SWConfig 0;
BA_ "GatewayedSignals" SG_ 1279 DCU_SWConfig 0;
BA_ "GenSigSendType" SG_ 1279 DCU_SWConfig 1;
BA_ "EventCommandSignal" SG_ 1279 DCU_MCAConfig 0;
BA_ "GatewayedSignals" SG_ 1279 DCU_MCAConfig 0;
BA_ "GenSigSendType" SG_ 1279 DCU_MCAConfig 1;
BA_ "EventCommandSignal" SG_ 1279 DCU_FHConfig 0;
BA_ "GatewayedSignals" SG_ 1279 DCU_FHConfig 0;
BA_ "GenSigSendType" SG_ 1279 DCU_FHConfig 1;
BA_ "EventCommandSignal" SG_ 1279 DCU_InvtPhaUTemp 0;
BA_ "GatewayedSignals" SG_ 1279 DCU_InvtPhaUTemp 0;
BA_ "GenSigInvalidValue" SG_ 1279 DCU_InvtPhaUTemp 255;
BA_ "GenSigSendType" SG_ 1279 DCU_InvtPhaUTemp 1;
BA_ "EventCommandSignal" SG_ 1279 DCU_InvtPhaVTemp 0;
BA_ "GatewayedSignals" SG_ 1279 DCU_InvtPhaVTemp 0;
BA_ "GenSigInvalidValue" SG_ 1279 DCU_InvtPhaVTemp 255;
BA_ "GenSigSendType" SG_ 1279 DCU_InvtPhaVTemp 1;
BA_ "EventCommandSignal" SG_ 1279 DCU_InvtPhaWTemp 0;
BA_ "GatewayedSignals" SG_ 1279 DCU_InvtPhaWTemp 0;
BA_ "GenSigInvalidValue" SG_ 1279 DCU_InvtPhaWTemp 255;
BA_ "GenSigSendType" SG_ 1279 DCU_InvtPhaWTemp 1;
BA_ "EventCommandSignal" SG_ 1279 DCU_Stat1Temp 0;
BA_ "GatewayedSignals" SG_ 1279 DCU_Stat1Temp 0;
BA_ "GenSigInvalidValue" SG_ 1279 DCU_Stat1Temp 255;
BA_ "GenSigSendType" SG_ 1279 DCU_Stat1Temp 1;
BA_ "EventCommandSignal" SG_ 1279 DCU_Stat2Temp 0;
BA_ "GatewayedSignals" SG_ 1279 DCU_Stat2Temp 0;
BA_ "GenSigInvalidValue" SG_ 1279 DCU_Stat2Temp 255;
BA_ "GenSigSendType" SG_ 1279 DCU_Stat2Temp 1;
BA_ "EventCommandSignal" SG_ 1279 DCU_CtrlBoardTemp 0;
BA_ "GatewayedSignals" SG_ 1279 DCU_CtrlBoardTemp 0;
BA_ "GenSigInvalidValue" SG_ 1279 DCU_CtrlBoardTemp 255;
BA_ "GenSigSendType" SG_ 1279 DCU_CtrlBoardTemp 1;
BA_ "EventCommandSignal" SG_ 1279 DCU_DrvBoardTemp 0;
BA_ "GatewayedSignals" SG_ 1279 DCU_DrvBoardTemp 0;
BA_ "GenSigInvalidValue" SG_ 1279 DCU_DrvBoardTemp 255;
BA_ "GenSigSendType" SG_ 1279 DCU_DrvBoardTemp 1;
BA_ "EventCommandSignal" SG_ 1279 DCU_CapTemp 0;
BA_ "GatewayedSignals" SG_ 1279 DCU_CapTemp 0;
BA_ "GenSigInvalidValue" SG_ 1279 DCU_CapTemp 255;
BA_ "GenSigSendType" SG_ 1279 DCU_CapTemp 1;
BA_ "EventCommandSignal" SG_ 1279 DCU_FaultData_RC 0;
BA_ "GatewayedSignals" SG_ 1279 DCU_FaultData_RC 0;
BA_ "GenSigSendType" SG_ 1279 DCU_FaultData_RC 1;
BA_ "EventCommandSignal" SG_ 1279 DCU_stMode 0;
BA_ "GatewayedSignals" SG_ 1279 DCU_stMode 0;
BA_ "GenSigSendType" SG_ 1279 DCU_stMode 1;
BA_ "GenSigStartValue" SG_ 1279 DCU_stMode 1;
BA_ "EventCommandSignal" SG_ 1279 DCU_stPWMEna 0;
BA_ "GatewayedSignals" SG_ 1279 DCU_stPWMEna 0;
BA_ "GenSigSendType" SG_ 1279 DCU_stPWMEna 1;
BA_ "EventCommandSignal" SG_ 1279 DCU_stHandleOff 0;
BA_ "GatewayedSignals" SG_ 1279 DCU_stHandleOff 0;
BA_ "GenSigSendType" SG_ 1279 DCU_stHandleOff 1;
BA_ "EventCommandSignal" SG_ 1279 DCU_FailCode 0;
BA_ "GatewayedSignals" SG_ 1279 DCU_FailCode 0;
BA_ "GenSigSendType" SG_ 1279 DCU_FailCode 1;
BA_ "EventCommandSignal" SG_ 1279 DCU_stASCProt 0;
BA_ "GatewayedSignals" SG_ 1279 DCU_stASCProt 0;
BA_ "GenSigSendType" SG_ 1279 DCU_stASCProt 1;
BA_ "EventCommandSignal" SG_ 1279 DCU_agRotorPosn 0;
BA_ "GatewayedSignals" SG_ 1279 DCU_agRotorPosn 0;
BA_ "GenSigSendType" SG_ 1279 DCU_agRotorPosn 1;
BA_ "EventCommandSignal" SG_ 1279 DCU_iCurdFinalRef 0;
BA_ "GatewayedSignals" SG_ 1279 DCU_iCurdFinalRef 0;
BA_ "GenSigSendType" SG_ 1279 DCU_iCurdFinalRef 1;
BA_ "EventCommandSignal" SG_ 1279 DCU_iCurqFinalRef 0;
BA_ "GatewayedSignals" SG_ 1279 DCU_iCurqFinalRef 0;
BA_ "GenSigSendType" SG_ 1279 DCU_iCurqFinalRef 1;
BA_ "EventCommandSignal" SG_ 1279 DCU_iCurdFb 0;
BA_ "GatewayedSignals" SG_ 1279 DCU_iCurdFb 0;
BA_ "GenSigSendType" SG_ 1279 DCU_iCurdFb 1;
BA_ "EventCommandSignal" SG_ 1279 DCU_iCurqFb 0;
BA_ "GatewayedSignals" SG_ 1279 DCU_iCurqFb 0;
BA_ "GenSigSendType" SG_ 1279 DCU_iCurqFb 1;
BA_ "EventCommandSignal" SG_ 1279 DCU_iPhaCurU 0;
BA_ "GatewayedSignals" SG_ 1279 DCU_iPhaCurU 0;
BA_ "GenSigSendType" SG_ 1279 DCU_iPhaCurU 1;
BA_ "EventCommandSignal" SG_ 1279 DCU_iPhaCurV 0;
BA_ "GatewayedSignals" SG_ 1279 DCU_iPhaCurV 0;
BA_ "GenSigSendType" SG_ 1279 DCU_iPhaCurV 1;
BA_ "EventCommandSignal" SG_ 1279 DCU_iPhaCurW 0;
BA_ "GatewayedSignals" SG_ 1279 DCU_iPhaCurW 0;
BA_ "GenSigSendType" SG_ 1279 DCU_iPhaCurW 1;
BA_ "EventCommandSignal" SG_ 1279 DCU_uVoltdFinalRef 0;
BA_ "GatewayedSignals" SG_ 1279 DCU_uVoltdFinalRef 0;
BA_ "GenSigSendType" SG_ 1279 DCU_uVoltdFinalRef 1;
BA_ "EventCommandSignal" SG_ 1279 DCU_uVoltqFinalRef 0;
BA_ "GatewayedSignals" SG_ 1279 DCU_uVoltqFinalRef 0;
BA_ "GenSigSendType" SG_ 1279 DCU_uVoltqFinalRef 1;
BA_ "EventCommandSignal" SG_ 1279 DCU_iDcCur 0;
BA_ "GatewayedSignals" SG_ 1279 DCU_iDcCur 0;
BA_ "GenSigSendType" SG_ 1279 DCU_iDcCur 1;
BA_ "EventCommandSignal" SG_ 1279 DCU_OperatingCycle 0;
BA_ "GatewayedSignals" SG_ 1279 DCU_OperatingCycle 0;
BA_ "GenSigSendType" SG_ 1279 DCU_OperatingCycle 1;
BA_ "EventCommandSignal" SG_ 1279 DCU_RelativeTime 0;
BA_ "GatewayedSignals" SG_ 1279 DCU_RelativeTime 0;
BA_ "GenSigSendType" SG_ 1279 DCU_RelativeTime 1;
BA_ "EventCommandSignal" SG_ 1279 DCU_stFaultFlag100us 0;
BA_ "GatewayedSignals" SG_ 1279 DCU_stFaultFlag100us 0;
BA_ "GenSigSendType" SG_ 1279 DCU_stFaultFlag100us 1;
BA_ "EventCommandSignal" SG_ 1279 DCU_PWMFreq 0;
BA_ "GatewayedSignals" SG_ 1279 DCU_PWMFreq 0;
BA_ "GenSigSendType" SG_ 1279 DCU_PWMFreq 1;
BA_ "GenSigStartValue" SG_ 1279 DCU_PWMFreq 10000;
BA_ "EventCommandSignal" SG_ 1279 DCU_uDcVolt 0;
BA_ "GatewayedSignals" SG_ 1279 DCU_uDcVolt 0;
BA_ "GenSigSendType" SG_ 1279 DCU_uDcVolt 1;
BA_ "EventCommandSignal" SG_ 1279 DCU_uLowVolt 0;
BA_ "GatewayedSignals" SG_ 1279 DCU_uLowVolt 0;
BA_ "GenSigSendType" SG_ 1279 DCU_uLowVolt 1;
BA_ "EventCommandSignal" SG_ 1279 DCU_ResFaultFlag 0;
BA_ "GatewayedSignals" SG_ 1279 DCU_ResFaultFlag 0;
BA_ "GenSigSendType" SG_ 1279 DCU_ResFaultFlag 1;
BA_ "EventCommandSignal" SG_ 1279 DCU_stTsc 0;
BA_ "GatewayedSignals" SG_ 1279 DCU_stTsc 0;
BA_ "GenSigSendType" SG_ 1279 DCU_stTsc 1;
BA_ "EventCommandSignal" SG_ 1279 DCU_stIGBTFault 0;
BA_ "GatewayedSignals" SG_ 1279 DCU_stIGBTFault 0;
BA_ "GenSigSendType" SG_ 1279 DCU_stIGBTFault 1;
BA_ "EventCommandSignal" SG_ 1279 DCU_Month 0;
BA_ "GatewayedSignals" SG_ 1279 DCU_Month 0;
BA_ "GenSigSendType" SG_ 1279 DCU_Month 1;
BA_ "GenSigStartValue" SG_ 1279 DCU_Month 1;
BA_ "EventCommandSignal" SG_ 1279 DCU_Year 0;
BA_ "GatewayedSignals" SG_ 1279 DCU_Year 0;
BA_ "GenSigSendType" SG_ 1279 DCU_Year 1;
BA_ "GenSigStartValue" SG_ 1279 DCU_Year 15;
BA_ "EventCommandSignal" SG_ 1279 DCU_Hour 0;
BA_ "GatewayedSignals" SG_ 1279 DCU_Hour 0;
BA_ "GenSigSendType" SG_ 1279 DCU_Hour 1;
BA_ "EventCommandSignal" SG_ 1279 DCU_Day 0;
BA_ "GatewayedSignals" SG_ 1279 DCU_Day 0;
BA_ "GenSigSendType" SG_ 1279 DCU_Day 1;
BA_ "GenSigStartValue" SG_ 1279 DCU_Day 1;
BA_ "EventCommandSignal" SG_ 1279 DCU_Minute 0;
BA_ "GatewayedSignals" SG_ 1279 DCU_Minute 0;
BA_ "GenSigSendType" SG_ 1279 DCU_Minute 1;
BA_ "EventCommandSignal" SG_ 1279 DCU_Second 0;
BA_ "GatewayedSignals" SG_ 1279 DCU_Second 0;
BA_ "GenSigSendType" SG_ 1279 DCU_Second 1;
BA_ "EventCommandSignal" SG_ 1279 DCU_stSBCFault 0;
BA_ "GatewayedSignals" SG_ 1279 DCU_stSBCFault 0;
BA_ "EventCommandSignal" SG_ 1279 DCU_stBigDataTrigger 0;
BA_ "GatewayedSignals" SG_ 1279 DCU_stBigDataTrigger 0;
BA_ "EventCommandSignal" SG_ 1279 DCU_FaultData_4Bit_3 0;
BA_ "GatewayedSignals" SG_ 1279 DCU_FaultData_4Bit_3 0;
BA_ "EventCommandSignal" SG_ 1279 DCU_FaultData_4Bit_2 0;
BA_ "GatewayedSignals" SG_ 1279 DCU_FaultData_4Bit_2 0;
BA_ "GatewayedSignals" SG_ 1279 DCU_FaultData_8Bit_3 0;
BA_ "EventCommandSignal" SG_ 1279 DCU_FaultData_8Bit_3 0;
BA_ "GatewayedSignals" SG_ 1279 DCU_FaultData_8Bit_4 0;
BA_ "EventCommandSignal" SG_ 1279 DCU_FaultData_8Bit_4 0;
BA_ "GatewayedSignals" SG_ 1279 DCU_FaultData_12Bit_2 0;
BA_ "EventCommandSignal" SG_ 1279 DCU_FaultData_12Bit_2 0;
BA_ "GatewayedSignals" SG_ 1279 DCU_FaultData_12Bit_3 0;
BA_ "EventCommandSignal" SG_ 1279 DCU_FaultData_12Bit_3 0;
BA_ "GatewayedSignals" SG_ 1279 DCU_FaultData_16Bit_2 0;
BA_ "EventCommandSignal" SG_ 1279 DCU_FaultData_16Bit_2 0;
BA_ "GatewayedSignals" SG_ 1279 DCU_FaultData_20Bit_1 0;
BA_ "EventCommandSignal" SG_ 1279 DCU_FaultData_20Bit_1 0;
BA_ "GatewayedSignals" SG_ 1279 DCU_FaultData_1Bit_1 0;
BA_ "EventCommandSignal" SG_ 1279 DCU_FaultData_1Bit_1 0;
BA_ "GatewayedSignals" SG_ 1279 DCU_FaultData_1Bit_2 0;
BA_ "EventCommandSignal" SG_ 1279 DCU_FaultData_1Bit_2 0;
BA_ "GatewayedSignals" SG_ 1279 DCU_FaultData_1Bit_4 0;
BA_ "EventCommandSignal" SG_ 1279 DCU_FaultData_1Bit_4 0;
BA_ "GatewayedSignals" SG_ 1279 DCU_FaultData_4Bit_1 0;
BA_ "EventCommandSignal" SG_ 1279 DCU_FaultData_4Bit_1 0;
BA_ "GatewayedSignals" SG_ 1279 DCU_FaultData_12Bit_1 0;
BA_ "EventCommandSignal" SG_ 1279 DCU_FaultData_12Bit_1 0;
BA_ "GatewayedSignals" SG_ 1279 DCU_FaultData_16Bit_1 0;
BA_ "EventCommandSignal" SG_ 1279 DCU_FaultData_16Bit_1 0;
VAL_ 1025 BCB_BoostRlyStK3 0 "Init" 1 "Contactor is open" 2 "Contactor closed" 3 "Contactor stuck in open" 4 "Contactor stuck in closed" ;
VAL_ 1025 BCB_BoostRlyStK2 0 "Init" 1 "Contactor is open" 2 "Contactor closed" 3 "Contactor stuck in open" 4 "Contactor stuck in closed" ;
VAL_ 408 BMC_DCUBattSt 1 "HVBattCntctr_Closed;" 0 "HVBattCntctr_Open;" ;
VAL_ 408 BMC_BoostChgModeReq 3 "Reserved" 2 "CapPrecharge complete" 1 "Request;" 0 "NotRequest;" ;
VAL_ 408 BMC_PwrDwnReq 1 "Request;" 0 "NotRequest;" ;
VAL_ 408 BMC_BoostRlyK3St 0 "Init" 1 "Contactor is open" 2 "Contactor closed" 3 "Contactor stuck in open" 4 "Contactor stuck in closed" 5 "not used" 6 "not used" 7 "not used" ;
VAL_ 408 BMC_BoostRlyK2St 0 "Init" 1 "Contactor is open" 2 "Contactor closed" 3 "Contactor stuck in open" 4 "Contactor stuck in closed" 5 "not used" 6 "not used" 7 "not used" ;
VAL_ 408 BMC_DriveBoostRlyK3Sts 1 "Close;" 0 "Open;" ;
VAL_ 408 BMC_BoostRlyK3Sts 0 "Init" 1 "Contactor is open" 2 "Contactor closed" 3 "Contactor stuck in open" 4 "Contactor stuck in closed" ;
VAL_ 408 BMC_DriveBoostRlyK2Sts 1 "Close;" 0 "Open;" ;
VAL_ 408 BMC_BoostRlyK2Sts 0 "Init" 1 "Contactor is open" 2 "Contactor closed" 3 "Contactor stuck in open" 4 "Contactor stuck in closed" ;
VAL_ 888 BMC_SepaHeatSt 2 "separating;" 1 "separate heat state;" 0 "Not work;- others : reserved;" ;
VAL_ 1095 BMC_RlyK3Req 0 "Init" 1 "Open" 2 "Close" 3 "Reserved" ;
VAL_ 1095 BMC_MainloopDischgReq 0 "No request" 1 "Loop1 Dischg" 2 "Loop2 Dischg" 3 "Reserved" ;
VAL_ 1095 BMC_C2DisChgSt 0 "Default" 1 "Dischg done" 2 "Dischg undone" 3 "Reserved" ;
VAL_ 1095 BMC_BoostChgSt 0 "Not work" 1 "Work" 2 "Reserved" 3 "Reserved" ;
VAL_ 1095 BMC_RlyK2Req 0 "Init" 1 "Open" 2 "Close" 3 "Reserved" ;
VAL_ 812 BMS_BoostChgModeReq 0 "No request" 1 "Request" 2 "Quit" 3 "Reserved" ;
VAL_ 1377 BMC_NMCBV 0 "Node has not woken up the    network(passive wakeup);" 1 "Node has woken up the network(active wakeup)" 0 "NM PDU contains no Partial Network request information" 1 "NM PDU contains Partial Network request information" ;
VAL_ 1377 BMC_NMWakeupOrigin 1 "Message wakeup" 19 "Wakeup by selft" ;
VAL_ 1377 BMC_PNCInformation0 0 "No request" 1 "Request" 0 "No request" 1 "Request" 0 "No request" 1 "Request" 0 "No request" 1 "Request" ;
VAL_ 616 UMM_UsageModeSt 0 "Standby" 1 "Comfort" 2 "Reserved" 3 "DRV" 4 "Reserved" 5 "Reserved" 6 "Reserved" 7 "Invalid" ;
VAL_ 616 VMM_LastVehModeSt 0 "Normal Mode" 1 "Manufacture Mode" 2 "Transport Mode" 3 "Showroom Mode" 4 "PostCrash Mode" 5 "Maintenance Mode" 6 "Reserved" 7 "Reserved" 8 "Reserved" 9 "Reserved" 10 "Reserved" 11 "Reserved" 12 "Reserved" 13 "Reserved" 14 "Reserved" 15 "Invalid Value" ;
VAL_ 616 VMM_VehModeSt 0 "Normal Mode" 1 "Manufacture Mode" 2 "Transport Mode" 3 "Showroom Mode" 4 "PostCrash Mode" 5 "Maintenance Mode" 6 "Reserved" 7 "Reserved" 8 "Reserved" 9 "Reserved" 10 "Reserved" 11 "Reserved" 12 "Reserved" 13 "Reserved" 14 "Reserved" 15 "Invalid Value" ;
VAL_ 616 VMM_OTAModeSt 0 "NonOTA Mode" 1 "OTA Mode" 2 "Invalid Value" 3 "reserved" ;
VAL_ 816 HVAC_CorrectedExterTempVD 0 "Not valid" 1 "Valid" ;
VAL_ 816 HVAC_PTCSt 0 "NO OFF& downshift" 1 "OFF or downshift" ;
VAL_ 816 HVAC_PTCOnReq 0 "Reserve" 1 "PTC off" 2 "PTC on" 3 "Reserve" ;
VAL_ 615 BCS_FLWheelSpdVD 0 "Not valid" 1 "Valid" ;
VAL_ 615 BCS_FRWheelSpdVD 0 "Not valid" 1 "Valid" ;
VAL_ 615 BCS_RLWheelSpdVD 0 "Not valid" 1 "Valid" ;
VAL_ 615 BCS_RRWheelSpdVD 0 "Not valid" 1 "Valid" ;
VAL_ 615 BCS_HDCCtrlSt 0 "Off" 1 "On active braking" 2 "On not active braking" 3 "Not used" ;
VAL_ 615 BCS_HHCCtrlSt 0 "Not active" 1 "Active" ;
VAL_ 615 BCS_AVHSt 0 "Not active" 1 "Active" ;
VAL_ 615 IPB_PlungerPressureSt 0 "Valid/Init" 1 "Invalid/Default" ;
VAL_ 615 IPB_InputRodStrokeSt 0 "Valid/Init" 1 "Invalid/Default" ;
VAL_ 352 BCS_EBDActiveSt 0 "Not active" 1 "Active" ;
VAL_ 352 BCS_VDCFaultSt 0 "Not fault" 1 "Fault" ;
VAL_ 352 BCS_VDCActiveSt 0 "Not active" 1 "Active" ;
VAL_ 352 BCS_TCSFaultSt 0 "Not fault" 1 "Fault" ;
VAL_ 352 BCS_TCSActiveSt 0 "Not active" 1 "Active" ;
VAL_ 352 BCS_ABSFaultSt 0 "Not fault" 1 "Fault" ;
VAL_ 352 BCS_ABSActiveSt 0 "Not active" 1 "Active" ;
VAL_ 352 BCS_EBDFaultSt 0 "Not fault" 1 "Fault" ;
VAL_ 352 BCS_EngTorqDecActiveSt 0 "Not active" 1 "Active" ;
VAL_ 352 BCS_RegenModuleActive 0 "Not Active" 1 "Active" ;
VAL_ 352 BCS_DMCCtrModeFA 0 "ModeDMC_Off" 1 "ModeDMC_Rpm" 2 "ModeDMC_Trq" ;
VAL_ 352 BCS_DMCCtrModeRA 0 "ModeDMC_Off" 1 "ModeDMC_Rpm" 2 "ModeDMC_Trq" ;
VAL_ 352 BCS_EngTorqDecActiveStRA 0 "Not active" 1 "Active" ;
VAL_ 363 EPS_SteeringAngleVD 0 "Not valid" 1 "Valid" ;
VAL_ 351 ACU_ACChgCurCfg 0 "No commandï¿½ï¿½" 1 "4Aï¿½ï¿½" 2 "8Aï¿½ï¿½" 3 "12Aï¿½ï¿½" 4 "16Aï¿½ï¿½" 5 "20Aï¿½ï¿½" 6 "24Aï¿½ï¿½" 7 "28Aï¿½ï¿½" 8 "32Aï¿½ï¿½" 9 "reserved" 10 "reserved" 11 "reserved" 12 "reserved" 13 "reserved" 14 "reserved" 15 "reserved" 16 "reserved" 17 "reserved" 18 "reserved" 19 "reserved" 20 "reserved" 21 "reserved" 22 "reserved" 23 "reserved" 24 "reserved" 25 "reserved" 26 "reserved" 27 "reserved" 28 "reserved" 29 "reserved" 30 "reserved" 31 "reserved" ;
VAL_ 1359 CCU_NMCBV 0 "Node has not woken up the    network(passive wakeup);" 1 "Node has woken up the network(active wakeup)" 0 "NM PDU contains no Partial Network request information" 1 "NM PDU contains Partial Network request information" ;
VAL_ 1359 CCU_PNCInformation0 0 "No request" 1 "Request" 0 "No request" 1 "Request" 0 "No request" 1 "Request" 0 "No request" 1 "Request" 0 "No request" 1 "Request" ;
VAL_ 290 IPDS_RearEOPPowerSup 0 "Not Active" 1 "Active" 2 "PreOFF" 3 "Invalid" ;
VAL_ 290 IPDS_KL15T1PowerSup 0 "Not Active" 1 "Active" 2 "PreOFF" 3 "Invalid" ;
VAL_ 290 IPDS_BCBPowerSup 0 "Not Active" 1 "Active" 2 "PreOFF" 3 "Invalid" ;
VAL_ 290 IPDS_FrontEOPPowerSup 0 "Not Active" 1 "Active" 2 "PreOFF" 3 "Invalid" ;
VAL_ 909 EPB_ActuatorSt_L 0 "PbcActuatorState_Applied" 1 "PbcActuatorState_Released" 2 "PbcActuatorState_Applying" 3 "PbcActuatorState_Releasing" 4 "PbcActuatorState_Unknown" 5 "PbcActuatorState_HoldApplied" 6 "PbcActuatorState_CompletelyReleased" 7 "Not used" 8 "Not used" 9 "Not used" 10 "Not used" 11 "Not used" 12 "Not used" 13 "Not used" 14 "Not used" 15 "Not used" ;
VAL_ 909 EPB_ActuatorSt_R 0 "PbcActuatorState_Applied" 1 "PbcActuatorState_Released" 2 "PbcActuatorState_Applying" 3 "PbcActuatorState_Releasing" 4 "PbcActuatorState_Unknown" 5 "PbcActuatorState_HoldApplied" 6 "PbcActuatorState_CompletelyReleased" 7 "Not used" 8 "Not used" 9 "Not used" 10 "Not used" 11 "Not used" 12 "Not used" 13 "Not used" 14 "Not used" 15 "Not used" ;
VAL_ 909 EPB_SysSt 0 "Release (fully released)" 1 "Apply (fully applied)" 2 "Releasing" 3 "Applying" 4 "Disengaged" 5 "Not used" 6 "Not used" 7 "Fault(not sure position)" ;
VAL_ 902 IPDS_RearMotorPowerSt 0 "Not Active" 1 "Active" ;
VAL_ 902 IPDS_RearEOPPowerSt 0 "Not Active" 1 "Active" ;
VAL_ 902 IPDS_RearMotorPowerFaultSt 0 "Normal" 1 "Circuit short to ground" 2 "Circuit short to battery" 3 "Open" 4 "Overpower" 5 "Reserve" 6 "Reserve" 7 "Reserve" ;
VAL_ 902 IPDS_RearEOPPowerFaultSt 0 "Normal" 1 "Circuit short to ground" 2 "Circuit short to battery" 3 "Open" 4 "Overpower" 5 "Reserve" 6 "Reserve" 7 "Reserve" ;
VAL_ 902 IPDS_KL15T1PowerSt 0 "Not Active" 1 "Active" ;
VAL_ 902 IPDS_BCBPowerFaultSt 0 "Normal" 1 "Circuit short to ground" 2 "Circuit short to battery" 3 "Open" 4 "Overpower" 5 "Reserve" 6 "Reserve" 7 "Reserve" ;
VAL_ 902 IPDS_BCBPowerSt 0 "Not Active" 1 "Active" ;
VAL_ 1291 DCDC_NMCBV 0 "Node has not woken up the    network(passive wakeup);" 1 "Node has woken up the network(active wakeup)" 0 "NM PDU contains no Partial Network request information" 1 "NM PDU contains Partial Network request information" ;
VAL_ 1291 DCDC_NMWakeupOrigin 1 "Message wakeup" ;
VAL_ 1291 DCDC_PNCInformation0 0 "No request" 1 "Request" 0 "No request" 1 "Request" 0 "No request" 1 "Request" 0 "No request" 1 "Request" ;
VAL_ 1308 DCDC2_NMCBV 0 "Node has not woken up the    network(passive wakeup);" 1 "Node has woken up the network(active wakeup)" 0 "NM PDU contains no Partial Network request information" 1 "NM PDU contains Partial Network request information" ;
VAL_ 1308 DCDC2_NMWakeupOrigin 1 "Message wakeup" ;
VAL_ 1308 DCDC2_PNCInformation0 0 "No request" 1 "Request" 0 "No request" 1 "Request" 0 "No request" 1 "Request" 0 "No request" 1 "Request" ;
VAL_ 368 DCU_CCUEOPPowerSup 0 "Reserved" 1 "No active" 2 "Active" 3 "Reserved" ;
VAL_ 368 DCU_ModeSt 15 "Emer_Discharge;" 14 "CapDischarge;" 13 "BuckDischarge;" 12 "Boost Charge;" 11 "CapPrecharge;" 10 "Power off;" 9 "Offsetcal;" 8 "Failure;" 7 "Afterrun;" 6 "Discharge;" 5 "HillholdCtrl;" 4 "TrqCtrl;" 3 "Ready;" 2 "Standby;" 1 "Init;" 0 "Reserved;" ;
VAL_ 368 DCU_HvilSt 3 "Failure;" 2 "HVIL is interrupted;" 1 "HVIL is closed;" 0 "HVIL generator is ready but HVIL result is not available;" ;
VAL_ 368 DCU_DMCInternalInputQF 1 "Ture" 0 "False" ;
VAL_ 368 DCU_DstActive 1 "Active;" 0 "No Active;" ;
VAL_ 368 DCU_GateDrvSt 3 "ShortCircuit;" 2 "Discharge;" 1 "PWMrun;" 0 "FreeWheel;" ;
VAL_ 368 DCU_DMCInternalInit 1 "Initilize OK;" 0 "Initilize NOK;" ;
VAL_ 368 DCU_DMCOperationStToBCS 3 "DMC Fault" 2 "DMC Off" 1 "DMC On" 0 "DMC Init" ;
VAL_ 368 DCU_EOP_SpdSet 0 "Init" 149 "Error" ;
VAL_ 368 DCU_TrefFinal 0 "Init" 149 "Error" ;
VAL_ 864 DCU_OffsetCalInd 1 "Calibration succeeded;" 0 "Default / nok;" ;
VAL_ 864 DCU_bReadyHV 1 "Active;" 0 "No Active;" ;
VAL_ 864 DCU_bDiagReq 1 "Active;" 0 "No Active;" ;
VAL_ 864 DCU_TypeSt 2 "Type2;" 1 "Type1;" 0 "Not valid;- others : reserved;" ;
VAL_ 864 DCU_SysTempOvrInd 1 "Lamp on;" 0 "Lamp off;" ;
VAL_ 864 DCU_FaultLampInd 1 "Lamp on;" 0 "Lamp off;" ;
VAL_ 864 DCU_ErrNoticeOperationFlag 0 "No prompt" 1 "Prompt" ;
VAL_ 864 DCU_Err2NoticeFlag 0 "No prompt" 1 "Prompt" ;
VAL_ 864 DCU_ErrNotice 0 "reseved" 1 "PwrLimitlevel1" 2 "PwrLimitlevel2" 3 "Pwrloss" 4 "reseved" 5 "reseved" 6 "reseved" 7 "reseved" ;
VAL_ 864 DCU_K2RlyAdhmode 0 "OFF" 1 "ON" ;
VAL_ 864 DCU_TEL_ECUTempOvrErr 1 "Error;" 0 "No error;" ;
VAL_ 864 DCU_TEL_MotTempOvrErr 1 "Error;" 0 "No error;" ;
VAL_ 864 DCU_TEL_ModeSt 4 "Standby;" 3 "Stop;" 2 "Generate electricity;" 1 "Electricity consumed;" 0 "Reserved;" 5 "Reserved;" 6 "Reserved;" 7 "Reserved;" ;
VAL_ 864 DCU_IgnitionSt 0 "Not Active" 1 "Active" ;
VAL_ 875 DCU_PTCDownShiftSt 0 "NO off& downshift" 1 "off or downshift" ;
VAL_ 875 DCU_PTCUpShiftSt 0 "NO on& upshift" 1 "on or upshift" ;
VAL_ 875 DCU_AHFDownShiftSt 0 "NO off& downshift" 1 "off or downshift" ;
VAL_ 875 DCU_AHFUpShiftSt 0 "NO on& upshift" 1 "on or upshift" ;
VAL_ 875 DCU_PTCModeSt 1 "initial" 2 "standby" 4 "working" 8 "failure" ;
VAL_ 875 DCU_AHFModeSt 1 "initial" 2 "standby" 3 "static heating" 4 "dynamic heating" 8 "failure" ;
VAL_ 384 EOP_ErrLevel 7 "reserved" 6 "reserved" 5 "reserved" 4 "Error unable to work" 3 "communication fail EOP is able to work following the strategy of itself" 2 "Error but still can work limit the EOP power as 50% or less (TBD)" 1 "Error but still can work" 0 "Normal" ;
VAL_ 384 EOP_Status 0 "Systme_Sta_Init" 1 "Systme_SelfCheck_Failure" 2 "Systme_Sta_Stand_By" 3 "Systme_Sta_Motor_Run" 4 "Systme_Sta_Failure" ;
VAL_ 599 EVCC_S2_Drive 0 "Undriven" 1 "Driven" ;
VAL_ 599 EVCC_OBC_CpFreqSt 0 "The frequency is beyond 900Hz to 1100Hz" 1 "The frequency is between 900Hz to 1100Hz" ;
VAL_ 599 EVCC_CCOUT_Drive 0 "Undriven" 1 "Driven" ;
VAL_ 599 EVCC_lostECAN 0 "ECAN no lost" 1 "ECAN lost" ;
VAL_ 1533 EVCC_NMCBV 0 "Node has not woken up the    network(passive wakeup);" 1 "Node has woken up the network(active wakeup)" 0 "NM PDU contains no Partial Network request information" 1 "NM PDU contains Partial Network request information" ;
VAL_ 1533 EVCC_NMWakeupOrigin 1 "Message wakeup" 19 "Wakeup by selft" ;
VAL_ 1533 EVCC_PNCInformation0 0 "No request" 1 "Request" 0 "No request" 1 "Request" 0 "No request" 1 "Request" 0 "No request" 1 "Request" ;
VAL_ 704 IPS_KL15State 0 "Off;" 1 "On;" ;
VAL_ 704 IPS_DCDCModeSt 7 "Failure;" 3 "Active - Buck Mode;" 2 "Connected (HV is active);" 1 "Disconnected;" 0 "Init;- others : reserved;" ;
VAL_ 704 IPS_OBCCC_St 7 "failure;" 6 "charger connected(European standard charging);" 5 "Connected DC charing(European standard charging);" 4 "Connected V2L;" 2 "Connected charging/ V2V;" 1 "half connected charging/ V2V/ V2L;" 0 "disconnected;- others : reserved;" ;
VAL_ 704 IPS_OBCCpFreqSt 1 "The frequency is between 950HZ and 1050HZ;" 0 "The frequency is beyond 950HZ and 1050HZ;" ;
VAL_ 704 IPS_OBCDschDisable 1 "CP Duty&Frequency&Volt is OK;" 0 "CP state is not oK;" ;
VAL_ 704 IPS_OBCModeSt 7 "Failure;" 6 "Heating;" 5 "Active -? V2V discharging;" 4 "Active - V2L discharging;" 3 "Active - Charging;" 2 "Connected (HV is active);" 1 "Disconnected;" 0 "Init;" ;
VAL_ 704 IPS_OBCCPSt 1 "CP Duty&Frequency&Volt is OK;" 0 "CP state is not oK;" ;
VAL_ 704 IPS_OBCCC_Cap 4 "64A;" 3 "32A;" 2 "16A;" 1 "10A;" 0 "Not valid;- others : reserved;" ;
VAL_ 704 IPS_OBCCpS2St 1 "S2 is on;" 0 "S2 is off;" ;
VAL_ 872 IPS_TEL_DCDCTempOvrErr 1 "Error;" 0 "OK;" ;
VAL_ 872 IPS_TEL_DCDCFaultLampInd 1 "Lamp on;" 0 "Lamp off;" ;
VAL_ 872 IPS_HwSt 0 "DCDC" 1 "IPS" 2 "Bi-IPS" 3 "Bi-DCDC" 4 "Reserved" 5 "Reserved" ;
VAL_ 872 IPS_DCDCFaultLampInd 0 "No prompt" 1 "Prompt" ;
VAL_ 872 IPS_TEL_DCDCModeSt 2 "OFF;" 1 "Buck;" 0 "Init;- others : reserved;" ;
VAL_ 872 IPS_HVDCHVilSt 3 "Failure;" 2 "HVIL is interrupted;" 1 "HVIL is closed;" 0 "HVIL generator is ready but HVIL result is not available;" ;
VAL_ 872 IPS_OBCFaultLampInd 0 "No prompt" 1 "Prompt" ;
VAL_ 872 IPS_ChgCurRespAvail 0 "Not available" 1 "Available" ;
VAL_ 872 IPS_ChgCurResp 0 "Defaultï¿½ï¿½" 1 "4Aï¿½ï¿½" 2 "8Aï¿½ï¿½" 3 "12Aï¿½ï¿½" 4 "16Aï¿½ï¿½" 5 "20Aï¿½ï¿½" 6 "24Aï¿½ï¿½" 7 "28Aï¿½ï¿½" 8 "32Aï¿½ï¿½" ;
VAL_ 872 IPS_ACHvilSt 3 "Failure;" 2 "HVIL is interrupted;" 1 "HVIL is closed;" 0 "HVIL generator is ready but HVIL result is not available;" ;
VAL_ 872 IPS_OBCFaultLampIndOperationFlag 0 "No prompt" 1 "Prompt" ;
VAL_ 872 IPS_DCDCFaultLampIndFlag 0 "No prompt" 1 "Prompt" ;
VAL_ 872 IPS_DCDCFaultLampIndOperationFla 0 "No prompt" 1 "Prompt" ;
VAL_ 2683306000 IPS_TEL_DCDCFaultLampInd2 0 "Actual Value" 1 "ManCal Dcdc Output Short" ;
VAL_ 2683306000 IPS_TEL_DCDCTempOvrErr2 0 "Actual Value" 1 "ManCal Dcdc Otp" ;
VAL_ 2683306000 IPS_Disable_CC 5 "10A" 4 "63A" 3 "V2L" 2 "16A" 0 "Actual Value" 1 "32A" ;
VAL_ 2683306000 IPS_Disable_CP 0 "Actual Value" 1 "ManCal Cp OK(6V&53.3%&1KHz);" ;
VAL_ 2683306000 IPS_Disable_RCChecksum 0 "Actual Value" 1 "ManCal Shield ComErr" ;
VAL_ 2683306000 IPS_DCDCSet 0 "No Replace" 1 "Replace" ;
VAL_ 2683306000 IPS_OBCSet 0 "No Replace" 1 "Replace" ;
VAL_ 2683306000 IPS_OBCHvVoltLimSet 0 "Disable" 1 "Enable" ;
VAL_ 880 ITS_EMVSt 3 "Reserved" ;
VAL_ 880 ITS_ValvePositionAct 0 "reserve" 1 "position 1" 2 "position 2" 3 "position 3" 4 "position 4" 5 "position 5" 6 "position 6" 7 "position 7" 8 "position 8" 9 "position 9" 10 "position 10" 11 "position 11" 12 "position 12" ;
VAL_ 880 ITS_MotorInletTempErr 0 "No error;" 1 "Error;" ;
VAL_ 880 ITS_MotorInletTemp 3050 "Invalid Value" ;
VAL_ 880 ITS_BatteryInletTemp 3050 "Invalid Value" ;
VAL_ 880 ITS_ChillerInletTemp 3050 "Invalid Value" ;
VAL_ 1410 ITS_NMCBV 0 "Node has not woken up the    network(passive wakeup);" 1 "Node has woken up the network(active wakeup)" 0 "NM PDU contains no Partial Network request information" 1 "NM PDU contains Partial Network request information" ;
VAL_ 1410 ITS_NMWakeupOrigin 1 "Message wakeup" ;
VAL_ 1410 ITS_PNCInformation0 0 "No request" 1 "Request" 0 "No request" 1 "Request" 0 "No request" 1 "Request" 0 "No request" 1 "Request" ;
VAL_ 1406 NIDU_NMCBV 0 "Node has not woken up the    network(passive wakeup);" 1 "Node has woken up the network(active wakeup)" 0 "NM PDU contains no Partial Network request information" 1 "NM PDU contains Partial Network request information" ;
VAL_ 1406 NIDU_NMWakeupOrigin 1 "Message wakeup" 18 "KL15 wakeup" ;
VAL_ 1406 NIDU_PNCInformation0 0 "No request" 1 "Request" 0 "No request" 1 "Request" 0 "No request" 1 "Request" 0 "No request" 1 "Request" ;
VAL_ 818 TMS_MotorLoopEstimatedFlowVD 1 "Valid" 0 "Invaild" ;
VAL_ 818 TMS_DiagMTPump 1 "Fault;" 0 "Normal;- others : reserved;" ;
VAL_ 818 TMS_DiagLTPump 1 "Fault;" 0 "Normal;- others : reserved;" ;
VAL_ 818 TMS_AHFOnReq 0 "Reserve" 1 "AHF off" 2 "AHF on" 3 "Reserve" ;
VAL_ 818 TMS_AHFSt 0 "NO off& downshift" 1 "off or downshift" ;
VAL_ 392 EMS_GasPedalActPstforMRRVD_E 1 "Valid" 0 "Invalid" ;
VAL_ 392 VCU_DCU_SurgeDamperStReq 2 "DstC_int_ext;" 1 "DstC_ext;" 0 "DstC_off;- others : reserved;" ;
VAL_ 392 VCU_CrntGearLvl 4 "'P' Park gear;" 3 "'R' Reverse gear;" 2 "'N' Neutral gear;" 1 "'D' Drive gear;" 0 "Invalid;- others : reserved;" ;
VAL_ 392 VCU_HvilSt 3 "Failure;" 2 "HVIL is interrupted;" 1 "HVIL is closed;" 0 "HVIL generator is ready but HVIL result is not available;" ;
VAL_ 392 VCU_DCU_ModeReq 15 "Emer_Discharge;" 14 "Cap2Discharge;" 13 "BuckDischarge;" 12 "Boost Charge;" 11 "Reserved;" 10 "Cap2Precharge;" 9 "Offsetcal;" 8 "Reserved;" 7 "Reserved;" 6 "Discharge;" 5 "HillholdCtrl;" 4 "TrqCtrl;" 3 "Ready;" 2 "Standby;" 1 "Init;" 0 "Reserved;" ;
VAL_ 392 VCU_IPS_OBCModeReq 4 "Heating;" 3 "Discharging;" 2 "Charging;" 1 "Standby;" 0 "no request;- others : reserved;" ;
VAL_ 392 VCU_BrkPedPstVD_E 1 "Valid" 0 "Not valid" ;
VAL_ 392 VCU_BMS_SepaHeatEn 1 "Enable;" 0 "Disable;" ;
VAL_ 392 VCU_IPS_DCDCModeReq 4 "Service_General;" 2 "Buck Mode request;" 1 "Standby requested - No power conversion;" 0 "no request, sleep indication allowed;- others : reserved;" ;
VAL_ 824 VCU_PlgConnSt 1 "Plug connector connected;" 0 "Not connected;" ;
VAL_ 824 VCU_SwapHvBattModeStVD 0 "Not valid" 1 "Valid" ;
VAL_ 824 VCU_SwapHvBattModeSt 0 "Invalid" 1 "Not Swap mode" 2 "Swap mode" 3 "Swap mode (Hv power down)" ;
VAL_ 952 VCU_MotorLoopEstimatedFlowVD 0 "reservedï¿½ï¿½" 1 "thermal system is normal, the estimated flow of the motor loop is validï¿½ï¿½" 2 "thermal system error,the estimated flow accuracy of the motor loop can not been guaranteed" 3 "thermal system error,the flow of the motor loop can not been estimated" ;
VAL_ 952 VCU_EM3To2ValveEn 1 "Enable;" 0 "Disable;" ;
VAL_ 952 VCU_DiagLTPump 1 "Fault;" 0 "Normal;- others : reserved;" ;
VAL_ 952 VCU_DiagMTPump 1 "Fault;" 0 "Normal;- others : reserved;" ;
VAL_ 930 VCU_BoostChgMode 0 "Not Enable" 1 "Enable" ;
VAL_ 930 VCU_K2RlyAdhDetn 0 "No request" 1 "Request" ;
VAL_ 930 VCU_CCUBCBPowerSup 0 "Not Active" 1 "Active" ;
VAL_ 930 VCU_TMS_AHFDelayEn 0 "Disable delay" 1 "Enable delay" ;
VAL_ 930 VCU_TMS_AHFShutImme 0 "No request" 1 "immediate shutdown" ;
VAL_ 930 VCU_TMS_AHFActivationSt 0 "AHF inactive" 1 "Drive AHF active" 2 "Rengen AHF active" 3 "Dissipative AHF active" 4 "Reserved" 5 "Reserved" 6 "Reserved" 7 "Reserved" ;
